VERSION ""

NS_ :

BS_:

BU_: L_3HKBD L_FHPTC L_ATCU L_2HKBD L_PCM L_HKBD L_RHPTC

BO_ 3221225472 VECTOR__INDEPENDENT_SIG_MSG: 0 Vector__XXX
 SG_ L_2HKBD_RrDrModeBiLvlSw : 0|1@1+ (1,0) [0|0] "" Vector__XXX
 SG_ L_2HKBD_RrDrTempDnSw : 0|1@1+ (1,0) [0|0] "" Vector__XXX
 SG_ L_2HKBD_RrDrTempUpSw : 0|1@1+ (1,0) [0|0] "" Vector__XXX
 SG_ L_2HKBD_RrDrBlwDnSw : 0|1@1+ (1,0) [0|0] "" Vector__XXX
 SG_ L_2HKBD_RrDrBlwUpSw : 0|1@1+ (1,0) [0|0] "" Vector__XXX
 SG_ L_2HKBD_RrFlrDuctSnsr : 0|8@1+ (0.02,0) [0|0] "V" Vector__XXX
 SG_ L_2HKBD_RrVntDuctSnsr : 0|8@1+ (0.02,0) [0|0] "V" Vector__XXX
 SG_ L_ATCU_Typ1 : 0|4@1+ (1,0) [0|0] "" Vector__XXX
 SG_ L_ATCU_Opt1 : 0|8@1+ (1,0) [0|0] "" Vector__XXX
 SG_ L_ATCU_Drv_SeatOptSta : 0|3@1+ (1,0) [0|0] "" Vector__XXX
 SG_ L_ATCU_Ast_SeatOptSta : 0|3@1+ (1,0) [0|0] "" Vector__XXX
 SG_ L_ATCU_RL_SeatOptSta : 0|3@1+ (1,0) [0|0] "" Vector__XXX
 SG_ L_ATCU_RR_SeatOptSta : 0|3@1+ (1,0) [0|0] "" Vector__XXX
 SG_ L_ATCU_Typ2 : 0|4@1+ (1,0) [0|0] "" Vector__XXX
 SG_ L_ATCU_Typ3 : 0|8@1+ (1,0) [0|0] "" Vector__XXX
 SG_ L_2HKBD_Rr_EvapVolVal : 0|8@1+ (0.02,0) [0|0] "" Vector__XXX
 SG_ L_2HKBD_Rr_TempActrSt : 0|2@1+ (1,0) [0|0] "" Vector__XXX
 SG_ L_2HKBD_Rr_TempAsstActrFB : 0|10@1+ (1,0) [0|0] "" Vector__XXX
 SG_ L_2HKBD_Rr_TempAsstActrSt : 0|2@1+ (1,0) [0|0] "" Vector__XXX
 SG_ L_2HKBD_Rr_ModeActrFB : 0|10@1+ (1,0) [0|0] "" Vector__XXX
 SG_ L_2HKBD_Rr_ModeActrSt : 0|2@1+ (1,0) [0|0] "" Vector__XXX
 SG_ L_2HKBD_Rr_BLDCError : 0|4@1+ (1,0) [0|0] "" Vector__XXX
 SG_ L_2HKBD_Rr_HVACBLDCRpmFB : 0|16@1+ (5,0) [0|0] "RPM" Vector__XXX
 SG_ L_2HKBD_Rr_TempActrFB : 0|10@1+ (1,0) [0|0] "" Vector__XXX
 SG_ L_ATCU_3rdRrTempCDis : 0|8@1+ (0.5,14) [0|0] "¡É" Vector__XXX
 SG_ L_ATCU_3rdRrModDis : 0|4@1+ (1,0) [0|0] "" Vector__XXX
 SG_ L_ATCU_3rdRrBlwDis : 0|4@1+ (1,0) [0|0] "" Vector__XXX
 SG_ L_ATCU_3rdRrAutoDis : 0|2@1+ (1,0) [0|0] "" Vector__XXX
 SG_ L_ATCU_3rdRrMultiAutoBlwDis : 0|3@1+ (1,0) [0|0] "" Vector__XXX
 SG_ L_ATCU_3rdRrSyncDis : 0|2@1+ (1,0) [0|0] "" Vector__XXX
 SG_ L_ATCU_3rdRrOnInd : 0|2@1+ (1,0) [0|0] "" Vector__XXX
 SG_ L_ATCU_3rdRrLockDis : 0|2@1+ (1,0) [0|0] "" Vector__XXX
 SG_ L_ATCU_3rdRrLcdBckLightSta : 0|1@1+ (1,0) [0|0] "" Vector__XXX
 SG_ L_ATCU_3rdRrGUIBlankDis : 0|1@1+ (1,0) [0|0] "" Vector__XXX
 SG_ L_ATCU_3rdRLStHeatSwHInd : 0|1@1+ (1,0) [0|0] "" Vector__XXX
 SG_ L_ATCU_3rdRLStHeatSwMInd : 0|1@1+ (1,0) [0|0] "" Vector__XXX
 SG_ L_ATCU_3rdRLStHeatSwLInd : 0|1@1+ (1,0) [0|0] "" Vector__XXX
 SG_ L_ATCU_3rdRLStVntSwHInd : 0|1@1+ (1,0) [0|0] "" Vector__XXX
 SG_ L_ATCU_3rdRLStVntSwMInd : 0|1@1+ (1,0) [0|0] "" Vector__XXX
 SG_ L_ATCU_3rdRLStVntSwLInd : 0|1@1+ (1,0) [0|0] "" Vector__XXX
 SG_ L_ATCU_3rdRRStHeatSwHInd : 0|1@1+ (1,0) [0|0] "" Vector__XXX
 SG_ L_ATCU_3rdRRStHeatSwMInd : 0|1@1+ (1,0) [0|0] "" Vector__XXX
 SG_ L_ATCU_3rdRRStHeatSwLInd : 0|1@1+ (1,0) [0|0] "" Vector__XXX
 SG_ L_ATCU_3rdRRStVntSwHInd : 0|1@1+ (1,0) [0|0] "" Vector__XXX
 SG_ L_ATCU_3rdRRStVntSwMInd : 0|1@1+ (1,0) [0|0] "" Vector__XXX
 SG_ L_ATCU_3rdRRStVntSwLInd : 0|1@1+ (1,0) [0|0] "" Vector__XXX
 SG_ L_ATCU_3rdRrMTCOpSta : 0|2@1+ (1,0) [0|0] "" Vector__XXX
 SG_ L_ATCU_3rdRrMtcTempLvl : 0|4@1+ (1,0) [0|0] "" Vector__XXX
 SG_ L_ATCU_3rdAUTOStep : 0|3@1+ (1,0) [0|0] "" Vector__XXX
 SG_ L_ATCU_RrPassMultiAutoBlwDis : 0|3@1+ (1,0) [0|0] "" Vector__XXX
 SG_ L_ATCU_3rdRrTempFDis : 0|8@1+ (1,56) [0|0] "¢µ" Vector__XXX
 SG_ L_2HKBD_SwBtnTyp : 0|20@1+ (1,0) [0|0] "" Vector__XXX
 SG_ L_ATCU_RrHVACTempActrTgt : 0|10@1+ (1,0) [0|0] "AD" Vector__XXX
 SG_ L_ATCU_RrHVACTempAsstActrTgt : 0|10@1+ (1,0) [0|0] "AD" Vector__XXX
 SG_ L_ATCU_RrHVACModeActrTgt : 0|10@1+ (1,0) [0|0] "AD" Vector__XXX
 SG_ L_ATCU_RrHVACBlowerTgtV : 0|8@1+ (0.1,0) [0|0] "V" Vector__XXX
 SG_ L_ATCU_RrHVACBLDCRpmVal : 0|16@1+ (5,0) [0|0] "RPM" Vector__XXX
 SG_ L_ATCU_RrHVACDiagBlwOn : 0|1@1+ (1,0) [0|0] "" Vector__XXX
 SG_ L_ATCU_RrHVACTempActrOpSta : 0|1@1+ (1,0) [0|0] "" Vector__XXX
 SG_ L_ATCU_RrHVACTempAsstActrOpSta : 0|1@1+ (1,0) [0|0] "" Vector__XXX
 SG_ L_ATCU_RrHVACModActrOpSta : 0|1@1+ (1,0) [0|0] "" Vector__XXX
 SG_ L_ATCU_ArClnIntroEvt : 0|1@1+ (1,0) [0|0] "" Vector__XXX
 SG_ L_ATCU_ArClnSmblClr : 0|4@1+ (1,0) [0|0] "" Vector__XXX
 SG_ L_ATCU_DustLevelDis : 0|3@1+ (1,0) [0|0] "" Vector__XXX
 SG_ L_ATCU_DustBarDisOff : 0|1@1+ (1,0) [0|0] "" Vector__XXX
 SG_ L_ATCU_DustSnrStepDis : 0|6@1+ (1,0) [0|0] "" Vector__XXX
 SG_ L_ATCU_FragStrhDis : 0|2@1+ (1,0) [0|0] "" Vector__XXX
 SG_ L_ATCU_FragKindDis : 0|3@1+ (1,0) [0|0] "" Vector__XXX
 SG_ L_ATCU_Frag1Inform : 0|4@1+ (1,0) [0|0] "" Vector__XXX
 SG_ L_ATCU_Frag2Inform : 0|4@1+ (1,0) [0|0] "" Vector__XXX
 SG_ L_ATCU_Frag1RemainDisp : 0|4@1+ (1,0) [0|0] "" Vector__XXX
 SG_ L_ATCU_Frag2RemainDisp : 0|4@1+ (1,0) [0|0] "" Vector__XXX
 SG_ L_ATCU_ArClnSmblTyp : 0|4@1+ (1,0) [0|0] "" Vector__XXX
 SG_ L_ATCU_FrtBlwMaxLvlVaild : 0|4@1+ (1,0) [0|0] "" Vector__XXX
 SG_ L_ATCU_OpSta : 0|3@1+ (1,0) [0|0] "" Vector__XXX
 SG_ L_ATCU_TempDispUnit : 0|2@1+ (1,0) [0|0] "" Vector__XXX
 SG_ L_ATCU_DrvAUTOStep : 0|4@1+ (1,0) [0|0] "" Vector__XXX
 SG_ L_ATCU_DiagCodeDis : 0|10@1+ (1,-1) [0|0] "" Vector__XXX
 SG_ L_2HKBD_Sw_Opt1 : 0|8@1+ (1,0) [0|0] "" Vector__XXX
 SG_ L_2HKBD_Typ2 : 0|8@1+ (1,0) [0|0] "" Vector__XXX
 SG_ L_2HKBD_Typ3 : 0|8@1+ (1,0) [0|0] "" Vector__XXX
 SG_ L_2HKBD_Typ1 : 0|8@1+ (1,0) [0|0] "" Vector__XXX
 SG_ L_ATCU_RrOpSta : 0|3@1+ (1,0) [0|0] "" Vector__XXX
 SG_ L_ATCU_RrDrvTempFDis : 0|8@1+ (1,56) [0|0] "¢µ" Vector__XXX
 SG_ L_ATCU_RrDrvModDis : 0|4@1+ (1,0) [0|0] "" Vector__XXX
 SG_ L_ATCU_RrDrvBlwDis : 0|4@1+ (1,0) [0|0] "" Vector__XXX
 SG_ L_ATCU_RrDrvAutoDis : 0|2@1+ (1,0) [0|0] "" Vector__XXX
 SG_ L_ATCU_RrDrvMultiAutoBlwDis : 0|2@1+ (1,0) [0|0] "" Vector__XXX
 SG_ L_ATCU_RrDrvTempCDis : 0|8@1+ (0.5,14) [0|0] "¡É" Vector__XXX
 SG_ L_ATCU_RrSyncDis : 0|2@1+ (1,0) [0|0] "" Vector__XXX
 SG_ L_ATCU_RrLcdBckLightSta : 0|1@1+ (1,0) [0|0] "" Vector__XXX
 SG_ L_ATCU_RrGUIBlankDis : 0|1@1+ (1,0) [0|0] "" Vector__XXX
 SG_ L_ATCU_RLStHeatSwHInd : 0|1@1+ (1,0) [0|0] "" Vector__XXX
 SG_ L_ATCU_RLStHeatSwMInd : 0|1@1+ (1,0) [0|0] "" Vector__XXX
 SG_ L_ATCU_RLStHeatSwLInd : 0|1@1+ (1,0) [0|0] "" Vector__XXX
 SG_ L_ATCU_RLStVntSwHInd : 0|1@1+ (1,0) [0|0] "" Vector__XXX
 SG_ L_ATCU_RLStVntSwMInd : 0|1@1+ (1,0) [0|0] "" Vector__XXX
 SG_ L_ATCU_RLStVntSwLInd : 0|1@1+ (1,0) [0|0] "" Vector__XXX
 SG_ L_ATCU_RRStHeatSwHInd : 0|1@1+ (1,0) [0|0] "" Vector__XXX
 SG_ L_ATCU_RRStHeatSwMInd : 0|1@1+ (1,0) [0|0] "" Vector__XXX
 SG_ L_ATCU_RRStHeatSwLInd : 0|1@1+ (1,0) [0|0] "" Vector__XXX
 SG_ L_ATCU_RRStVntSwHInd : 0|1@1+ (1,0) [0|0] "" Vector__XXX
 SG_ L_ATCU_RRStVntSwMInd : 0|1@1+ (1,0) [0|0] "" Vector__XXX
 SG_ L_ATCU_RRStVntSwLInd : 0|1@1+ (1,0) [0|0] "" Vector__XXX
 SG_ L_ATCU_RrMTCOpSta : 0|2@1+ (1,0) [0|0] "" Vector__XXX
 SG_ L_ATCU_RrMTCTempLvl : 0|4@1+ (1,0) [0|0] "" Vector__XXX
 SG_ L_ATCU_RrPsModDis : 0|4@1+ (1,0) [0|0] "" Vector__XXX
 SG_ L_ATCU_RrLockDis : 0|2@1+ (1,0) [0|0] "" Vector__XXX
 SG_ L_ATCU_RrDrvAutoStep : 0|4@1+ (1,0) [0|0] "" Vector__XXX
 SG_ L_ATCU_PassAUTOStep : 0|3@1+ (1,0) [0|0] "" Vector__XXX
 SG_ L_ATCU_RrPassTempFDis : 0|8@1+ (1,56) [0|0] "¢µ" Vector__XXX
 SG_ L_ATCU_RrPassBlwDis : 0|4@1+ (1,0) [0|0] "" Vector__XXX
 SG_ L_ATCU_RrPassAUTODis : 0|2@1+ (1,0) [0|0] "" Vector__XXX
 SG_ L_ATCU_RrPassAUTOStep : 0|3@1+ (1,0) [0|0] "" Vector__XXX
 SG_ L_ATCU_CampModeSta : 0|2@1+ (1,0) [0|0] "" Vector__XXX
 SG_ L_ATCU_RrPassTempCDis : 0|8@1+ (0.5,14) [0|0] "¡É" Vector__XXX
 SG_ L_ATCU_UtilModeUsmSta : 0|2@1+ (1,0) [0|0] "" Vector__XXX
 SG_ L_ATCU_OutTempDispC : 0|8@1+ (0.5,-41) [0|0] "¡É" Vector__XXX
 SG_ L_ATCU_DtntOutSta : 0|1@1+ (1,0) [0|0] "" Vector__XXX
 SG_ L_ATCU_AutoBrightSta : 0|8@1+ (1,0) [0|0] "" Vector__XXX
 SG_ L_ATCU_DustSnrVal : 0|10@1+ (1,0) [0|0] "um/m3" Vector__XXX
 SG_ L_ATCU_NotMinModeBrightSta : 0|8@1+ (1,0) [0|0] "" Vector__XXX
 SG_ L_ATCU_OutTempDispF : 0|8@1+ (1,-42) [0|0] "¢µ" Vector__XXX
 SG_ L_ATCU_SW_Ver1 : 0|7@1+ (1,0) [0|0] "" Vector__XXX
 SG_ L_ATCU_SW_Ver3 : 0|7@1+ (1,0) [0|0] "" Vector__XXX
 SG_ L_ATCU_SW_Ver4 : 0|7@1+ (1,0) [0|0] "" Vector__XXX
 SG_ L_ATCU_SW_Ver5 : 0|7@1+ (1,0) [0|0] "" Vector__XXX
 SG_ L_ATCU_SW_Ver2 : 0|7@1+ (1,0) [0|0] "" Vector__XXX
 SG_ L_ATCU_RHPTCOpPrmssnSta : 0|1@1+ (1,0) [0|0] "" Vector__XXX
 SG_ L_ATCU_xEV_BMSRomTyp2 : 0|3@1+ (1,0) [0|0] "" Vector__XXX
 SG_ L_ATCU_RHPTCFlrTrgtDty : 0|8@1+ (0.5,0) [0|0] "%" Vector__XXX
 SG_ L_ATCU_RHPTCDischrgReq : 0|1@1+ (1,0) [0|0] "" Vector__XXX
 SG_ L_ATCU_FltMsgTmOutRHPTC1 : 0|1@1+ (1,0) [0|0] "" Vector__XXX
 SG_ L_ATCU_FltMsgTmOutRHPTC2 : 0|1@1+ (1,0) [0|0] "" Vector__XXX
 SG_ L_ATCU_FltMsgTmOutRHPTC3 : 0|1@1+ (1,0) [0|0] "" Vector__XXX
 SG_ L_ATCU_FltMsgTmOutRHPTC4 : 0|1@1+ (1,0) [0|0] "" Vector__XXX
 SG_ L_ATCU_RrBlwLvl : 0|4@1+ (1,0) [0|0] "" Vector__XXX
 SG_ L_ATCU_RrBlwLvlSigVaildSta : 0|8@1+ (1,0) [0|0] "" Vector__XXX
 SG_ L_ATCU_OutTempSnsrVal2 : 0|8@1+ (0.5,-40) [0|0] "¡É" Vector__XXX
 SG_ L_ATCU_RHPTCRoofTrgtDty : 0|8@1+ (0.5,0) [0|0] "%" Vector__XXX
 SG_ L_ATCU_RrBlwFltSta : 0|1@1+ (1,0) [0|0] "" Vector__XXX
 SG_ RHPTC_FlrFlt : 0|1@1+ (1,0) [0|0] "" Vector__XXX
 SG_ RHPTC_FlrFltLVLow : 0|1@1+ (1,0) [0|0] "" Vector__XXX
 SG_ RHPTC_FlrFailLVSnr : 0|1@1+ (1,0) [0|0] "" Vector__XXX
 SG_ RHPTC_FlrFailCuFLRentSnr : 0|1@1+ (1,0) [0|0] "" Vector__XXX
 SG_ RHPTC_FlrrFailCoreTempSnr : 0|1@1+ (1,0) [0|0] "" Vector__XXX
 SG_ RHPTC_FlrFailPcbTempSnr : 0|1@1+ (1,0) [0|0] "" Vector__XXX
 SG_ RHPTC_FlrFailIGBT : 0|1@1+ (1,0) [0|0] "" Vector__XXX
 SG_ RHPTC_FlrFailOpenLoad : 0|1@1+ (1,0) [0|0] "" Vector__XXX
 SG_ RHPTC_FlrLtdOpCause : 0|8@1+ (1,0) [0|0] "" Vector__XXX
 SG_ RHPTC_FlrFltLVHigh : 0|1@1+ (1,0) [0|0] "" Vector__XXX
 SG_ RHPTC_FlrSwrVer : 0|8@1+ (1,0) [0|255] "" Vector__XXX
 SG_ RHPTC_FlrFltHVLow : 0|1@1+ (1,0) [0|0] "" Vector__XXX
 SG_ RHPTC_FlrFltHVHigh : 0|1@1+ (1,0) [0|0] "" Vector__XXX
 SG_ RHPTC_FlrFltOverCuFLRent : 0|1@1+ (1,0) [0|0] "" Vector__XXX
 SG_ RHPTC_FlrFltThermalShutDn : 0|1@1+ (1,0) [0|0] "" Vector__XXX
 SG_ RHPTC_FlrFltPcbThermalShutDn : 0|1@1+ (1,0) [0|0] "" Vector__XXX
 SG_ RHPTC_FlrFltMsgTmOutATCU : 0|1@1+ (1,0) [0|0] "" Vector__XXX
 SG_ RHPTC_FlrFailHVSnr : 0|1@1+ (1,0) [0|0] "" Vector__XXX
 SG_ RHPTC_FlrRdySta : 0|1@1+ (1,0) [0|0] "" Vector__XXX
 SG_ RHPTC_FlrOpSta : 0|2@1+ (1,0) [0|0] "" Vector__XXX
 SG_ RHPTC_FlrCnsmptPwr_W : 0|16@1+ (1,0) [0|10000] "W" Vector__XXX
 SG_ RHPTC_FlrCtrlTyp : 0|4@1+ (1,0) [0|0] "" Vector__XXX
 SG_ RHPTC_FlrVoltage_V : 0|8@1+ (4,0) [0|1000] "V" Vector__XXX
 SG_ RHPTC_FlrCuFlrent_A : 0|8@1+ (0.2,0) [0|50] "A" Vector__XXX
 SG_ RHPTC_FlrDutyFB_Pec : 0|8@1+ (0.5,0) [0|100] "%" Vector__XXX
 SG_ RHPTC_FlrDutyFB_IGBT : 0|8@1+ (0.5,0) [0|100] "%" Vector__XXX
 SG_ RHPTC_FlrCoreTemp_C : 0|8@1+ (1,-40) [-40|200] "¡É" Vector__XXX
 SG_ RHPTC_RoofFlt : 0|1@1+ (1,0) [0|0] "" Vector__XXX
 SG_ RHPTC_RoofFltLVLow : 0|1@1+ (1,0) [0|0] "" Vector__XXX
 SG_ RHPTC_RoofFailLVSnr : 0|1@1+ (1,0) [0|0] "" Vector__XXX
 SG_ RHPTC_RoofFailCuRoofentSnr : 0|1@1+ (1,0) [0|0] "" Vector__XXX
 SG_ RHPTC_RoofFailCoreTempSnr : 0|1@1+ (1,0) [0|0] "" Vector__XXX
 SG_ RHPTC_RoofFailPcbTempSnr : 0|1@1+ (1,0) [0|0] "" Vector__XXX
 SG_ RHPTC_RoofFailIGBT : 0|1@1+ (1,0) [0|0] "" Vector__XXX
 SG_ RHPTC_RoofFailOpenLoad : 0|1@1+ (1,0) [0|0] "" Vector__XXX
 SG_ RHPTC_RoofLtdOpCause : 0|8@1+ (1,0) [0|0] "" Vector__XXX
 SG_ RHPTC_RoofFltLVHigh : 0|1@1+ (1,0) [0|0] "" Vector__XXX
 SG_ RHPTC_RoofSwVer : 0|8@1+ (1,0) [0|255] "" Vector__XXX
 SG_ RHPTC_RoofFltHVLow : 0|1@1+ (1,0) [0|0] "" Vector__XXX
 SG_ RHPTC_CnsmptPwrTtl_W : 0|16@1+ (1,0) [0|10000] "W" Vector__XXX
 SG_ RHPTC_RoofFltHVHigh : 0|1@1+ (1,0) [0|0] "" Vector__XXX
 SG_ RHPTC_IntlkSta : 0|2@1+ (1,0) [0|0] "" Vector__XXX
 SG_ RHPTC_RoofFltOverCuRoofent : 0|1@1+ (1,0) [0|0] "" Vector__XXX
 SG_ RHPTC_RoofFltThermalShutDn : 0|1@1+ (1,0) [0|0] "" Vector__XXX
 SG_ RHPTC_RoofFltPcbThermalShutDn : 0|1@1+ (1,0) [0|0] "" Vector__XXX
 SG_ RHPTC_RoofFltMsgTmOutATCU : 0|1@1+ (1,0) [0|0] "" Vector__XXX
 SG_ RHPTC_RoofFailHVSnr : 0|1@1+ (1,0) [0|0] "" Vector__XXX
 SG_ RHPTC_RoofRdySta : 0|1@1+ (1,0) [0|0] "" Vector__XXX
 SG_ RHPTC_RoofOpSta : 0|2@1+ (1,0) [0|0] "" Vector__XXX
 SG_ RHPTC_RoofCnsmptPwr_W : 0|16@1+ (1,0) [0|10000] "W" Vector__XXX
 SG_ RHPTC_RoofVoltage_V : 0|8@1+ (4,0) [0|1000] "V" Vector__XXX
 SG_ RHPTC_RoofCtrlTyp : 0|4@1+ (1,0) [0|0] "" Vector__XXX
 SG_ RHPTC_RoofCuRoofent_A : 0|8@1+ (0.2,0) [0|50] "A" Vector__XXX
 SG_ RHPTC_RoofDutyFB_Pec : 0|8@1+ (0.5,0) [0|100] "%" Vector__XXX
 SG_ RHPTC_RoofDutyFB_IGBT : 0|8@1+ (0.5,0) [0|100] "%" Vector__XXX
 SG_ RHPTC_RoofCoreTemp_C : 0|8@1+ (1,-40) [-40|200] "¡É" Vector__XXX
 SG_ LOG_FHPTC_Index : 0|16@1+ (1,0) [0|1000] "" Vector__XXX

BO_ 1333 L_FHPTC_LOG: 8 Vector__XXX
 SG_ FHPTC_LogTime : 32|32@1+ (1,0) [0|0] "" Vector__XXX
 SG_ FHPTC_LogNo : 0|32@1+ (1,0) [0|0] "" Vector__XXX

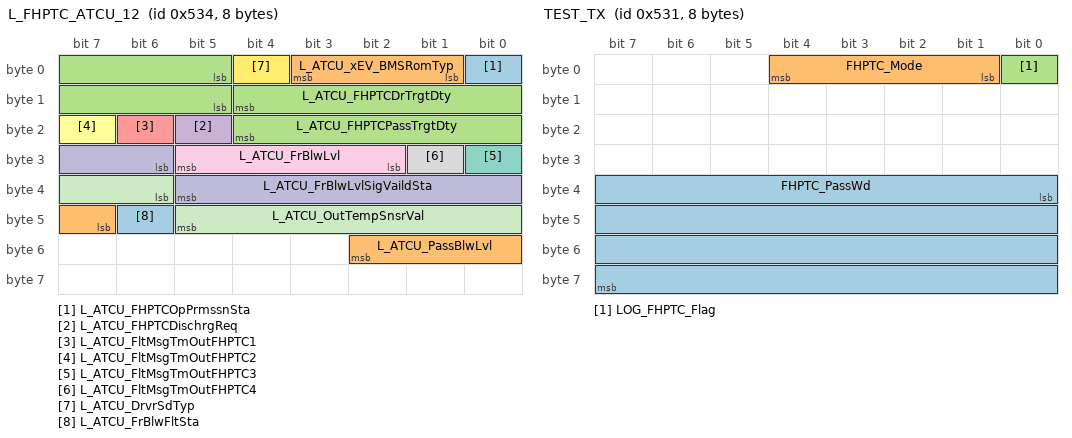
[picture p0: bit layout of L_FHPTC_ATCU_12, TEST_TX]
BO_ 1332 L_FHPTC_ATCU_12: 8 Vector__XXX
 SG_ L_ATCU_FHPTCOpPrmssnSta : 0|1@1+ (1,0) [0|0] "" Vector__XXX
 SG_ L_ATCU_xEV_BMSRomTyp : 1|3@1+ (1,0) [0|0] "" Vector__XXX
 SG_ L_ATCU_FHPTCPassTrgtDty : 13|8@1+ (0.5,0) [0|0] "%" Vector__XXX
 SG_ L_ATCU_FHPTCDischrgReq : 21|1@1+ (1,0) [0|0] "" Vector__XXX
 SG_ L_ATCU_FltMsgTmOutFHPTC1 : 22|1@1+ (1,0) [0|0] "" Vector__XXX
 SG_ L_ATCU_FltMsgTmOutFHPTC2 : 23|1@1+ (1,0) [0|0] "" Vector__XXX
 SG_ L_ATCU_FltMsgTmOutFHPTC3 : 24|1@1+ (1,0) [0|0] "" Vector__XXX
 SG_ L_ATCU_FltMsgTmOutFHPTC4 : 25|1@1+ (1,0) [0|0] "" Vector__XXX
 SG_ L_ATCU_FrBlwLvl : 26|4@1+ (1,0) [0|0] "" Vector__XXX
 SG_ L_ATCU_FrBlwLvlSigVaildSta : 30|8@1+ (1,0) [0|0] "" Vector__XXX
 SG_ L_ATCU_OutTempSnsrVal : 38|8@1+ (0.5,-40) [0|0] "¡É" Vector__XXX
 SG_ L_ATCU_DrvrSdTyp : 4|1@1+ (1,0) [0|0] "" Vector__XXX
 SG_ L_ATCU_FrBlwFltSta : 46|1@1+ (1,0) [0|0] "" Vector__XXX
 SG_ L_ATCU_PassBlwLvl : 47|4@1+ (1,0) [0|0] "" Vector__XXX
 SG_ L_ATCU_FHPTCDrTrgtDty : 5|8@1+ (0.5,0) [0|0] "%" Vector__XXX

BO_ 1329 TEST_TX: 8 Vector__XXX
 SG_ FHPTC_PassWd : 32|32@1+ (1,0) [0|0] "1" Vector__XXX
 SG_ FHPTC_Mode : 1|4@1+ (1,0) [0|15] "" Vector__XXX
 SG_ LOG_FHPTC_Flag : 0|1@1+ (1,0) [0|0] "" Vector__XXX

BO_ 1328 Simulation: 8 Vector__XXX
 SG_ SIM_FHPTC_IntlkSta : 25|1@1+ (1,0) [0|0] "" Vector__XXX
 SG_ SIM_FHPTC_FltMsgTmOutATCU : 24|1@1+ (1,0) [0|0] "" Vector__XXX
 SG_ SIM_FHPTC_PassFltOverCurrent : 10|1@1+ (1,0) [0|0] "" Vector__XXX
 SG_ SIM_FHPTC_PassFailIGBT : 12|1@1+ (1,0) [0|0] "" Vector__XXX
 SG_ SIM_FHPTC_PassFltThermalShutDn : 11|1@1+ (1,0) [0|0] "" Vector__XXX
 SG_ SIM_FHPTC_FltPcbThermalShutDn : 20|1@1+ (1,0) [0|0] "" Vector__XXX
 SG_ SIM_FHPTC_FltLVLow : 16|1@1+ (1,0) [0|0] "" Vector__XXX
 SG_ SIM_FHPTC_FltLVHigh : 17|1@1+ (1,0) [0|0] "" Vector__XXX
 SG_ SIM_FHPTC_FltHVLow : 18|1@1+ (1,0) [0|0] "" Vector__XXX
 SG_ SIM_FHPTC_FltHVHigh : 19|1@1+ (1,0) [0|0] "" Vector__XXX
 SG_ SIM_FHPTC_DrFltOverCurrent : 2|1@1+ (1,0) [0|0] "" Vector__XXX
 SG_ SIM_FHPTC_DrFailIGBT : 4|1@1+ (1,0) [0|0] "" Vector__XXX
 SG_ SIM_FHPTC_DrFltThermalShutDn : 3|1@1+ (1,0) [0|0] "" Vector__XXX
 SG_ SIM_FHPTC_PassFailCurrentSnr : 9|1@1+ (1,0) [0|0] "" Vector__XXX
 SG_ SIM_FHPTC_PassFailCoreTempSnr : 8|1@1+ (1,0) [0|0] "" Vector__XXX
 SG_ SIM_FHPTC_FailPcbTempSnr : 23|1@1+ (1,0) [0|0] "" Vector__XXX
 SG_ SIM_FHPTC_FailLVSnr : 21|1@1+ (1,0) [0|0] "" Vector__XXX
 SG_ SIM_FHPTC_FailHVSnr : 22|1@1+ (1,0) [0|0] "" Vector__XXX
 SG_ SIM_FHPTC_DrFailCurrentSnr : 1|1@1+ (1,0) [0|0] "" Vector__XXX
 SG_ SIM_FHPTC_DrFailCoreTempSnr : 0|1@1+ (1,0) [0|0] "" Vector__XXX

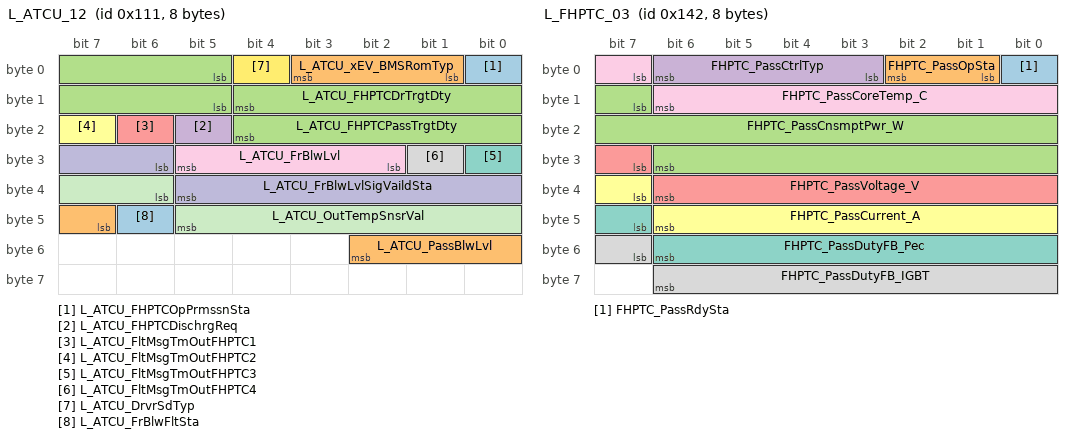
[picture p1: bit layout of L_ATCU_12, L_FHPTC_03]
BO_ 273 L_ATCU_12: 8 L_ATCU
 SG_ L_ATCU_FHPTCOpPrmssnSta : 0|1@1+ (1,0) [0|0] ""  L_FHPTC,L_RHPTC
 SG_ L_ATCU_xEV_BMSRomTyp : 1|3@1+ (1,0) [0|0] ""  L_FHPTC,L_RHPTC
 SG_ L_ATCU_FHPTCPassTrgtDty : 13|8@1+ (0.5,0) [0|0] "%"  L_FHPTC,L_RHPTC
 SG_ L_ATCU_FHPTCDischrgReq : 21|1@1+ (1,0) [0|0] ""  L_FHPTC,L_RHPTC
 SG_ L_ATCU_FltMsgTmOutFHPTC1 : 22|1@1+ (1,0) [0|0] ""  L_FHPTC,L_RHPTC
 SG_ L_ATCU_FltMsgTmOutFHPTC2 : 23|1@1+ (1,0) [0|0] ""  L_FHPTC,L_RHPTC
 SG_ L_ATCU_FltMsgTmOutFHPTC3 : 24|1@1+ (1,0) [0|0] ""  L_FHPTC,L_RHPTC
 SG_ L_ATCU_FltMsgTmOutFHPTC4 : 25|1@1+ (1,0) [0|0] ""  L_FHPTC,L_RHPTC
 SG_ L_ATCU_FrBlwLvl : 26|4@1+ (1,0) [0|0] ""  L_FHPTC,L_RHPTC
 SG_ L_ATCU_FrBlwLvlSigVaildSta : 30|8@1+ (1,0) [0|0] ""  L_FHPTC,L_RHPTC
 SG_ L_ATCU_OutTempSnsrVal : 38|8@1+ (0.5,-40) [0|0] "¡É"  L_FHPTC,L_RHPTC
 SG_ L_ATCU_DrvrSdTyp : 4|1@1+ (1,0) [0|0] ""  L_FHPTC,L_RHPTC
 SG_ L_ATCU_FrBlwFltSta : 46|1@1+ (1,0) [0|0] ""  L_FHPTC,L_RHPTC
 SG_ L_ATCU_PassBlwLvl : 47|4@1+ (1,0) [0|0] ""  L_FHPTC,L_RHPTC
 SG_ L_ATCU_FHPTCDrTrgtDty : 5|8@1+ (0.5,0) [0|0] "%"  L_FHPTC,L_RHPTC

BO_ 322 L_FHPTC_03: 8 L_FHPTC
 SG_ FHPTC_PassRdySta : 0|1@1+ (1,0) [0|0] ""  L_ATCU
 SG_ FHPTC_PassOpSta : 1|2@1+ (1,0) [0|0] ""  L_ATCU
 SG_ FHPTC_PassCnsmptPwr_W : 15|16@1+ (1,0) [0|10000] "W"  L_ATCU
 SG_ FHPTC_PassCtrlTyp : 3|4@1+ (1,0) [0|0] ""  L_ATCU
 SG_ FHPTC_PassVoltage_V : 31|8@1+ (4,0) [0|1000] "V"  L_ATCU
 SG_ FHPTC_PassCurrent_A : 39|8@1+ (0.2,0) [0|50] "A"  L_ATCU
 SG_ FHPTC_PassDutyFB_Pec : 47|8@1+ (0.5,0) [0|100] "%"  L_ATCU
 SG_ FHPTC_PassDutyFB_IGBT : 55|8@1+ (0.5,0) [0|100] "%"  L_ATCU
 SG_ FHPTC_PassCoreTemp_C : 7|8@1+ (1,-40) [-40|200] "¡É"  L_ATCU

BO_ 323 L_FHPTC_04: 8 L_FHPTC
 SG_ FHPTC_PassLogHalt : 56|1@1+ (1,0) [0|0] "" Vector__XXX
 SG_ FHPTC_PassFlt : 0|1@1+ (1,0) [0|0] ""  L_ATCU
 SG_ FHPTC_PassFltLVLow : 1|1@1+ (1,0) [0|0] ""  L_ATCU
 SG_ FHPTC_PassFailLVSnr : 10|1@1+ (1,0) [0|0] ""  L_ATCU
 SG_ FHPTC_PassFailCurrentSnr : 11|1@1+ (1,0) [0|0] ""  L_ATCU
 SG_ FHPTC_PassFailCoreTempSnr : 12|1@1+ (1,0) [0|0] ""  L_ATCU
 SG_ FHPTC_PassFailPcbTempSnr : 13|1@1+ (1,0) [0|0] ""  L_ATCU
 SG_ FHPTC_PassFailIGBT : 14|1@1+ (1,0) [0|0] ""  L_ATCU
 SG_ FHPTC_PassFailOpenLoad : 15|1@1+ (1,0) [0|0] ""  L_ATCU
 SG_ FHPTC_PassLtdOpCause : 16|8@1+ (1,0) [0|0] ""  L_ATCU
 SG_ FHPTC_PassFltLVHigh : 2|1@1+ (1,0) [0|0] ""  L_ATCU
 SG_ FHPTC_PassSwVer : 24|8@1+ (1,0) [0|255] ""  L_ATCU
 SG_ FHPTC_PassFltHVLow : 3|1@1+ (1,0) [0|0] ""  L_ATCU
 SG_ FHPTC_PassFltHVHigh : 4|1@1+ (1,0) [0|0] ""  L_ATCU
 SG_ FHPTC_PassFltOverCurrent : 5|1@1+ (1,0) [0|0] ""  L_ATCU
 SG_ FHPTC_PassFltThermalShutDn : 6|1@1+ (1,0) [0|0] ""  L_ATCU
 SG_ FHPTC_PassFltPcbThermalShutDn : 7|1@1+ (1,0) [0|0] ""  L_ATCU
 SG_ FHPTC_PassFltMsgTmOutATCU : 8|1@1+ (1,0) [0|0] ""  L_ATCU
 SG_ FHPTC_PassFailHVSnr : 9|1@1+ (1,0) [0|0] ""  L_ATCU

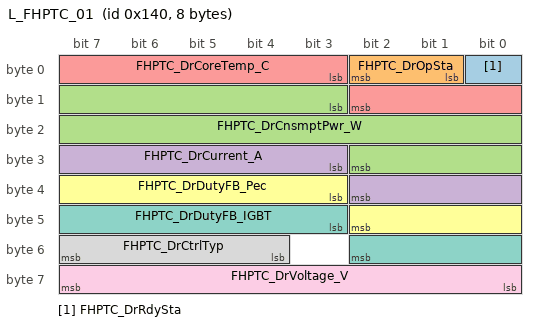
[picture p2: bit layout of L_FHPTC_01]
BO_ 320 L_FHPTC_01: 8 L_FHPTC
 SG_ FHPTC_DrRdySta : 0|1@1+ (1,0) [0|0] ""  L_ATCU
 SG_ FHPTC_DrOpSta : 1|2@1+ (1,0) [0|0] ""  L_ATCU
 SG_ FHPTC_DrCnsmptPwr_W : 11|16@1+ (1,0) [0|10000] "W"  L_ATCU
 SG_ FHPTC_DrCurrent_A : 27|8@1+ (0.2,0) [0|50] "A"  L_ATCU
 SG_ FHPTC_DrCoreTemp_C : 3|8@1+ (1,-40) [-40|200] "¡É"  L_ATCU
 SG_ FHPTC_DrDutyFB_Pec : 35|8@1+ (0.5,0) [0|100] "%"  L_ATCU
 SG_ FHPTC_DrDutyFB_IGBT : 43|8@1+ (0.5,0) [0|100] "%"  L_ATCU
 SG_ FHPTC_DrCtrlTyp : 52|4@1+ (1,0) [0|0] ""  L_ATCU
 SG_ FHPTC_DrVoltage_V : 56|8@1+ (4,0) [0|1000] "V"  L_ATCU

BO_ 321 L_FHPTC_02: 8 L_FHPTC
 SG_ FHPTC_DrLogHalt : 56|1@1+ (1,0) [0|0] "" Vector__XXX
 SG_ FHPTC_DrFlt : 0|1@1+ (1,0) [0|0] ""  L_ATCU
 SG_ FHPTC_DrFltLVLow : 1|1@1+ (1,0) [0|0] ""  L_ATCU
 SG_ FHPTC_DrFailLVSnr : 10|1@1+ (1,0) [0|0] ""  L_ATCU
 SG_ FHPTC_DrFailCurrentSnr : 11|1@1+ (1,0) [0|0] ""  L_ATCU
 SG_ FHPTC_DrFailCoreTempSnr : 12|1@1+ (1,0) [0|0] ""  L_ATCU
 SG_ FHPTC_DrFailPcbTempSnr : 13|1@1+ (1,0) [0|0] ""  L_ATCU
 SG_ FHPTC_DrFailIGBT : 14|1@1+ (1,0) [0|0] ""  L_ATCU
 SG_ FHPTC_DrFailOpenLoad : 15|1@1+ (1,0) [0|0] ""  L_ATCU
 SG_ FHPTC_DrLtdOpCause : 16|8@1+ (1,0) [0|0] ""  L_ATCU
 SG_ FHPTC_DrFltLVHigh : 2|1@1+ (1,0) [0|0] ""  L_ATCU
 SG_ FHPTC_DrSwVer : 24|8@1+ (1,0) [0|0] ""  L_ATCU
 SG_ FHPTC_DrFltHVLow : 3|1@1+ (1,0) [0|0] ""  L_ATCU
 SG_ FHPTC_CnsmptPwrTtl_W : 32|16@1+ (1,0) [0|10000] "W"  L_ATCU
 SG_ FHPTC_DrFltHVHigh : 4|1@1+ (1,0) [0|0] ""  L_ATCU
 SG_ FHPTC_IntlkSta : 48|2@1+ (1,0) [0|0] ""  L_ATCU
 SG_ FHPTC_DrFltOverCurrent : 5|1@1+ (1,0) [0|0] ""  L_ATCU
 SG_ FHPTC_DrFltThermalShutDn : 6|1@1+ (1,0) [0|0] ""  L_ATCU
 SG_ FHPTC_DrFltPcbThermalShutDn : 7|1@1+ (1,0) [0|0] ""  L_ATCU
 SG_ FHPTC_DrFltMsgTmOutATCU : 8|1@1+ (1,0) [0|0] ""  L_ATCU
 SG_ FHPTC_DrFailHVSnr : 9|1@1+ (1,0) [0|0] ""  L_ATCU

CM_ SG_ 3221225472 L_2HKBD_RrDrModeBiLvlSw "2HKBD_RearDriverModeBiLevelSwitch";
CM_ SG_ 3221225472 L_2HKBD_RrDrTempDnSw "2HKBD_RearDriverTempDownSwitch";
CM_ SG_ 3221225472 L_2HKBD_RrDrTempUpSw "2HKBD_RearDriverTempUpSwitch";
CM_ SG_ 3221225472 L_2HKBD_RrDrBlwDnSw "2HKBD_RearDriverBlowerDownSwitch";
CM_ SG_ 3221225472 L_2HKBD_RrDrBlwUpSw "2HKBD_RearDriverBlowerUpSwitch";
CM_ SG_ 3221225472 L_2HKBD_RrFlrDuctSnsr "2HKBD_RearFloorDuctSensor";
CM_ SG_ 3221225472 L_2HKBD_RrVntDuctSnsr "2HKBD_RearVentDuctSensor";
CM_ SG_ 3221225472 L_ATCU_Typ1 "ATCU_Type1";
CM_ SG_ 3221225472 L_ATCU_Opt1 "ATCU_Option1";
CM_ SG_ 3221225472 L_ATCU_Drv_SeatOptSta "ATCU_Drvier_SeatOptionStaus";
CM_ SG_ 3221225472 L_ATCU_Ast_SeatOptSta "ATCU_Ast_SeatOptionStatus";
CM_ SG_ 3221225472 L_ATCU_RL_SeatOptSta "ATCU_RearLeft_SeatOptionStatus";
CM_ SG_ 3221225472 L_ATCU_RR_SeatOptSta "ATCU_RearRight_SeatOperationStatus";
CM_ SG_ 3221225472 L_ATCU_Typ2 "ATCU_Type2";
CM_ SG_ 3221225472 L_ATCU_Typ3 "ATCU_Type3";
CM_ SG_ 3221225472 L_2HKBD_Rr_EvapVolVal "2HKBD_Rear_EvaporatorVoltageValue";
CM_ SG_ 3221225472 L_2HKBD_Rr_TempActrSt "2HKBD_Rear_TemperatureActuatorStatus";
CM_ SG_ 3221225472 L_2HKBD_Rr_TempAsstActrFB "2HKBD_Rear_TemperatureAssistActuatorFeedback";
CM_ SG_ 3221225472 L_2HKBD_Rr_TempAsstActrSt "2HKBD_Rear_TemperatureAssistActuatorStatus";
CM_ SG_ 3221225472 L_2HKBD_Rr_ModeActrFB "2HKBD_Rear_ModeActuatorFeedback";
CM_ SG_ 3221225472 L_2HKBD_Rr_ModeActrSt "2HKBD_Rear_ModeActuatorStatus";
CM_ SG_ 3221225472 L_2HKBD_Rr_BLDCError "2HKBD_Rear_BLDCError";
CM_ SG_ 3221225472 L_2HKBD_Rr_HVACBLDCRpmFB "2HKBD_Rear_HVACBLDCRpmFeedBack";
CM_ SG_ 3221225472 L_2HKBD_Rr_TempActrFB "2HKBD_Rear_TemperatureActuatorFeedback";
CM_ SG_ 3221225472 L_ATCU_3rdRrTempCDis "ATCU_3rdRearTemperature¡ÉDisplay";
CM_ SG_ 3221225472 L_ATCU_3rdRrModDis "ATCU_3rdRearModeDisplay";
CM_ SG_ 3221225472 L_ATCU_3rdRrBlwDis "ATCU_3rdRearBlowerDisplay";
CM_ SG_ 3221225472 L_ATCU_3rdRrAutoDis "ATCU_3rdRearAutoDisplay";
CM_ SG_ 3221225472 L_ATCU_3rdRrMultiAutoBlwDis "ATCU_3rdRearMultiAutoBlowerDisplay";
CM_ SG_ 3221225472 L_ATCU_3rdRrSyncDis "ATCU_3rdRearSyncDisplay";
CM_ SG_ 3221225472 L_ATCU_3rdRrOnInd "ATCU_3rdRearONIndicator";
CM_ SG_ 3221225472 L_ATCU_3rdRrLockDis "ATCU_3rdRearLockDisplay";
CM_ SG_ 3221225472 L_ATCU_3rdRrLcdBckLightSta "ATCU_3rdRearLCDBackLightStatus";
CM_ SG_ 3221225472 L_ATCU_3rdRrGUIBlankDis "ATCU_3rdRearGUIBlankDisplay";
CM_ SG_ 3221225472 L_ATCU_3rdRLStHeatSwHInd "ATCU_3rdRearLeftSeatHeatSwitchHighIndicator";
CM_ SG_ 3221225472 L_ATCU_3rdRLStHeatSwMInd "ATCU_3rdRearLeftSeatHeatSwitchMiddleIndicator";
CM_ SG_ 3221225472 L_ATCU_3rdRLStHeatSwLInd "ATCU_3rdRearLeftSeatHeatSwitchLowIndicator";
CM_ SG_ 3221225472 L_ATCU_3rdRLStVntSwHInd "ATCU_3rdRearLeftSeatVentilationSwitchHighIndicator";
CM_ SG_ 3221225472 L_ATCU_3rdRLStVntSwMInd "ATCU_3rdRearLeftSeatVentilationSwitchMiddleIndicator";
CM_ SG_ 3221225472 L_ATCU_3rdRLStVntSwLInd "ATCU_3rdRearLeftSeatVentilationSwitchLowIndicator";
CM_ SG_ 3221225472 L_ATCU_3rdRRStHeatSwHInd "ATCU_3rdRearRightSeatHeatSwitchHighIndicator";
CM_ SG_ 3221225472 L_ATCU_3rdRRStHeatSwMInd "ATCU_3rdRearRightSeatHeatSwitchMiddleIndicator";
CM_ SG_ 3221225472 L_ATCU_3rdRRStHeatSwLInd "ATCU_3rdRearRightSeatHeatSwitchLowIndicator";
CM_ SG_ 3221225472 L_ATCU_3rdRRStVntSwHInd "ATCU_3rdRearRightSeatVentilationSwitchHighIndicator";
CM_ SG_ 3221225472 L_ATCU_3rdRRStVntSwMInd "ATCU_3rdRearRightSeatVentilationSwitchMiddleIndicator";
CM_ SG_ 3221225472 L_ATCU_3rdRRStVntSwLInd "ATCU_3rdRearRightSeatVentilationSwitchLowIndicator";
CM_ SG_ 3221225472 L_ATCU_3rdRrMTCOpSta "ATCU_3rdRearMTCOperationStatus";
CM_ SG_ 3221225472 L_ATCU_3rdRrMtcTempLvl "ATCU_3rdRearMTCTemperatureLevel";
CM_ SG_ 3221225472 L_ATCU_3rdAUTOStep "ATCU_3rdAUTOStep";
CM_ SG_ 3221225472 L_ATCU_RrPassMultiAutoBlwDis "ATCU_RrPassengerMultiAutoBlowerDisplay";
CM_ SG_ 3221225472 L_ATCU_3rdRrTempFDis "ATCU_3rdRearTemperature¢µDisplay";
CM_ SG_ 3221225472 L_2HKBD_SwBtnTyp "2HKBD-SwitchButtonType";
CM_ SG_ 3221225472 L_ATCU_RrHVACTempActrTgt "ATCU_RearHVACTemperatureActuatorTarget";
CM_ SG_ 3221225472 L_ATCU_RrHVACTempAsstActrTgt "ATCU_RearHVCACTempAsstanceActuatorTarget";
CM_ SG_ 3221225472 L_ATCU_RrHVACModeActrTgt "ATCU_RearHVACModeActuatorTarget";
CM_ SG_ 3221225472 L_ATCU_RrHVACBlowerTgtV "ATCU_RearHVACBlowerTargetVoltage";
CM_ SG_ 3221225472 L_ATCU_RrHVACBLDCRpmVal "ATCU_RearHVAC BLDC Motor RPM Value";
CM_ SG_ 3221225472 L_ATCU_RrHVACDiagBlwOn "ATCU_RearHVACDiagnosticBlowerOn";
CM_ SG_ 3221225472 L_ATCU_RrHVACTempActrOpSta "ATCU_RrHVACTempActuatorOperationStatus";
CM_ SG_ 3221225472 L_ATCU_RrHVACTempAsstActrOpSta "ATCU_RrHVACTempAsstanceActuatorOperationStatus";
CM_ SG_ 3221225472 L_ATCU_RrHVACModActrOpSta "ATCU_RrHVACModeActuatorOperationStatus";
CM_ SG_ 3221225472 L_ATCU_ArClnIntroEvt "ATCU_AirCleaningIntroEvent";
CM_ SG_ 3221225472 L_ATCU_ArClnSmblClr "ATCU_AirCleaningSymbolColor";
CM_ SG_ 3221225472 L_ATCU_DustLevelDis "ATCU_DustLevelDisplay";
CM_ SG_ 3221225472 L_ATCU_DustBarDisOff "ATCU_DustBarDisplayOff";
CM_ SG_ 3221225472 L_ATCU_DustSnrStepDis "ATCU_DustSensorStepDisplay";
CM_ SG_ 3221225472 L_ATCU_FragStrhDis "ATCU_FragStrengthDisplay";
CM_ SG_ 3221225472 L_ATCU_FragKindDis "ATCU_FragKindDisplay";
CM_ SG_ 3221225472 L_ATCU_Frag1Inform "ATCU_Frag1Information";
CM_ SG_ 3221225472 L_ATCU_Frag2Inform "ATCU_Frag2Information";
CM_ SG_ 3221225472 L_ATCU_Frag1RemainDisp "ATCU_Frag1RemainDisplay";
CM_ SG_ 3221225472 L_ATCU_Frag2RemainDisp "ATCU_Frag2RemainDisplay";
CM_ SG_ 3221225472 L_ATCU_ArClnSmblTyp "ATCU_AircCleaningSymbolType";
CM_ SG_ 3221225472 L_ATCU_FrtBlwMaxLvlVaild "ATCU_FrontBlowerMaxLevelVaild";
CM_ SG_ 3221225472 L_ATCU_OpSta "ATCU_OperationStatus";
CM_ SG_ 3221225472 L_ATCU_TempDispUnit "ATCU_TemperatureDisplayUnit";
CM_ SG_ 3221225472 L_ATCU_DrvAUTOStep "ATCU_DriverAutoStep";
CM_ SG_ 3221225472 L_ATCU_DiagCodeDis "ATCU_DiagCodeDisplay";
CM_ SG_ 3221225472 L_2HKBD_Sw_Opt1 "2HKBD_Switch_Option1";
CM_ SG_ 3221225472 L_2HKBD_Typ2 "2HKBD_Type2";
CM_ SG_ 3221225472 L_2HKBD_Typ3 "2HKBD_Type3";
CM_ SG_ 3221225472 L_2HKBD_Typ1 "2HKBD_Type1";
CM_ SG_ 3221225472 L_ATCU_RrOpSta "ATCU_RearOperationStatus";
CM_ SG_ 3221225472 L_ATCU_RrDrvTempFDis "ATCU_RearDriverTemperature¢µDisplay";
CM_ SG_ 3221225472 L_ATCU_RrDrvModDis "ATCU_RearDriverModeDisplay";
CM_ SG_ 3221225472 L_ATCU_RrDrvBlwDis "ATCU_RearDriverBlowerDisplay";
CM_ SG_ 3221225472 L_ATCU_RrDrvAutoDis "ATCU_RearDriverAutoDisplay";
CM_ SG_ 3221225472 L_ATCU_RrDrvMultiAutoBlwDis "ATCU_RearDriverMultiAutoBlowerDisplay";
CM_ SG_ 3221225472 L_ATCU_RrDrvTempCDis "ATCU_RearDriverTemperature¡ÉDisplay";
CM_ SG_ 3221225472 L_ATCU_RrSyncDis "ATCU_RearSyncDisplay";
CM_ SG_ 3221225472 L_ATCU_RrLcdBckLightSta "ATCU_RearLCDBackLightStatus";
CM_ SG_ 3221225472 L_ATCU_RrGUIBlankDis "ATCU_RearGUIBlankDisplay";
CM_ SG_ 3221225472 L_ATCU_RLStHeatSwHInd "ATCU_RearLeftSeatHeatSwitchHighIndicator";
CM_ SG_ 3221225472 L_ATCU_RLStHeatSwMInd "ATCU_RearLeftSeatHeatSwitchMiddleIndicator";
CM_ SG_ 3221225472 L_ATCU_RLStHeatSwLInd "ATCU_RearLeftSeatHeatSwitchLowIndicator";
CM_ SG_ 3221225472 L_ATCU_RLStVntSwHInd "ATCU_RearLeftSeatVentilationSwitchHighIndicator";
CM_ SG_ 3221225472 L_ATCU_RLStVntSwMInd "ATCU_RearLeftSeatVentilationSwitchMiddleIndicator";
CM_ SG_ 3221225472 L_ATCU_RLStVntSwLInd "ATCU_RearLeftSeatVentilationSwitchLowIndicator";
CM_ SG_ 3221225472 L_ATCU_RRStHeatSwHInd "ATCU_RearRightSeatHeatSwitchHighIndicator";
CM_ SG_ 3221225472 L_ATCU_RRStHeatSwMInd "ATCU_RearRightSeatHeatSwitchMiddleIndicator";
CM_ SG_ 3221225472 L_ATCU_RRStHeatSwLInd "ATCU_RearRightSeatHeatSwitchLowIndicator";
CM_ SG_ 3221225472 L_ATCU_RRStVntSwHInd "ATCU_RearRightSeatVentilationSwitchHighIndicator";
CM_ SG_ 3221225472 L_ATCU_RRStVntSwMInd "ATCU_RearRightSeatVentilationSwitchMiddleIndicator";
CM_ SG_ 3221225472 L_ATCU_RRStVntSwLInd "ATCU_RearRightSeatVentilationSwitchLowIndicator";
CM_ SG_ 3221225472 L_ATCU_RrMTCOpSta "ATCU_RearMTCOperationStatus";
CM_ SG_ 3221225472 L_ATCU_RrMTCTempLvl "ATCU_RearMTCTempLevel";
CM_ SG_ 3221225472 L_ATCU_RrPsModDis "ATCU_RearPassengerModeDisplay";
CM_ SG_ 3221225472 L_ATCU_RrLockDis "ATCU_RearLockDisplay";
CM_ SG_ 3221225472 L_ATCU_RrDrvAutoStep "ATCU_RearDriverAutoStep";
CM_ SG_ 3221225472 L_ATCU_PassAUTOStep "ATCU_PassAUTOStep";
CM_ SG_ 3221225472 L_ATCU_RrPassTempFDis "ATCU_RrPassTempFDisplay";
CM_ SG_ 3221225472 L_ATCU_RrPassBlwDis "ATCU_RrPassBlwDis";
CM_ SG_ 3221225472 L_ATCU_RrPassAUTODis "ATCU_RrPassAUTODis";
CM_ SG_ 3221225472 L_ATCU_RrPassAUTOStep "ATCU_RrPassAUTOStep";
CM_ SG_ 3221225472 L_ATCU_CampModeSta "ATCU_CampModeStatus";
CM_ SG_ 3221225472 L_ATCU_RrPassTempCDis "ATCU_RrPassTempCDisplay";
CM_ SG_ 3221225472 L_ATCU_UtilModeUsmSta "ATCU_UtilityModeUSMStatus";
CM_ SG_ 3221225472 L_ATCU_OutTempDispC "ATCU_OutTemperatureDisplay(¡É)";
CM_ SG_ 3221225472 L_ATCU_DtntOutSta "ATCU_DetentOutStatus";
CM_ SG_ 3221225472 L_ATCU_AutoBrightSta "ATCU_AutoBrightStatus";
CM_ SG_ 3221225472 L_ATCU_DustSnrVal "ATCU_DustSensorValue";
CM_ SG_ 3221225472 L_ATCU_NotMinModeBrightSta "ATCU_NotMinimumModeBrightStatus";
CM_ SG_ 3221225472 L_ATCU_OutTempDispF "ATCU_OutTemperatureDisplay(¢µ)";
CM_ SG_ 3221225472 L_ATCU_SW_Ver1 "ATCU_SoftWare_Version1";
CM_ SG_ 3221225472 L_ATCU_SW_Ver3 "ATCU_SoftWare_Version3";
CM_ SG_ 3221225472 L_ATCU_SW_Ver4 "ATCU_SoftWare_Version4";
CM_ SG_ 3221225472 L_ATCU_SW_Ver5 "ATCU_SoftWare_Version5";
CM_ SG_ 3221225472 L_ATCU_SW_Ver2 "ATCU_SoftWare_Version2";
CM_ SG_ 3221225472 L_ATCU_RHPTCOpPrmssnSta "ATCU_RHPTCOperationPermissionStatus";
CM_ SG_ 3221225472 L_ATCU_xEV_BMSRomTyp2 "ATCU_xEV_BMSRomType2";
CM_ SG_ 3221225472 L_ATCU_RHPTCFlrTrgtDty "ATCU_RHPTCFloorTargetDuty";
CM_ SG_ 3221225472 L_ATCU_RHPTCDischrgReq "ATCU_RHPTCDischrgeRequest";
CM_ SG_ 3221225472 L_ATCU_FltMsgTmOutRHPTC1 "ATCU_FltMsgTmOutRHPTC1";
CM_ SG_ 3221225472 L_ATCU_FltMsgTmOutRHPTC2 "ATCU_FltMsgTmOutRHPTC2";
CM_ SG_ 3221225472 L_ATCU_FltMsgTmOutRHPTC3 "ATCU_FltMsgTmOutRHPTC3";
CM_ SG_ 3221225472 L_ATCU_FltMsgTmOutRHPTC4 "ATCU_FltMsgTmOutRHPTC4";
CM_ SG_ 3221225472 L_ATCU_RrBlwLvl "ATCU_RrBlowerLevel";
CM_ SG_ 3221225472 L_ATCU_RrBlwLvlSigVaildSta "ATCU_RrBlowrLevelSignalVaildStatus";
CM_ SG_ 3221225472 L_ATCU_OutTempSnsrVal2 "ATCU_OutsideTemperatureSensorValue2";
CM_ SG_ 3221225472 L_ATCU_RHPTCRoofTrgtDty "ATCU_RHPTCRoofTargetDuty";
CM_ SG_ 3221225472 L_ATCU_RrBlwFltSta "ATCU_BlowerFaultStatus";
CM_ SG_ 3221225472 RHPTC_FlrFlt "RHPTC_FloorFault";
CM_ SG_ 3221225472 RHPTC_FlrFltLVLow "RHPTC_FloorFaultLVLow";
CM_ SG_ 3221225472 RHPTC_FlrFailLVSnr "RHPTC_FloorFailLowVoltageSensor";
CM_ SG_ 3221225472 RHPTC_FlrFailCuFLRentSnr "RHPTC_FloorFailCuFloorentSensor";
CM_ SG_ 3221225472 RHPTC_FlrrFailCoreTempSnr "RHPTC_FloorFailCoreTempSensor";
CM_ SG_ 3221225472 RHPTC_FlrFailPcbTempSnr "RHPTC_FloorFailPcbTempSensor";
CM_ SG_ 3221225472 RHPTC_FlrFailIGBT "RHPTC_FloorFailIGBT";
CM_ SG_ 3221225472 RHPTC_FlrFailOpenLoad "RHPTC_FloorFailOpenLoad";
CM_ SG_ 3221225472 RHPTC_FlrLtdOpCause "RHPTC_FloorLtdOperationCauseFlag";
CM_ SG_ 3221225472 RHPTC_FlrFltLVHigh "RHPTC_FloorFaultLVHigh";
CM_ SG_ 3221225472 RHPTC_FlrSwrVer "RHPTC_FloorSoftwareVer";
CM_ SG_ 3221225472 RHPTC_FlrFltHVLow "RHPTC_FloorFaultHVLow";
CM_ SG_ 3221225472 RHPTC_FlrFltHVHigh "RHPTC_FloorFaultHVHigh";
CM_ SG_ 3221225472 RHPTC_FlrFltOverCuFLRent "RHPTC_FloorFaultOverCuFloorent";
CM_ SG_ 3221225472 RHPTC_FlrFltThermalShutDn "RHPTC_FloorFltThermalShutDn";
CM_ SG_ 3221225472 RHPTC_FlrFltPcbThermalShutDn "RHPTC_FloorFltPcbThermalShutDn";
CM_ SG_ 3221225472 RHPTC_FlrFltMsgTmOutATCU "RHPTC_FloorFltMsgTmOutATCU";
CM_ SG_ 3221225472 RHPTC_FlrFailHVSnr "RHPTC_FloorFailHighVoltageSensor";
CM_ SG_ 3221225472 RHPTC_FlrRdySta "RHPTC_FloorReadyStatus";
CM_ SG_ 3221225472 RHPTC_FlrOpSta "RHPTC_FloorOperationStatus";
CM_ SG_ 3221225472 RHPTC_FlrCnsmptPwr_W "RHPTC_FloorConsumptionPower_W";
CM_ SG_ 3221225472 RHPTC_FlrCtrlTyp "RHPTC_FloorControlType";
CM_ SG_ 3221225472 RHPTC_FlrVoltage_V "RHPTC_FloorVoltage_V";
CM_ SG_ 3221225472 RHPTC_FlrCuFlrent_A "RHPTC_FloorCuFloorent_A";
CM_ SG_ 3221225472 RHPTC_FlrDutyFB_Pec "RHPTC_FloorDutyFeedBack_Percentile";
CM_ SG_ 3221225472 RHPTC_FlrDutyFB_IGBT "RHPTC_FloorDutyFeedBack_IGBT";
CM_ SG_ 3221225472 RHPTC_FlrCoreTemp_C "RHPTC_FloorCoreTemp_C";
CM_ SG_ 3221225472 RHPTC_RoofFlt "RHPTC_RoofFault";
CM_ SG_ 3221225472 RHPTC_RoofFltLVLow "RHPTC_RoofFaultLVLow";
CM_ SG_ 3221225472 RHPTC_RoofFailLVSnr "RHPTC_RoofFailLowVoltageSensor";
CM_ SG_ 3221225472 RHPTC_RoofFailCuRoofentSnr "RHPTC_RoofFailCuRoofentSensor";
CM_ SG_ 3221225472 RHPTC_RoofFailCoreTempSnr "RHPTC_RoofFailCoreTempSensor";
CM_ SG_ 3221225472 RHPTC_RoofFailPcbTempSnr "RHPTC_RoofFailPcbTempSensor";
CM_ SG_ 3221225472 RHPTC_RoofFailIGBT "RHPTC_RoofFailIGBT";
CM_ SG_ 3221225472 RHPTC_RoofFailOpenLoad "RHPTC_RoofFailOpenLoad";
CM_ SG_ 3221225472 RHPTC_RoofLtdOpCause "RHPTC_RoofLtdOperationCauseFlag";
CM_ SG_ 3221225472 RHPTC_RoofFltLVHigh "RHPTC_RoofFaultLVHigh";
CM_ SG_ 3221225472 RHPTC_RoofSwVer "RHPTC_RoofSoftwareVer";
CM_ SG_ 3221225472 RHPTC_RoofFltHVLow "RHPTC_RoofFaultHVLow";
CM_ SG_ 3221225472 RHPTC_CnsmptPwrTtl_W "RHPTC_ConsumptionPowerTotal_W";
CM_ SG_ 3221225472 RHPTC_RoofFltHVHigh "RHPTC_RoofFaultHVHigh";
CM_ SG_ 3221225472 RHPTC_IntlkSta "RHPTC_InterlockStatus";
CM_ SG_ 3221225472 RHPTC_RoofFltOverCuRoofent "RHPTC_RoofFaultOverCuRoofent";
CM_ SG_ 3221225472 RHPTC_RoofFltThermalShutDn "RHPTC_RoofFltThermalShutDn";
CM_ SG_ 3221225472 RHPTC_RoofFltPcbThermalShutDn "RHPTC_RoofFltPcbThermalShutDn";
CM_ SG_ 3221225472 RHPTC_RoofFltMsgTmOutATCU "RHPTC_RoofFltMsgTmOutATCU";
CM_ SG_ 3221225472 RHPTC_RoofFailHVSnr "RHPTC_RoofFailHighVoltageSensor";
CM_ SG_ 3221225472 RHPTC_RoofRdySta "RHPTC_RoofReadyStatus";
CM_ SG_ 3221225472 RHPTC_RoofOpSta "RHPTC_RoofOperationStatus";
CM_ SG_ 3221225472 RHPTC_RoofCnsmptPwr_W "RHPTC_RoofConsumptionPower_W";
CM_ SG_ 3221225472 RHPTC_RoofVoltage_V "RHPTC_RoofVoltage_V";
CM_ SG_ 3221225472 RHPTC_RoofCtrlTyp "RHPTC_RoofControlType";
CM_ SG_ 3221225472 RHPTC_RoofCuRoofent_A "RHPTC_RoofCuRoofent_A";
CM_ SG_ 3221225472 RHPTC_RoofDutyFB_Pec "RHPTC_RoofDutyFeedBack_Percentile";
CM_ SG_ 3221225472 RHPTC_RoofDutyFB_IGBT "RHPTC_RoofDutyFeedBack_IGBT";
CM_ SG_ 3221225472 RHPTC_RoofCoreTemp_C "RHPTC_RoofCoreTemp_C";
CM_ BO_ 1332 "[P] Periodic";
CM_ SG_ 1332 L_ATCU_FHPTCOpPrmssnSta "ATCU_FHPTCOperationPermissionStatus";
CM_ SG_ 1332 L_ATCU_xEV_BMSRomTyp "ATCU_xEV_BMSRomType";
CM_ SG_ 1332 L_ATCU_FHPTCPassTrgtDty "ATCU_FHPTCPassengerTargetDuty";
CM_ SG_ 1332 L_ATCU_FHPTCDischrgReq "ATCU_FHPTCDischrgeRequest";
CM_ SG_ 1332 L_ATCU_FltMsgTmOutFHPTC1 "ATCU_FltMsgTmOutFHPTC1";
CM_ SG_ 1332 L_ATCU_FltMsgTmOutFHPTC2 "ATCU_FltMsgTmOutFHPTC2";
CM_ SG_ 1332 L_ATCU_FltMsgTmOutFHPTC3 "ATCU_FltMsgTmOutFHPTC3";
CM_ SG_ 1332 L_ATCU_FltMsgTmOutFHPTC4 "ATCU_FltMsgTmOutFHPTC4";
CM_ SG_ 1332 L_ATCU_FrBlwLvl "ATCU_FrBlowerLevel";
CM_ SG_ 1332 L_ATCU_FrBlwLvlSigVaildSta "ATCU_FrBlowrLevelSignalVaildStatus";
CM_ SG_ 1332 L_ATCU_OutTempSnsrVal "ATCU_OutsideTemperatureSensorValue";
CM_ SG_ 1332 L_ATCU_DrvrSdTyp "ATCU_DriverSideType";
CM_ SG_ 1332 L_ATCU_FrBlwFltSta "ATCU_FrontBlowerFaultStatus";
CM_ SG_ 1332 L_ATCU_PassBlwLvl "ATCU_PasssengerBlowerLevel";
CM_ SG_ 1332 L_ATCU_FHPTCDrTrgtDty "ATCU_FHPTCDriverTargetDuty";
CM_ BO_ 273 "[P] Periodic";
CM_ SG_ 273 L_ATCU_FHPTCOpPrmssnSta "ATCU_FHPTCOperationPermissionStatus";
CM_ SG_ 273 L_ATCU_xEV_BMSRomTyp "ATCU_xEV_BMSRomType";
CM_ SG_ 273 L_ATCU_FHPTCPassTrgtDty "ATCU_FHPTCPassengerTargetDuty";
CM_ SG_ 273 L_ATCU_FHPTCDischrgReq "ATCU_FHPTCDischrgeRequest";
CM_ SG_ 273 L_ATCU_FltMsgTmOutFHPTC1 "ATCU_FltMsgTmOutFHPTC1";
CM_ SG_ 273 L_ATCU_FltMsgTmOutFHPTC2 "ATCU_FltMsgTmOutFHPTC2";
CM_ SG_ 273 L_ATCU_FltMsgTmOutFHPTC3 "ATCU_FltMsgTmOutFHPTC3";
CM_ SG_ 273 L_ATCU_FltMsgTmOutFHPTC4 "ATCU_FltMsgTmOutFHPTC4";
CM_ SG_ 273 L_ATCU_FrBlwLvl "ATCU_FrBlowerLevel";
CM_ SG_ 273 L_ATCU_FrBlwLvlSigVaildSta "ATCU_FrBlowrLevelSignalVaildStatus";
CM_ SG_ 273 L_ATCU_OutTempSnsrVal "ATCU_OutsideTemperatureSensorValue";
CM_ SG_ 273 L_ATCU_DrvrSdTyp "ATCU_DriverSideType";
CM_ SG_ 273 L_ATCU_FrBlwFltSta "ATCU_FrontBlowerFaultStatus";
CM_ SG_ 273 L_ATCU_PassBlwLvl "ATCU_PasssengerBlowerLevel";
CM_ SG_ 273 L_ATCU_FHPTCDrTrgtDty "ATCU_FHPTCDriverTargetDuty";
CM_ BO_ 322 "[P] Periodic";
CM_ SG_ 322 FHPTC_PassRdySta "FHPTC_PassReadyStatus";
CM_ SG_ 322 FHPTC_PassOpSta "FHPTC_PassOperationStatus";
CM_ SG_ 322 FHPTC_PassCnsmptPwr_W "FHPTC_PassConsumptionPower_W";
CM_ SG_ 322 FHPTC_PassCtrlTyp "FHPTC_PassControlType";
CM_ SG_ 322 FHPTC_PassVoltage_V "FHPTC_PassVoltage_V";
CM_ SG_ 322 FHPTC_PassCurrent_A "FHPTC_PassCurrent_A";
CM_ SG_ 322 FHPTC_PassDutyFB_Pec "FHPTC_PassDutyFB_Percentile";
CM_ SG_ 322 FHPTC_PassDutyFB_IGBT "FHPTC_PassDutyFeedBack_IGBT";
CM_ SG_ 322 FHPTC_PassCoreTemp_C "FHPTC_PassCoreTemp_C";
CM_ BO_ 323 "[P] Periodic";
CM_ SG_ 323 FHPTC_PassFlt "FHPTC_PassFault";
CM_ SG_ 323 FHPTC_PassFltLVLow "FHPTC_PassFaultLVLow";
CM_ SG_ 323 FHPTC_PassFailLVSnr "FHPTC_PassFailLVSensor";
CM_ SG_ 323 FHPTC_PassFailCurrentSnr "FHPTC_PassFailCurrentSensor";
CM_ SG_ 323 FHPTC_PassFailCoreTempSnr "FHPTC_PassFailCoreTempSensor";
CM_ SG_ 323 FHPTC_PassFailPcbTempSnr "FHPTC_PassFailPcbTempSensor";
CM_ SG_ 323 FHPTC_PassFailIGBT "FHPTC_PassFailIGBT";
CM_ SG_ 323 FHPTC_PassFailOpenLoad "FHPTC_PassFailOpenLoad";
CM_ SG_ 323 FHPTC_PassLtdOpCause "FHPTC_PassLtdOperationCause";
CM_ SG_ 323 FHPTC_PassFltLVHigh "FHPTC_PassFaultLVHigh";
CM_ SG_ 323 FHPTC_PassSwVer "FHPTC_PassSoftwareVer";
CM_ SG_ 323 FHPTC_PassFltHVLow "FHPTC_PassFaultHVLow";
CM_ SG_ 323 FHPTC_PassFltHVHigh "FHPTC_PassFaultHVHigh";
CM_ SG_ 323 FHPTC_PassFltOverCurrent "FHPTC_PassFaultOverCurrent";
CM_ SG_ 323 FHPTC_PassFltThermalShutDn "FHPTC_PassFaultThermalShutDown";
CM_ SG_ 323 FHPTC_PassFltPcbThermalShutDn "FHPTC_PassFaultPcbThermalShutDown";
CM_ SG_ 323 FHPTC_PassFltMsgTmOutATCU "FHPTC_PassFaultMessageTimeOutATCU";
CM_ SG_ 323 FHPTC_PassFailHVSnr "FHPTC_PassFailHVSensor";
CM_ BO_ 320 "[P] Periodic";
CM_ SG_ 320 FHPTC_DrRdySta "FHPTC_DrReadyStatus";
CM_ SG_ 320 FHPTC_DrOpSta "FHPTC_DrOperationStatus";
CM_ SG_ 320 FHPTC_DrCnsmptPwr_W "FHPTC_DrConsumptionPower_W";
CM_ SG_ 320 FHPTC_DrCurrent_A "FHPTC_DrCurrent_A";
CM_ SG_ 320 FHPTC_DrCoreTemp_C "FHPTC_DrCoreTemp_C";
CM_ SG_ 320 FHPTC_DrDutyFB_Pec "FHPTC_DrDutyFeedBack_Percentile";
CM_ SG_ 320 FHPTC_DrDutyFB_IGBT "FHPTC_DrDutyFeedBack_IGBT";
CM_ SG_ 320 FHPTC_DrCtrlTyp "FHPTC_DrControlType";
CM_ SG_ 320 FHPTC_DrVoltage_V "FHPTC_DrVoltage_V";
CM_ BO_ 321 "[P] Periodic";
CM_ SG_ 321 FHPTC_DrFlt "FHPTC_DrFault";
CM_ SG_ 321 FHPTC_DrFltLVLow "FHPTC_DrFaultLVLow";
CM_ SG_ 321 FHPTC_DrFailLVSnr "FHPTC_DrFailLowVoltageSensor";
CM_ SG_ 321 FHPTC_DrFailCurrentSnr "FHPTC_DrFailCurrentSensor";
CM_ SG_ 321 FHPTC_DrFailCoreTempSnr "FHPTC_DrFailCoreTempSensor";
CM_ SG_ 321 FHPTC_DrFailPcbTempSnr "FHPTC_DrFailPcbTempSensor";
CM_ SG_ 321 FHPTC_DrFailIGBT "FHPTC_DrFailIGBT";
CM_ SG_ 321 FHPTC_DrFailOpenLoad "FHPTC_DrFailOpenLoad";
CM_ SG_ 321 FHPTC_DrLtdOpCause "FHPTC_DrLtdOperationCauseFlag";
CM_ SG_ 321 FHPTC_DrFltLVHigh "FHPTC_DrFaultLVHigh";
CM_ SG_ 321 FHPTC_DrSwVer "FHPTC_DrSoftwareVer";
CM_ SG_ 321 FHPTC_DrFltHVLow "FHPTC_DrFaultHVLow";
CM_ SG_ 321 FHPTC_CnsmptPwrTtl_W "FHPTC_ConsumptionPowerTotal_W";
CM_ SG_ 321 FHPTC_DrFltHVHigh "FHPTC_DrFaultHVHigh";
CM_ SG_ 321 FHPTC_IntlkSta "FHPTC_InterlockStatus";
CM_ SG_ 321 FHPTC_DrFltOverCurrent "FHPTC_DrFaultOverCurrent";
CM_ SG_ 321 FHPTC_DrFltThermalShutDn "FHPTC_DrFaultThermalShutDown";
CM_ SG_ 321 FHPTC_DrFltPcbThermalShutDn "FHPTC_DrFaultPcbThermalShutDown";
CM_ SG_ 321 FHPTC_DrFltMsgTmOutATCU "FHPTC_DrFaultMassgeTimemOutATCU";
CM_ SG_ 321 FHPTC_DrFailHVSnr "FHPTC_DrFailHighVoltageSensor";
BA_DEF_ BO_  "UsrMsgIDSforwardDeviation" INT 0 100;
BA_DEF_ BO_  "UsrMsgIDSbackwardDeviation" INT 50 1000;
BA_DEF_ BO_  "GenMsgCycleTime" INT 0 2000;
BA_DEF_ BO_  "GenMsgStartDelayTime" INT 0 2000;
BA_DEF_ BO_  "GenMsgSendType" ENUM  "Cyclic","NoMsgSendType";
BA_DEF_ BO_  "GenMsgCycleTimeFast" INT 0 500;
BA_DEF_ BO_  "GenMsgDelayTime" INT 0 20;
BA_DEF_ BO_  "GenMsgILSupport" ENUM  "No","Yes";
BA_DEF_ BO_  "GenMsgNrOfRepetition" INT 0 3;
BA_DEF_ BO_  "VFrameFormat" ENUM  "StandardCAN","ExtendedCAN","reserved","reserved","reserved","reserved","reserved","reserved","reserved","reserved","reserved","reserved","reserved","reserved","StandardCAN_FD","ExtendedCAN_FD";
BA_DEF_ SG_  "UserSigValidity" ENUM  "B+","ACC","IG","IG1","IG2","IG3","IG1 or IG2","IG1 or IG3","Undef";
BA_DEF_ SG_  "UsrSigPurpose" ENUM  "Undef","FN","DIAG","DIAG(Req)","DIAG(Res)","DIAG(Phy)","DEV","CCP(Req)","CCP(Res)","NM","TP";
BA_DEF_ SG_  "GenSigStartValue" INT 0 1215752192;
BA_DEF_ SG_  "NetworkRequestHoldingTime" INT 0 65535;
BA_DEF_ SG_  "Description" STRING ;
BA_DEF_ SG_  "Version" STRING ;
BA_DEF_ SG_  "GenSigEnvVarType" ENUM  "Int","Float","Undef";
BA_DEF_ SG_  "GenSigSendType" ENUM  "Cyclic","OnWrite","OnWriteWithRepetition","OnChange","OnChangeWithRepetition","IfActive","IfActiveWithRepetition","NoSigSendType","OnChangeAndIfActive","OnChangeAndIfActiveWithRepetition";
BA_DEF_ SG_  "GwSigLatencyTime" INT 0 65536;
BA_DEF_ SG_  "GwSigMissingSourceType" ENUM  "Undef","OldValue","DefaultValue","InitialValue";
BA_DEF_ SG_  "NWM-WakeupAllowed" ENUM  "<n.a.>";
BA_DEF_ SG_  "RoutingFactor" INT 1 1215752192;
BA_DEF_REL_ BU_SG_REL_  "GenSigTimeoutTime" INT 0 7000;
BA_DEF_DEF_  "UsrMsgIDSforwardDeviation" 10;
BA_DEF_DEF_  "UsrMsgIDSbackwardDeviation" 100;
BA_DEF_DEF_  "GenMsgCycleTime" 200;
BA_DEF_DEF_  "GenMsgStartDelayTime" 0;
BA_DEF_DEF_  "GenMsgSendType" "NoMsgSendType";
BA_DEF_DEF_  "GenMsgCycleTimeFast" 40;
BA_DEF_DEF_  "GenMsgDelayTime" 20;
BA_DEF_DEF_  "GenMsgILSupport" "Yes";
BA_DEF_DEF_  "GenMsgNrOfRepetition" 3;
BA_DEF_DEF_  "VFrameFormat" "StandardCAN";
BA_DEF_DEF_  "UserSigValidity" "IG";
BA_DEF_DEF_  "UsrSigPurpose" "FN";
BA_DEF_DEF_  "GenSigStartValue" 0;
BA_DEF_DEF_  "NetworkRequestHoldingTime" 0;
BA_DEF_DEF_  "Description" "";
BA_DEF_DEF_  "Version" "";
BA_DEF_DEF_  "GenSigEnvVarType" "Undef";
BA_DEF_DEF_  "GenSigSendType" "NoSigSendType";
BA_DEF_DEF_  "GwSigLatencyTime" 40;
BA_DEF_DEF_  "GwSigMissingSourceType" "Undef";
BA_DEF_DEF_  "NWM-WakeupAllowed" "<n.a.>";
BA_DEF_DEF_  "RoutingFactor" 1;
BA_DEF_DEF_REL_ "GenSigTimeoutTime" 500;
BA_ "GenMsgCycleTime" BO_ 1332 20;
BA_ "GenMsgSendType" BO_ 1332 0;
BA_ "GenMsgCycleTimeFast" BO_ 1332 0;
BA_ "GenMsgDelayTime" BO_ 1332 0;
BA_ "GenMsgNrOfRepetition" BO_ 1332 0;
BA_ "GenMsgSendType" BO_ 273 0;
BA_ "GenMsgCycleTime" BO_ 273 20;
BA_ "GenMsgCycleTimeFast" BO_ 273 0;
BA_ "GenMsgNrOfRepetition" BO_ 273 0;
BA_ "GenMsgDelayTime" BO_ 273 0;
BA_ "GenMsgSendType" BO_ 322 0;
BA_ "GenMsgCycleTime" BO_ 322 20;
BA_ "GenMsgCycleTimeFast" BO_ 322 0;
BA_ "GenMsgNrOfRepetition" BO_ 322 0;
BA_ "GenMsgDelayTime" BO_ 322 0;
BA_ "GenMsgSendType" BO_ 323 0;
BA_ "GenMsgCycleTime" BO_ 323 20;
BA_ "GenMsgCycleTimeFast" BO_ 323 0;
BA_ "GenMsgNrOfRepetition" BO_ 323 0;
BA_ "GenMsgDelayTime" BO_ 323 0;
BA_ "GenMsgSendType" BO_ 320 0;
BA_ "GenMsgCycleTime" BO_ 320 20;
BA_ "GenMsgCycleTimeFast" BO_ 320 0;
BA_ "GenMsgNrOfRepetition" BO_ 320 0;
BA_ "GenMsgDelayTime" BO_ 320 0;
BA_ "GenMsgSendType" BO_ 321 0;
BA_ "GenMsgCycleTime" BO_ 321 20;
BA_ "GenMsgCycleTimeFast" BO_ 321 0;
BA_ "GenMsgNrOfRepetition" BO_ 321 0;
BA_ "GenMsgDelayTime" BO_ 321 0;
BA_ "GenSigSendType" SG_ 3221225472 L_2HKBD_RrDrModeBiLvlSw 4;
BA_ "UserSigValidity" SG_ 3221225472 L_2HKBD_RrDrModeBiLvlSw 7;
BA_ "Version" SG_ 3221225472 L_2HKBD_RrDrModeBiLvlSw "23.09.01";
BA_ "GenSigSendType" SG_ 3221225472 L_2HKBD_RrDrTempDnSw 4;
BA_ "UserSigValidity" SG_ 3221225472 L_2HKBD_RrDrTempDnSw 7;
BA_ "Version" SG_ 3221225472 L_2HKBD_RrDrTempDnSw "23.09.01";
BA_ "GenSigSendType" SG_ 3221225472 L_2HKBD_RrDrTempUpSw 4;
BA_ "UserSigValidity" SG_ 3221225472 L_2HKBD_RrDrTempUpSw 7;
BA_ "Version" SG_ 3221225472 L_2HKBD_RrDrTempUpSw "23.09.01";
BA_ "GenSigSendType" SG_ 3221225472 L_2HKBD_RrDrBlwDnSw 4;
BA_ "UserSigValidity" SG_ 3221225472 L_2HKBD_RrDrBlwDnSw 7;
BA_ "Version" SG_ 3221225472 L_2HKBD_RrDrBlwDnSw "23.09.01";
BA_ "GenSigSendType" SG_ 3221225472 L_2HKBD_RrDrBlwUpSw 4;
BA_ "UserSigValidity" SG_ 3221225472 L_2HKBD_RrDrBlwUpSw 7;
BA_ "Version" SG_ 3221225472 L_2HKBD_RrDrBlwUpSw "23.09.01";
BA_ "UserSigValidity" SG_ 3221225472 L_2HKBD_RrFlrDuctSnsr 7;
BA_ "Version" SG_ 3221225472 L_2HKBD_RrFlrDuctSnsr "23.09.05";
BA_ "UserSigValidity" SG_ 3221225472 L_2HKBD_RrVntDuctSnsr 7;
BA_ "Version" SG_ 3221225472 L_2HKBD_RrVntDuctSnsr "23.09.05";
BA_ "Description" SG_ 3221225472 L_ATCU_Typ1 "This signal includes regional information.";
BA_ "GenSigSendType" SG_ 3221225472 L_ATCU_Typ1 4;
BA_ "UserSigValidity" SG_ 3221225472 L_ATCU_Typ1 7;
BA_ "Version" SG_ 3221225472 L_ATCU_Typ1 "23.08.13";
BA_ "Description" SG_ 3221225472 L_ATCU_Opt1 "Bit 0~2 (SeatHeatCoolOpt):0-Init/1- Heater only 2step/2 - Heater only 3step/3 - Vent only 2step /4 - Vent only 3step/ 5-Heater and Vent 2step/6-Heater and Vent 3step/7-Invalid

Bit 3~4 (StWhlHeatOpt):0-Not Applied/1-Applied/2~3 - Invaild

Bit 5~6 (FrWndS";
BA_ "GenSigSendType" SG_ 3221225472 L_ATCU_Opt1 4;
BA_ "UserSigValidity" SG_ 3221225472 L_ATCU_Opt1 7;
BA_ "Version" SG_ 3221225472 L_ATCU_Opt1 "23.08.13";
BA_ "Description" SG_ 3221225472 L_ATCU_Drv_SeatOptSta "Heater/ventilation option specification applied to Driver seat (LH side for LHD / RH side for RHD)";
BA_ "GenSigSendType" SG_ 3221225472 L_ATCU_Drv_SeatOptSta 4;
BA_ "UserSigValidity" SG_ 3221225472 L_ATCU_Drv_SeatOptSta 7;
BA_ "Version" SG_ 3221225472 L_ATCU_Drv_SeatOptSta "23.08.13";
BA_ "Description" SG_ 3221225472 L_ATCU_Ast_SeatOptSta "Heater/ventilation option specification applied to Driver seat (LH side for LHD / RH side for RHD)";
BA_ "GenSigSendType" SG_ 3221225472 L_ATCU_Ast_SeatOptSta 4;
BA_ "UserSigValidity" SG_ 3221225472 L_ATCU_Ast_SeatOptSta 7;
BA_ "Version" SG_ 3221225472 L_ATCU_Ast_SeatOptSta "23.08.13";
BA_ "Description" SG_ 3221225472 L_ATCU_RL_SeatOptSta "Heater/ventilation option specification applied to Driver seat (LH side for LHD / RH side for RHD)";
BA_ "GenSigSendType" SG_ 3221225472 L_ATCU_RL_SeatOptSta 4;
BA_ "UserSigValidity" SG_ 3221225472 L_ATCU_RL_SeatOptSta 7;
BA_ "Version" SG_ 3221225472 L_ATCU_RL_SeatOptSta "23.08.13";
BA_ "Description" SG_ 3221225472 L_ATCU_RR_SeatOptSta "Heater/ventilation option specification applied to Driver seat (LH side for LHD / RH side for RHD)";
BA_ "GenSigSendType" SG_ 3221225472 L_ATCU_RR_SeatOptSta 4;
BA_ "UserSigValidity" SG_ 3221225472 L_ATCU_RR_SeatOptSta 7;
BA_ "Version" SG_ 3221225472 L_ATCU_RR_SeatOptSta "23.08.13";
BA_ "Description" SG_ 3221225472 L_ATCU_Typ2 "This signal indicates option of HTR Control.



Bit0 (Blower Type):0 - Single/1 - Dual

Bit1 (Temp Type):0 - Single/1 - Dual

Bit2 (AUTO Type):0 - Single/1 - Dual

Bit3 (Mode Type):0 - Single/1 - Dual";
BA_ "GenSigSendType" SG_ 3221225472 L_ATCU_Typ2 4;
BA_ "UserSigValidity" SG_ 3221225472 L_ATCU_Typ2 7;
BA_ "Version" SG_ 3221225472 L_ATCU_Typ2 "23.08.13";
BA_ "Description" SG_ 3221225472 L_ATCU_Typ3 "This signal indicates Temp range option of HTR Control.



Bit0~1 (Temp Display Range):0 - OLD Temp Set Range/1- New Temp Set Range/2 - None Heater Temp Set Range/3 - Invaild

Bit2 (Driver Type): 0- LHD / 1 - RHD

Bit3~7 : Reserved";
BA_ "GenSigSendType" SG_ 3221225472 L_ATCU_Typ3 4;
BA_ "UserSigValidity" SG_ 3221225472 L_ATCU_Typ3 7;
BA_ "Version" SG_ 3221225472 L_ATCU_Typ3 "23.08.13";
BA_ "UserSigValidity" SG_ 3221225472 L_2HKBD_Rr_EvapVolVal 7;
BA_ "Version" SG_ 3221225472 L_2HKBD_Rr_EvapVolVal "23.09.05";
BA_ "UserSigValidity" SG_ 3221225472 L_2HKBD_Rr_TempActrSt 7;
BA_ "Version" SG_ 3221225472 L_2HKBD_Rr_TempActrSt "23.09.01";
BA_ "UserSigValidity" SG_ 3221225472 L_2HKBD_Rr_TempAsstActrFB 7;
BA_ "Version" SG_ 3221225472 L_2HKBD_Rr_TempAsstActrFB "23.09.01";
BA_ "UserSigValidity" SG_ 3221225472 L_2HKBD_Rr_TempAsstActrSt 7;
BA_ "Version" SG_ 3221225472 L_2HKBD_Rr_TempAsstActrSt "23.09.01";
BA_ "UserSigValidity" SG_ 3221225472 L_2HKBD_Rr_ModeActrFB 7;
BA_ "Version" SG_ 3221225472 L_2HKBD_Rr_ModeActrFB "23.09.01";
BA_ "UserSigValidity" SG_ 3221225472 L_2HKBD_Rr_ModeActrSt 7;
BA_ "Version" SG_ 3221225472 L_2HKBD_Rr_ModeActrSt "23.09.01";
BA_ "UserSigValidity" SG_ 3221225472 L_2HKBD_Rr_BLDCError 7;
BA_ "Version" SG_ 3221225472 L_2HKBD_Rr_BLDCError "23.09.01";
BA_ "Description" SG_ 3221225472 L_2HKBD_Rr_HVACBLDCRpmFB "00H~3E8H:RPM = Factor * Hex + Offset/3E9H ~ FFFFH:RESERVED";
BA_ "UserSigValidity" SG_ 3221225472 L_2HKBD_Rr_HVACBLDCRpmFB 7;
BA_ "Version" SG_ 3221225472 L_2HKBD_Rr_HVACBLDCRpmFB "23.09.05";
BA_ "UserSigValidity" SG_ 3221225472 L_2HKBD_Rr_TempActrFB 7;
BA_ "Version" SG_ 3221225472 L_2HKBD_Rr_TempActrFB "23.09.01";
BA_ "Description" SG_ 3221225472 L_ATCU_3rdRrTempCDis "This signal indicates Outside temperature (¡É).

(Use for display only)";
BA_ "GenSigSendType" SG_ 3221225472 L_ATCU_3rdRrTempCDis 4;
BA_ "UserSigValidity" SG_ 3221225472 L_ATCU_3rdRrTempCDis 7;
BA_ "Version" SG_ 3221225472 L_ATCU_3rdRrTempCDis "23.08.13";
BA_ "GenSigSendType" SG_ 3221225472 L_ATCU_3rdRrModDis 4;
BA_ "UserSigValidity" SG_ 3221225472 L_ATCU_3rdRrModDis 7;
BA_ "Version" SG_ 3221225472 L_ATCU_3rdRrModDis "23.08.13";
BA_ "GenSigSendType" SG_ 3221225472 L_ATCU_3rdRrBlwDis 4;
BA_ "UserSigValidity" SG_ 3221225472 L_ATCU_3rdRrBlwDis 7;
BA_ "Version" SG_ 3221225472 L_ATCU_3rdRrBlwDis "23.08.13";
BA_ "GenSigSendType" SG_ 3221225472 L_ATCU_3rdRrAutoDis 4;
BA_ "UserSigValidity" SG_ 3221225472 L_ATCU_3rdRrAutoDis 7;
BA_ "Version" SG_ 3221225472 L_ATCU_3rdRrAutoDis "23.08.13";
BA_ "GenSigSendType" SG_ 3221225472 L_ATCU_3rdRrMultiAutoBlwDis 4;
BA_ "UserSigValidity" SG_ 3221225472 L_ATCU_3rdRrMultiAutoBlwDis 7;
BA_ "Version" SG_ 3221225472 L_ATCU_3rdRrMultiAutoBlwDis "23.08.13";
BA_ "GenSigSendType" SG_ 3221225472 L_ATCU_3rdRrSyncDis 4;
BA_ "UserSigValidity" SG_ 3221225472 L_ATCU_3rdRrSyncDis 7;
BA_ "Version" SG_ 3221225472 L_ATCU_3rdRrSyncDis "23.08.13";
BA_ "GenSigSendType" SG_ 3221225472 L_ATCU_3rdRrOnInd 4;
BA_ "UserSigValidity" SG_ 3221225472 L_ATCU_3rdRrOnInd 7;
BA_ "Version" SG_ 3221225472 L_ATCU_3rdRrOnInd "23.08.13";
BA_ "GenSigSendType" SG_ 3221225472 L_ATCU_3rdRrLockDis 4;
BA_ "UserSigValidity" SG_ 3221225472 L_ATCU_3rdRrLockDis 7;
BA_ "Version" SG_ 3221225472 L_ATCU_3rdRrLockDis "23.08.13";
BA_ "GenSigSendType" SG_ 3221225472 L_ATCU_3rdRrLcdBckLightSta 4;
BA_ "UserSigValidity" SG_ 3221225472 L_ATCU_3rdRrLcdBckLightSta 7;
BA_ "Version" SG_ 3221225472 L_ATCU_3rdRrLcdBckLightSta "23.08.13";
BA_ "GenSigSendType" SG_ 3221225472 L_ATCU_3rdRrGUIBlankDis 4;
BA_ "UserSigValidity" SG_ 3221225472 L_ATCU_3rdRrGUIBlankDis 7;
BA_ "Version" SG_ 3221225472 L_ATCU_3rdRrGUIBlankDis "23.08.13";
BA_ "GenSigSendType" SG_ 3221225472 L_ATCU_3rdRLStHeatSwHInd 4;
BA_ "UserSigValidity" SG_ 3221225472 L_ATCU_3rdRLStHeatSwHInd 7;
BA_ "Version" SG_ 3221225472 L_ATCU_3rdRLStHeatSwHInd "23.08.13";
BA_ "GenSigSendType" SG_ 3221225472 L_ATCU_3rdRLStHeatSwMInd 4;
BA_ "UserSigValidity" SG_ 3221225472 L_ATCU_3rdRLStHeatSwMInd 7;
BA_ "Version" SG_ 3221225472 L_ATCU_3rdRLStHeatSwMInd "23.08.13";
BA_ "GenSigSendType" SG_ 3221225472 L_ATCU_3rdRLStHeatSwLInd 4;
BA_ "UserSigValidity" SG_ 3221225472 L_ATCU_3rdRLStHeatSwLInd 7;
BA_ "Version" SG_ 3221225472 L_ATCU_3rdRLStHeatSwLInd "23.08.13";
BA_ "GenSigSendType" SG_ 3221225472 L_ATCU_3rdRLStVntSwHInd 4;
BA_ "UserSigValidity" SG_ 3221225472 L_ATCU_3rdRLStVntSwHInd 7;
BA_ "Version" SG_ 3221225472 L_ATCU_3rdRLStVntSwHInd "23.08.13";
BA_ "GenSigSendType" SG_ 3221225472 L_ATCU_3rdRLStVntSwMInd 4;
BA_ "UserSigValidity" SG_ 3221225472 L_ATCU_3rdRLStVntSwMInd 7;
BA_ "Version" SG_ 3221225472 L_ATCU_3rdRLStVntSwMInd "23.08.13";
BA_ "GenSigSendType" SG_ 3221225472 L_ATCU_3rdRLStVntSwLInd 4;
BA_ "UserSigValidity" SG_ 3221225472 L_ATCU_3rdRLStVntSwLInd 7;
BA_ "Version" SG_ 3221225472 L_ATCU_3rdRLStVntSwLInd "23.08.13";
BA_ "GenSigSendType" SG_ 3221225472 L_ATCU_3rdRRStHeatSwHInd 4;
BA_ "UserSigValidity" SG_ 3221225472 L_ATCU_3rdRRStHeatSwHInd 7;
BA_ "Version" SG_ 3221225472 L_ATCU_3rdRRStHeatSwHInd "23.08.13";
BA_ "GenSigSendType" SG_ 3221225472 L_ATCU_3rdRRStHeatSwMInd 4;
BA_ "UserSigValidity" SG_ 3221225472 L_ATCU_3rdRRStHeatSwMInd 7;
BA_ "Version" SG_ 3221225472 L_ATCU_3rdRRStHeatSwMInd "23.08.13";
BA_ "GenSigSendType" SG_ 3221225472 L_ATCU_3rdRRStHeatSwLInd 4;
BA_ "UserSigValidity" SG_ 3221225472 L_ATCU_3rdRRStHeatSwLInd 7;
BA_ "Version" SG_ 3221225472 L_ATCU_3rdRRStHeatSwLInd "23.08.13";
BA_ "GenSigSendType" SG_ 3221225472 L_ATCU_3rdRRStVntSwHInd 4;
BA_ "UserSigValidity" SG_ 3221225472 L_ATCU_3rdRRStVntSwHInd 7;
BA_ "Version" SG_ 3221225472 L_ATCU_3rdRRStVntSwHInd "23.08.13";
BA_ "GenSigSendType" SG_ 3221225472 L_ATCU_3rdRRStVntSwMInd 4;
BA_ "UserSigValidity" SG_ 3221225472 L_ATCU_3rdRRStVntSwMInd 7;
BA_ "Version" SG_ 3221225472 L_ATCU_3rdRRStVntSwMInd "23.08.13";
BA_ "GenSigSendType" SG_ 3221225472 L_ATCU_3rdRRStVntSwLInd 4;
BA_ "UserSigValidity" SG_ 3221225472 L_ATCU_3rdRRStVntSwLInd 7;
BA_ "Version" SG_ 3221225472 L_ATCU_3rdRRStVntSwLInd "23.08.13";
BA_ "GenSigSendType" SG_ 3221225472 L_ATCU_3rdRrMTCOpSta 4;
BA_ "UserSigValidity" SG_ 3221225472 L_ATCU_3rdRrMTCOpSta 7;
BA_ "Version" SG_ 3221225472 L_ATCU_3rdRrMTCOpSta "23.08.13";
BA_ "GenSigSendType" SG_ 3221225472 L_ATCU_3rdRrMtcTempLvl 4;
BA_ "UserSigValidity" SG_ 3221225472 L_ATCU_3rdRrMtcTempLvl 7;
BA_ "Version" SG_ 3221225472 L_ATCU_3rdRrMtcTempLvl "23.08.13";
BA_ "GenSigSendType" SG_ 3221225472 L_ATCU_3rdAUTOStep 4;
BA_ "UserSigValidity" SG_ 3221225472 L_ATCU_3rdAUTOStep 7;
BA_ "Version" SG_ 3221225472 L_ATCU_3rdAUTOStep "23.08.13";
BA_ "GenSigSendType" SG_ 3221225472 L_ATCU_RrPassMultiAutoBlwDis 4;
BA_ "UserSigValidity" SG_ 3221225472 L_ATCU_RrPassMultiAutoBlwDis 7;
BA_ "Version" SG_ 3221225472 L_ATCU_RrPassMultiAutoBlwDis "23.08.13";
BA_ "Description" SG_ 3221225472 L_ATCU_3rdRrTempFDis "This signal indicates Outside Temperature (¢µ)

(Use for display only)";
BA_ "GenSigSendType" SG_ 3221225472 L_ATCU_3rdRrTempFDis 4;
BA_ "UserSigValidity" SG_ 3221225472 L_ATCU_3rdRrTempFDis 7;
BA_ "Version" SG_ 3221225472 L_ATCU_3rdRrTempFDis "23.08.13";
BA_ "Description" SG_ 3221225472 L_2HKBD_SwBtnTyp "Each bit for button type is defined as

0-None/1-Hardkey/2-Touch(Used Beep)/3-Touch(Not Used Beep)

Bit 0~1 : 2nd Temp Button / Bit 2~3 : 2nd Blower Button / Bit 4~5 : 2nd Mode Button / Bit 6~7 : 2nd Auto Button / Bit 8~9 : 2nd A/C Button / Bit 10~11 : 2";
BA_ "GenSigSendType" SG_ 3221225472 L_2HKBD_SwBtnTyp 4;
BA_ "UserSigValidity" SG_ 3221225472 L_2HKBD_SwBtnTyp 7;
BA_ "Version" SG_ 3221225472 L_2HKBD_SwBtnTyp "23.09.01";
BA_ "UserSigValidity" SG_ 3221225472 L_ATCU_RrHVACTempActrTgt 7;
BA_ "Version" SG_ 3221225472 L_ATCU_RrHVACTempActrTgt "23.08.13";
BA_ "UserSigValidity" SG_ 3221225472 L_ATCU_RrHVACTempAsstActrTgt 7;
BA_ "Version" SG_ 3221225472 L_ATCU_RrHVACTempAsstActrTgt "23.08.13";
BA_ "UserSigValidity" SG_ 3221225472 L_ATCU_RrHVACModeActrTgt 7;
BA_ "Version" SG_ 3221225472 L_ATCU_RrHVACModeActrTgt "23.08.13";
BA_ "UserSigValidity" SG_ 3221225472 L_ATCU_RrHVACBlowerTgtV 7;
BA_ "Version" SG_ 3221225472 L_ATCU_RrHVACBlowerTgtV "23.08.13";
BA_ "Description" SG_ 3221225472 L_ATCU_RrHVACBLDCRpmVal "00H~3E8H:RPM = Factor * Hex + Offset/3E9H ~ FFFFH:RESERVED";
BA_ "UserSigValidity" SG_ 3221225472 L_ATCU_RrHVACBLDCRpmVal 7;
BA_ "Version" SG_ 3221225472 L_ATCU_RrHVACBLDCRpmVal "23.08.13";
BA_ "UserSigValidity" SG_ 3221225472 L_ATCU_RrHVACDiagBlwOn 7;
BA_ "Version" SG_ 3221225472 L_ATCU_RrHVACDiagBlwOn "23.08.13";
BA_ "UserSigValidity" SG_ 3221225472 L_ATCU_RrHVACTempActrOpSta 7;
BA_ "Version" SG_ 3221225472 L_ATCU_RrHVACTempActrOpSta "23.08.13";
BA_ "UserSigValidity" SG_ 3221225472 L_ATCU_RrHVACTempAsstActrOpSta 7;
BA_ "Version" SG_ 3221225472 L_ATCU_RrHVACTempAsstActrOpSta "23.08.13";
BA_ "UserSigValidity" SG_ 3221225472 L_ATCU_RrHVACModActrOpSta 7;
BA_ "Version" SG_ 3221225472 L_ATCU_RrHVACModActrOpSta "23.08.13";
BA_ "GenSigSendType" SG_ 3221225472 L_ATCU_ArClnIntroEvt 4;
BA_ "UserSigValidity" SG_ 3221225472 L_ATCU_ArClnIntroEvt 7;
BA_ "Version" SG_ 3221225472 L_ATCU_ArClnIntroEvt "23.08.13";
BA_ "Description" SG_ 3221225472 L_ATCU_ArClnSmblClr "This signal indicates the information about Color of AirCleaning Symbol displaying in the AVN";
BA_ "GenSigSendType" SG_ 3221225472 L_ATCU_ArClnSmblClr 4;
BA_ "UserSigValidity" SG_ 3221225472 L_ATCU_ArClnSmblClr 7;
BA_ "Version" SG_ 3221225472 L_ATCU_ArClnSmblClr "23.08.13";
BA_ "GenSigSendType" SG_ 3221225472 L_ATCU_DustLevelDis 4;
BA_ "UserSigValidity" SG_ 3221225472 L_ATCU_DustLevelDis 7;
BA_ "Version" SG_ 3221225472 L_ATCU_DustLevelDis "23.08.13";
BA_ "GenSigSendType" SG_ 3221225472 L_ATCU_DustBarDisOff 4;
BA_ "UserSigValidity" SG_ 3221225472 L_ATCU_DustBarDisOff 7;
BA_ "Version" SG_ 3221225472 L_ATCU_DustBarDisOff "23.08.13";
BA_ "GenSigSendType" SG_ 3221225472 L_ATCU_DustSnrStepDis 4;
BA_ "UserSigValidity" SG_ 3221225472 L_ATCU_DustSnrStepDis 7;
BA_ "Version" SG_ 3221225472 L_ATCU_DustSnrStepDis "23.08.13";
BA_ "GenSigSendType" SG_ 3221225472 L_ATCU_FragStrhDis 4;
BA_ "UserSigValidity" SG_ 3221225472 L_ATCU_FragStrhDis 7;
BA_ "Version" SG_ 3221225472 L_ATCU_FragStrhDis "23.08.13";
BA_ "Description" SG_ 3221225472 L_ATCU_FragKindDis "This singal indicates display value of Fragnance kind";
BA_ "GenSigSendType" SG_ 3221225472 L_ATCU_FragKindDis 4;
BA_ "UserSigValidity" SG_ 3221225472 L_ATCU_FragKindDis 7;
BA_ "Version" SG_ 3221225472 L_ATCU_FragKindDis "23.08.13";
BA_ "Description" SG_ 3221225472 L_ATCU_Frag1Inform "This signal indicates Information of Fragrance 1";
BA_ "GenSigSendType" SG_ 3221225472 L_ATCU_Frag1Inform 4;
BA_ "UserSigValidity" SG_ 3221225472 L_ATCU_Frag1Inform 7;
BA_ "Version" SG_ 3221225472 L_ATCU_Frag1Inform "23.08.13";
BA_ "Description" SG_ 3221225472 L_ATCU_Frag2Inform "This signal indicates Information of Fragrance 2";
BA_ "GenSigSendType" SG_ 3221225472 L_ATCU_Frag2Inform 4;
BA_ "UserSigValidity" SG_ 3221225472 L_ATCU_Frag2Inform 7;
BA_ "Version" SG_ 3221225472 L_ATCU_Frag2Inform "23.08.13";
BA_ "Description" SG_ 3221225472 L_ATCU_Frag1RemainDisp "This signal indicates Remain Display of Ragrnace No.1";
BA_ "GenSigSendType" SG_ 3221225472 L_ATCU_Frag1RemainDisp 4;
BA_ "UserSigValidity" SG_ 3221225472 L_ATCU_Frag1RemainDisp 7;
BA_ "Version" SG_ 3221225472 L_ATCU_Frag1RemainDisp "23.08.13";
BA_ "Description" SG_ 3221225472 L_ATCU_Frag2RemainDisp "This signal indicates Remain Display of Ragrnace No.2";
BA_ "GenSigSendType" SG_ 3221225472 L_ATCU_Frag2RemainDisp 4;
BA_ "UserSigValidity" SG_ 3221225472 L_ATCU_Frag2RemainDisp 7;
BA_ "Version" SG_ 3221225472 L_ATCU_Frag2RemainDisp "23.08.13";
BA_ "Description" SG_ 3221225472 L_ATCU_ArClnSmblTyp "This signal indicate the feature of Air Cleaning Symbol displaying in the AVN";
BA_ "GenSigSendType" SG_ 3221225472 L_ATCU_ArClnSmblTyp 4;
BA_ "UserSigValidity" SG_ 3221225472 L_ATCU_ArClnSmblTyp 7;
BA_ "Version" SG_ 3221225472 L_ATCU_ArClnSmblTyp "23.08.13";
BA_ "Description" SG_ 3221225472 L_ATCU_FrtBlwMaxLvlVaild "This signal indicates the maximum step of Front Blower according to multi auto steps.";
BA_ "GenSigSendType" SG_ 3221225472 L_ATCU_FrtBlwMaxLvlVaild 4;
BA_ "UserSigValidity" SG_ 3221225472 L_ATCU_FrtBlwMaxLvlVaild 7;
BA_ "Version" SG_ 3221225472 L_ATCU_FrtBlwMaxLvlVaild "23.08.13";
BA_ "GenSigSendType" SG_ 3221225472 L_ATCU_OpSta 4;
BA_ "UserSigValidity" SG_ 3221225472 L_ATCU_OpSta 7;
BA_ "Version" SG_ 3221225472 L_ATCU_OpSta "23.08.13";
BA_ "GenSigSendType" SG_ 3221225472 L_ATCU_TempDispUnit 4;
BA_ "UserSigValidity" SG_ 3221225472 L_ATCU_TempDispUnit 7;
BA_ "Version" SG_ 3221225472 L_ATCU_TempDispUnit "23.08.13";
BA_ "GenSigSendType" SG_ 3221225472 L_ATCU_DrvAUTOStep 4;
BA_ "UserSigValidity" SG_ 3221225472 L_ATCU_DrvAUTOStep 7;
BA_ "Version" SG_ 3221225472 L_ATCU_DrvAUTOStep "23.08.13";
BA_ "Description" SG_ 3221225472 L_ATCU_DiagCodeDis "0x1~0x3FE:PHY=(HEX*1.0-1.0)";
BA_ "GenSigSendType" SG_ 3221225472 L_ATCU_DiagCodeDis 4;
BA_ "UserSigValidity" SG_ 3221225472 L_ATCU_DiagCodeDis 7;
BA_ "Version" SG_ 3221225472 L_ATCU_DiagCodeDis "23.08.13";
BA_ "Description" SG_ 3221225472 L_2HKBD_Sw_Opt1 "Bit0 (CoolSeat):0 - Non CoolSeat/1 ? CoolSeat

Bit1:(HeatSeat):0 - Non HeatSeat/1 ? HeatSeat

Bit2:(Seat):0 - 5 Seat/1 - 7 Seat

Bit3~4:(Type):0 - None/1 - ATC/2 - MTC 

Bit5:RESERVED

Bit6:RESERVED

Bit7:RESERVED";
BA_ "GenSigSendType" SG_ 3221225472 L_2HKBD_Sw_Opt1 4;
BA_ "UserSigValidity" SG_ 3221225472 L_2HKBD_Sw_Opt1 7;
BA_ "Version" SG_ 3221225472 L_2HKBD_Sw_Opt1 "23.09.01";
BA_ "Description" SG_ 3221225472 L_2HKBD_Typ2 "Bit 0~1 (2nd Rear Auto Step):0 ? None/1 ? Single(On/Off)/2 ? 2 Step Type (High/Low/Off)/3 ? 3 Step Type(High/Medium/Low/Off)

Bit 2~3 (2nd Rear Mode Control):0 ? None/1 ? Single/2 - Dual/3 ? (RESERVED) 

Bit 4 (2nd Rear SYNC):0 ? None/1 ? SYNC

Bit 5~6 (";
BA_ "GenSigSendType" SG_ 3221225472 L_2HKBD_Typ2 4;
BA_ "UserSigValidity" SG_ 3221225472 L_2HKBD_Typ2 7;
BA_ "Version" SG_ 3221225472 L_2HKBD_Typ2 "23.09.01";
BA_ "Description" SG_ 3221225472 L_2HKBD_Typ3 "Bit 0~1 (2nd Rear Ps Auto Step):0 ? None/1 ? Single(On/Off)/2 ? 2 Step Type (High/Low/Off)/3 ? 3 Step Type(High/Medium/Low/Off)

Bit 2~3 (2nd Rear Ps Mode Control):0 ? None/1 ? Single/2 - Dual/3 ? (RESERVED) 

Bit 4~5 (2nd Rear Ps Multi Auto Text):0 - Mu";
BA_ "GenSigSendType" SG_ 3221225472 L_2HKBD_Typ3 4;
BA_ "UserSigValidity" SG_ 3221225472 L_2HKBD_Typ3 7;
BA_ "Version" SG_ 3221225472 L_2HKBD_Typ3 "23.09.01";
BA_ "Description" SG_ 3221225472 L_2HKBD_Typ1 "Bit 0~1(2nd Rear Control Type):0 ? None/1 ? MTC/2 ? ATC (Single)

Bit 2~3 (2nd Rear Blower Control):0 ? None/1 ? Single/2 - Dual/3 ? (RESERVED)

Bit 4~5 (2nd Rear Temp Control):0 ? None/1 ? Single/2 - Dual/3 ? (RESERVED) 

Bit 6~7 (2nd Rear Auto Control)";
BA_ "GenSigSendType" SG_ 3221225472 L_2HKBD_Typ1 4;
BA_ "UserSigValidity" SG_ 3221225472 L_2HKBD_Typ1 7;
BA_ "Version" SG_ 3221225472 L_2HKBD_Typ1 "23.09.01";
BA_ "GenSigSendType" SG_ 3221225472 L_ATCU_RrOpSta 4;
BA_ "UserSigValidity" SG_ 3221225472 L_ATCU_RrOpSta 7;
BA_ "Version" SG_ 3221225472 L_ATCU_RrOpSta "23.08.13";
BA_ "Description" SG_ 3221225472 L_ATCU_RrDrvTempFDis "This signal indicates Outside Temperature (¢µ)

(Use for display only)";
BA_ "GenSigSendType" SG_ 3221225472 L_ATCU_RrDrvTempFDis 4;
BA_ "UserSigValidity" SG_ 3221225472 L_ATCU_RrDrvTempFDis 7;
BA_ "Version" SG_ 3221225472 L_ATCU_RrDrvTempFDis "23.08.13";
BA_ "GenSigSendType" SG_ 3221225472 L_ATCU_RrDrvModDis 4;
BA_ "UserSigValidity" SG_ 3221225472 L_ATCU_RrDrvModDis 7;
BA_ "Version" SG_ 3221225472 L_ATCU_RrDrvModDis "23.08.13";
BA_ "GenSigSendType" SG_ 3221225472 L_ATCU_RrDrvBlwDis 4;
BA_ "UserSigValidity" SG_ 3221225472 L_ATCU_RrDrvBlwDis 7;
BA_ "Version" SG_ 3221225472 L_ATCU_RrDrvBlwDis "23.08.13";
BA_ "GenSigSendType" SG_ 3221225472 L_ATCU_RrDrvAutoDis 4;
BA_ "UserSigValidity" SG_ 3221225472 L_ATCU_RrDrvAutoDis 7;
BA_ "Version" SG_ 3221225472 L_ATCU_RrDrvAutoDis "23.08.13";
BA_ "GenSigSendType" SG_ 3221225472 L_ATCU_RrDrvMultiAutoBlwDis 4;
BA_ "UserSigValidity" SG_ 3221225472 L_ATCU_RrDrvMultiAutoBlwDis 7;
BA_ "Version" SG_ 3221225472 L_ATCU_RrDrvMultiAutoBlwDis "23.08.13";
BA_ "Description" SG_ 3221225472 L_ATCU_RrDrvTempCDis "This signal indicates Outside temperature (¡É).

(Use for display only)";
BA_ "GenSigSendType" SG_ 3221225472 L_ATCU_RrDrvTempCDis 4;
BA_ "UserSigValidity" SG_ 3221225472 L_ATCU_RrDrvTempCDis 7;
BA_ "Version" SG_ 3221225472 L_ATCU_RrDrvTempCDis "23.08.13";
BA_ "GenSigSendType" SG_ 3221225472 L_ATCU_RrSyncDis 4;
BA_ "UserSigValidity" SG_ 3221225472 L_ATCU_RrSyncDis 7;
BA_ "Version" SG_ 3221225472 L_ATCU_RrSyncDis "23.08.13";
BA_ "GenSigSendType" SG_ 3221225472 L_ATCU_RrLcdBckLightSta 4;
BA_ "UserSigValidity" SG_ 3221225472 L_ATCU_RrLcdBckLightSta 7;
BA_ "Version" SG_ 3221225472 L_ATCU_RrLcdBckLightSta "23.08.13";
BA_ "GenSigSendType" SG_ 3221225472 L_ATCU_RrGUIBlankDis 4;
BA_ "UserSigValidity" SG_ 3221225472 L_ATCU_RrGUIBlankDis 7;
BA_ "Version" SG_ 3221225472 L_ATCU_RrGUIBlankDis "23.08.13";
BA_ "GenSigSendType" SG_ 3221225472 L_ATCU_RLStHeatSwHInd 4;
BA_ "UserSigValidity" SG_ 3221225472 L_ATCU_RLStHeatSwHInd 7;
BA_ "Version" SG_ 3221225472 L_ATCU_RLStHeatSwHInd "23.08.13";
BA_ "GenSigSendType" SG_ 3221225472 L_ATCU_RLStHeatSwMInd 4;
BA_ "UserSigValidity" SG_ 3221225472 L_ATCU_RLStHeatSwMInd 7;
BA_ "Version" SG_ 3221225472 L_ATCU_RLStHeatSwMInd "23.08.13";
BA_ "GenSigSendType" SG_ 3221225472 L_ATCU_RLStHeatSwLInd 4;
BA_ "UserSigValidity" SG_ 3221225472 L_ATCU_RLStHeatSwLInd 7;
BA_ "Version" SG_ 3221225472 L_ATCU_RLStHeatSwLInd "23.08.13";
BA_ "GenSigSendType" SG_ 3221225472 L_ATCU_RLStVntSwHInd 4;
BA_ "UserSigValidity" SG_ 3221225472 L_ATCU_RLStVntSwHInd 7;
BA_ "Version" SG_ 3221225472 L_ATCU_RLStVntSwHInd "23.08.13";
BA_ "GenSigSendType" SG_ 3221225472 L_ATCU_RLStVntSwMInd 4;
BA_ "UserSigValidity" SG_ 3221225472 L_ATCU_RLStVntSwMInd 7;
BA_ "Version" SG_ 3221225472 L_ATCU_RLStVntSwMInd "23.08.13";
BA_ "GenSigSendType" SG_ 3221225472 L_ATCU_RLStVntSwLInd 4;
BA_ "UserSigValidity" SG_ 3221225472 L_ATCU_RLStVntSwLInd 7;
BA_ "Version" SG_ 3221225472 L_ATCU_RLStVntSwLInd "23.08.13";
BA_ "GenSigSendType" SG_ 3221225472 L_ATCU_RRStHeatSwHInd 4;
BA_ "UserSigValidity" SG_ 3221225472 L_ATCU_RRStHeatSwHInd 7;
BA_ "Version" SG_ 3221225472 L_ATCU_RRStHeatSwHInd "23.08.13";
BA_ "GenSigSendType" SG_ 3221225472 L_ATCU_RRStHeatSwMInd 4;
BA_ "UserSigValidity" SG_ 3221225472 L_ATCU_RRStHeatSwMInd 7;
BA_ "Version" SG_ 3221225472 L_ATCU_RRStHeatSwMInd "23.08.13";
BA_ "GenSigSendType" SG_ 3221225472 L_ATCU_RRStHeatSwLInd 4;
BA_ "UserSigValidity" SG_ 3221225472 L_ATCU_RRStHeatSwLInd 7;
BA_ "Version" SG_ 3221225472 L_ATCU_RRStHeatSwLInd "23.08.13";
BA_ "GenSigSendType" SG_ 3221225472 L_ATCU_RRStVntSwHInd 4;
BA_ "UserSigValidity" SG_ 3221225472 L_ATCU_RRStVntSwHInd 7;
BA_ "Version" SG_ 3221225472 L_ATCU_RRStVntSwHInd "23.08.13";
BA_ "GenSigSendType" SG_ 3221225472 L_ATCU_RRStVntSwMInd 4;
BA_ "UserSigValidity" SG_ 3221225472 L_ATCU_RRStVntSwMInd 7;
BA_ "Version" SG_ 3221225472 L_ATCU_RRStVntSwMInd "23.08.13";
BA_ "GenSigSendType" SG_ 3221225472 L_ATCU_RRStVntSwLInd 4;
BA_ "UserSigValidity" SG_ 3221225472 L_ATCU_RRStVntSwLInd 7;
BA_ "Version" SG_ 3221225472 L_ATCU_RRStVntSwLInd "23.08.13";
BA_ "GenSigSendType" SG_ 3221225472 L_ATCU_RrMTCOpSta 4;
BA_ "UserSigValidity" SG_ 3221225472 L_ATCU_RrMTCOpSta 7;
BA_ "Version" SG_ 3221225472 L_ATCU_RrMTCOpSta "23.08.13";
BA_ "GenSigSendType" SG_ 3221225472 L_ATCU_RrMTCTempLvl 4;
BA_ "UserSigValidity" SG_ 3221225472 L_ATCU_RrMTCTempLvl 7;
BA_ "Version" SG_ 3221225472 L_ATCU_RrMTCTempLvl "23.08.13";
BA_ "GenSigSendType" SG_ 3221225472 L_ATCU_RrPsModDis 4;
BA_ "UserSigValidity" SG_ 3221225472 L_ATCU_RrPsModDis 7;
BA_ "Version" SG_ 3221225472 L_ATCU_RrPsModDis "23.08.13";
BA_ "GenSigSendType" SG_ 3221225472 L_ATCU_RrLockDis 4;
BA_ "UserSigValidity" SG_ 3221225472 L_ATCU_RrLockDis 7;
BA_ "Version" SG_ 3221225472 L_ATCU_RrLockDis "23.08.13";
BA_ "GenSigSendType" SG_ 3221225472 L_ATCU_RrDrvAutoStep 4;
BA_ "UserSigValidity" SG_ 3221225472 L_ATCU_RrDrvAutoStep 7;
BA_ "Version" SG_ 3221225472 L_ATCU_RrDrvAutoStep "23.08.13";
BA_ "GenSigSendType" SG_ 3221225472 L_ATCU_PassAUTOStep 4;
BA_ "UserSigValidity" SG_ 3221225472 L_ATCU_PassAUTOStep 7;
BA_ "Version" SG_ 3221225472 L_ATCU_PassAUTOStep "23.08.13";
BA_ "GenSigSendType" SG_ 3221225472 L_ATCU_RrPassTempFDis 4;
BA_ "UserSigValidity" SG_ 3221225472 L_ATCU_RrPassTempFDis 7;
BA_ "Version" SG_ 3221225472 L_ATCU_RrPassTempFDis "23.08.13";
BA_ "GenSigSendType" SG_ 3221225472 L_ATCU_RrPassBlwDis 4;
BA_ "UserSigValidity" SG_ 3221225472 L_ATCU_RrPassBlwDis 7;
BA_ "Version" SG_ 3221225472 L_ATCU_RrPassBlwDis "23.08.13";
BA_ "GenSigSendType" SG_ 3221225472 L_ATCU_RrPassAUTODis 4;
BA_ "UserSigValidity" SG_ 3221225472 L_ATCU_RrPassAUTODis 7;
BA_ "Version" SG_ 3221225472 L_ATCU_RrPassAUTODis "23.08.13";
BA_ "GenSigSendType" SG_ 3221225472 L_ATCU_RrPassAUTOStep 4;
BA_ "UserSigValidity" SG_ 3221225472 L_ATCU_RrPassAUTOStep 7;
BA_ "Version" SG_ 3221225472 L_ATCU_RrPassAUTOStep "23.08.13";
BA_ "Description" SG_ 3221225472 L_ATCU_CampModeSta "Define the status of Camp Mode in EV";
BA_ "GenSigSendType" SG_ 3221225472 L_ATCU_CampModeSta 4;
BA_ "UserSigValidity" SG_ 3221225472 L_ATCU_CampModeSta 7;
BA_ "Version" SG_ 3221225472 L_ATCU_CampModeSta "23.08.13";
BA_ "GenSigSendType" SG_ 3221225472 L_ATCU_RrPassTempCDis 4;
BA_ "UserSigValidity" SG_ 3221225472 L_ATCU_RrPassTempCDis 7;
BA_ "Version" SG_ 3221225472 L_ATCU_RrPassTempCDis "23.08.13";
BA_ "Description" SG_ 3221225472 L_ATCU_UtilModeUsmSta "Timeout : Utility Mode OFF(Rest Mode OFF)";
BA_ "GenSigSendType" SG_ 3221225472 L_ATCU_UtilModeUsmSta 4;
BA_ "UserSigValidity" SG_ 3221225472 L_ATCU_UtilModeUsmSta 7;
BA_ "Version" SG_ 3221225472 L_ATCU_UtilModeUsmSta "23.08.13";
BA_ "Description" SG_ 3221225472 L_ATCU_OutTempDispC "This signal indicates Outside temperature (¡É).

(Use for display only)";
BA_ "UserSigValidity" SG_ 3221225472 L_ATCU_OutTempDispC 7;
BA_ "Version" SG_ 3221225472 L_ATCU_OutTempDispC "23.08.13";
BA_ "UserSigValidity" SG_ 3221225472 L_ATCU_DtntOutSta 7;
BA_ "Version" SG_ 3221225472 L_ATCU_DtntOutSta "23.08.13";
BA_ "UserSigValidity" SG_ 3221225472 L_ATCU_AutoBrightSta 7;
BA_ "Version" SG_ 3221225472 L_ATCU_AutoBrightSta "23.08.13";
BA_ "UserSigValidity" SG_ 3221225472 L_ATCU_DustSnrVal 7;
BA_ "Version" SG_ 3221225472 L_ATCU_DustSnrVal "23.08.13";
BA_ "Description" SG_ 3221225472 L_ATCU_NotMinModeBrightSta "This signal indicates the bright level of original state. Original state means the previous state of Camp Mode.";
BA_ "UserSigValidity" SG_ 3221225472 L_ATCU_NotMinModeBrightSta 7;
BA_ "Version" SG_ 3221225472 L_ATCU_NotMinModeBrightSta "23.08.13";
BA_ "Description" SG_ 3221225472 L_ATCU_OutTempDispF "This signal indicates Outside Temperature (¢µ)

(Use for display only)";
BA_ "UserSigValidity" SG_ 3221225472 L_ATCU_OutTempDispF 7;
BA_ "Version" SG_ 3221225472 L_ATCU_OutTempDispF "23.08.13";
BA_ "GenSigSendType" SG_ 3221225472 L_ATCU_SW_Ver1 4;
BA_ "UserSigValidity" SG_ 3221225472 L_ATCU_SW_Ver1 7;
BA_ "Version" SG_ 3221225472 L_ATCU_SW_Ver1 "23.08.13";
BA_ "GenSigSendType" SG_ 3221225472 L_ATCU_SW_Ver3 4;
BA_ "UserSigValidity" SG_ 3221225472 L_ATCU_SW_Ver3 7;
BA_ "Version" SG_ 3221225472 L_ATCU_SW_Ver3 "23.08.13";
BA_ "GenSigSendType" SG_ 3221225472 L_ATCU_SW_Ver4 4;
BA_ "UserSigValidity" SG_ 3221225472 L_ATCU_SW_Ver4 7;
BA_ "Version" SG_ 3221225472 L_ATCU_SW_Ver4 "23.08.13";
BA_ "GenSigSendType" SG_ 3221225472 L_ATCU_SW_Ver5 4;
BA_ "UserSigValidity" SG_ 3221225472 L_ATCU_SW_Ver5 7;
BA_ "Version" SG_ 3221225472 L_ATCU_SW_Ver5 "23.08.13";
BA_ "GenSigSendType" SG_ 3221225472 L_ATCU_SW_Ver2 4;
BA_ "UserSigValidity" SG_ 3221225472 L_ATCU_SW_Ver2 7;
BA_ "Version" SG_ 3221225472 L_ATCU_SW_Ver2 "23.08.13";
BA_ "UserSigValidity" SG_ 3221225472 L_ATCU_RHPTCOpPrmssnSta 7;
BA_ "Version" SG_ 3221225472 L_ATCU_RHPTCOpPrmssnSta "23.08.13";
BA_ "Description" SG_ 3221225472 L_ATCU_xEV_BMSRomTyp2 "BMS rom type variation of Battery Pack Specification";
BA_ "UserSigValidity" SG_ 3221225472 L_ATCU_xEV_BMSRomTyp2 7;
BA_ "Version" SG_ 3221225472 L_ATCU_xEV_BMSRomTyp2 "23.08.13";
BA_ "UserSigValidity" SG_ 3221225472 L_ATCU_RHPTCFlrTrgtDty 7;
BA_ "Version" SG_ 3221225472 L_ATCU_RHPTCFlrTrgtDty "23.08.13";
BA_ "UserSigValidity" SG_ 3221225472 L_ATCU_RHPTCDischrgReq 7;
BA_ "Version" SG_ 3221225472 L_ATCU_RHPTCDischrgReq "23.08.13";
BA_ "Description" SG_ 3221225472 L_ATCU_FltMsgTmOutRHPTC1 "Message Timeout of RHPTC_01";
BA_ "UserSigValidity" SG_ 3221225472 L_ATCU_FltMsgTmOutRHPTC1 7;
BA_ "Version" SG_ 3221225472 L_ATCU_FltMsgTmOutRHPTC1 "23.08.13";
BA_ "Description" SG_ 3221225472 L_ATCU_FltMsgTmOutRHPTC2 "Message Timeout of RHPTC_02";
BA_ "UserSigValidity" SG_ 3221225472 L_ATCU_FltMsgTmOutRHPTC2 7;
BA_ "Version" SG_ 3221225472 L_ATCU_FltMsgTmOutRHPTC2 "23.08.13";
BA_ "Description" SG_ 3221225472 L_ATCU_FltMsgTmOutRHPTC3 "Message Timeout of RHPTC_03";
BA_ "UserSigValidity" SG_ 3221225472 L_ATCU_FltMsgTmOutRHPTC3 7;
BA_ "Version" SG_ 3221225472 L_ATCU_FltMsgTmOutRHPTC3 "23.08.13";
BA_ "Description" SG_ 3221225472 L_ATCU_FltMsgTmOutRHPTC4 "Message Timeout of RHPTC_04";
BA_ "UserSigValidity" SG_ 3221225472 L_ATCU_FltMsgTmOutRHPTC4 7;
BA_ "Version" SG_ 3221225472 L_ATCU_FltMsgTmOutRHPTC4 "23.08.13";
BA_ "Description" SG_ 3221225472 L_ATCU_RrBlwLvl "This signal indicates step of Rear blower operation";
BA_ "UserSigValidity" SG_ 3221225472 L_ATCU_RrBlwLvl 7;
BA_ "Version" SG_ 3221225472 L_ATCU_RrBlwLvl "23.08.13";
BA_ "Description" SG_ 3221225472 L_ATCU_RrBlwLvlSigVaildSta "This signal sindicates the validation of 'blower level signal'

Initial value is 0x0(Invalid, do not send information of blower level)";
BA_ "UserSigValidity" SG_ 3221225472 L_ATCU_RrBlwLvlSigVaildSta 7;
BA_ "Version" SG_ 3221225472 L_ATCU_RrBlwLvlSigVaildSta "23.08.13";
BA_ "Description" SG_ 3221225472 L_ATCU_OutTempSnsrVal2 "Actual temperature of Ambient Sensor via an A/D converter; converted into degrees

centigrade (¡É).

This is raw data of ambient sensor; just transferred from Ambient Sensor Voltage.";
BA_ "UserSigValidity" SG_ 3221225472 L_ATCU_OutTempSnsrVal2 7;
BA_ "Version" SG_ 3221225472 L_ATCU_OutTempSnsrVal2 "23.08.13";
BA_ "UserSigValidity" SG_ 3221225472 L_ATCU_RHPTCRoofTrgtDty 7;
BA_ "Version" SG_ 3221225472 L_ATCU_RHPTCRoofTrgtDty "23.08.13";
BA_ "UserSigValidity" SG_ 3221225472 L_ATCU_RrBlwFltSta 7;
BA_ "Version" SG_ 3221225472 L_ATCU_RrBlwFltSta "23.08.13";
BA_ "UserSigValidity" SG_ 3221225472 RHPTC_FlrFlt 7;
BA_ "Version" SG_ 3221225472 RHPTC_FlrFlt "23.08.08";
BA_ "UserSigValidity" SG_ 3221225472 RHPTC_FlrFltLVLow 7;
BA_ "Version" SG_ 3221225472 RHPTC_FlrFltLVLow "23.08.08";
BA_ "UserSigValidity" SG_ 3221225472 RHPTC_FlrFailLVSnr 7;
BA_ "Version" SG_ 3221225472 RHPTC_FlrFailLVSnr "23.08.08";
BA_ "UserSigValidity" SG_ 3221225472 RHPTC_FlrFailCuFLRentSnr 7;
BA_ "Version" SG_ 3221225472 RHPTC_FlrFailCuFLRentSnr "23.08.08";
BA_ "UserSigValidity" SG_ 3221225472 RHPTC_FlrrFailCoreTempSnr 7;
BA_ "Version" SG_ 3221225472 RHPTC_FlrrFailCoreTempSnr "23.08.08";
BA_ "UserSigValidity" SG_ 3221225472 RHPTC_FlrFailPcbTempSnr 7;
BA_ "Version" SG_ 3221225472 RHPTC_FlrFailPcbTempSnr "23.08.08";
BA_ "UserSigValidity" SG_ 3221225472 RHPTC_FlrFailIGBT 7;
BA_ "Version" SG_ 3221225472 RHPTC_FlrFailIGBT "23.08.08";
BA_ "UserSigValidity" SG_ 3221225472 RHPTC_FlrFailOpenLoad 7;
BA_ "Version" SG_ 3221225472 RHPTC_FlrFailOpenLoad "23.08.08";
BA_ "UserSigValidity" SG_ 3221225472 RHPTC_FlrLtdOpCause 7;
BA_ "Version" SG_ 3221225472 RHPTC_FlrLtdOpCause "23.08.08";
BA_ "UserSigValidity" SG_ 3221225472 RHPTC_FlrFltLVHigh 7;
BA_ "Version" SG_ 3221225472 RHPTC_FlrFltLVHigh "23.08.08";
BA_ "UserSigValidity" SG_ 3221225472 RHPTC_FlrSwrVer 7;
BA_ "Version" SG_ 3221225472 RHPTC_FlrSwrVer "23.08.08";
BA_ "UserSigValidity" SG_ 3221225472 RHPTC_FlrFltHVLow 7;
BA_ "Version" SG_ 3221225472 RHPTC_FlrFltHVLow "23.08.08";
BA_ "UserSigValidity" SG_ 3221225472 RHPTC_FlrFltHVHigh 7;
BA_ "Version" SG_ 3221225472 RHPTC_FlrFltHVHigh "23.08.08";
BA_ "UserSigValidity" SG_ 3221225472 RHPTC_FlrFltOverCuFLRent 7;
BA_ "Version" SG_ 3221225472 RHPTC_FlrFltOverCuFLRent "23.08.08";
BA_ "UserSigValidity" SG_ 3221225472 RHPTC_FlrFltThermalShutDn 7;
BA_ "Version" SG_ 3221225472 RHPTC_FlrFltThermalShutDn "23.08.08";
BA_ "UserSigValidity" SG_ 3221225472 RHPTC_FlrFltPcbThermalShutDn 7;
BA_ "Version" SG_ 3221225472 RHPTC_FlrFltPcbThermalShutDn "23.08.08";
BA_ "UserSigValidity" SG_ 3221225472 RHPTC_FlrFltMsgTmOutATCU 7;
BA_ "Version" SG_ 3221225472 RHPTC_FlrFltMsgTmOutATCU "23.08.08";
BA_ "UserSigValidity" SG_ 3221225472 RHPTC_FlrFailHVSnr 7;
BA_ "Version" SG_ 3221225472 RHPTC_FlrFailHVSnr "23.08.08";
BA_ "UserSigValidity" SG_ 3221225472 RHPTC_FlrRdySta 7;
BA_ "Version" SG_ 3221225472 RHPTC_FlrRdySta "23.08.08";
BA_ "UserSigValidity" SG_ 3221225472 RHPTC_FlrOpSta 7;
BA_ "Version" SG_ 3221225472 RHPTC_FlrOpSta "23.08.08";
BA_ "UserSigValidity" SG_ 3221225472 RHPTC_FlrCnsmptPwr_W 7;
BA_ "Version" SG_ 3221225472 RHPTC_FlrCnsmptPwr_W "23.08.08";
BA_ "UserSigValidity" SG_ 3221225472 RHPTC_FlrCtrlTyp 7;
BA_ "Version" SG_ 3221225472 RHPTC_FlrCtrlTyp "23.08.08";
BA_ "UserSigValidity" SG_ 3221225472 RHPTC_FlrVoltage_V 7;
BA_ "Version" SG_ 3221225472 RHPTC_FlrVoltage_V "23.08.08";
BA_ "UserSigValidity" SG_ 3221225472 RHPTC_FlrCuFlrent_A 7;
BA_ "Version" SG_ 3221225472 RHPTC_FlrCuFlrent_A "23.08.08";
BA_ "Description" SG_ 3221225472 RHPTC_FlrDutyFB_Pec "Duty Conversion to PTC Consumption power value, 40w~6kw -> 10%~95%";
BA_ "UserSigValidity" SG_ 3221225472 RHPTC_FlrDutyFB_Pec 7;
BA_ "Version" SG_ 3221225472 RHPTC_FlrDutyFB_Pec "23.08.08";
BA_ "Description" SG_ 3221225472 RHPTC_FlrDutyFB_IGBT "PWM DUTY of PTC IGBT (0~100%)";
BA_ "UserSigValidity" SG_ 3221225472 RHPTC_FlrDutyFB_IGBT 7;
BA_ "Version" SG_ 3221225472 RHPTC_FlrDutyFB_IGBT "23.08.08";
BA_ "UserSigValidity" SG_ 3221225472 RHPTC_FlrCoreTemp_C 7;
BA_ "Version" SG_ 3221225472 RHPTC_FlrCoreTemp_C "23.08.08";
BA_ "UserSigValidity" SG_ 3221225472 RHPTC_RoofFlt 7;
BA_ "Version" SG_ 3221225472 RHPTC_RoofFlt "23.08.08";
BA_ "UserSigValidity" SG_ 3221225472 RHPTC_RoofFltLVLow 7;
BA_ "Version" SG_ 3221225472 RHPTC_RoofFltLVLow "23.08.08";
BA_ "UserSigValidity" SG_ 3221225472 RHPTC_RoofFailLVSnr 7;
BA_ "Version" SG_ 3221225472 RHPTC_RoofFailLVSnr "23.08.08";
BA_ "UserSigValidity" SG_ 3221225472 RHPTC_RoofFailCuRoofentSnr 7;
BA_ "Version" SG_ 3221225472 RHPTC_RoofFailCuRoofentSnr "23.08.08";
BA_ "UserSigValidity" SG_ 3221225472 RHPTC_RoofFailCoreTempSnr 7;
BA_ "Version" SG_ 3221225472 RHPTC_RoofFailCoreTempSnr "23.08.08";
BA_ "UserSigValidity" SG_ 3221225472 RHPTC_RoofFailPcbTempSnr 7;
BA_ "Version" SG_ 3221225472 RHPTC_RoofFailPcbTempSnr "23.08.08";
BA_ "UserSigValidity" SG_ 3221225472 RHPTC_RoofFailIGBT 7;
BA_ "Version" SG_ 3221225472 RHPTC_RoofFailIGBT "23.08.08";
BA_ "UserSigValidity" SG_ 3221225472 RHPTC_RoofFailOpenLoad 7;
BA_ "Version" SG_ 3221225472 RHPTC_RoofFailOpenLoad "23.08.08";
BA_ "UserSigValidity" SG_ 3221225472 RHPTC_RoofLtdOpCause 7;
BA_ "Version" SG_ 3221225472 RHPTC_RoofLtdOpCause "23.08.08";
BA_ "UserSigValidity" SG_ 3221225472 RHPTC_RoofFltLVHigh 7;
BA_ "Version" SG_ 3221225472 RHPTC_RoofFltLVHigh "23.08.08";
BA_ "UserSigValidity" SG_ 3221225472 RHPTC_RoofSwVer 7;
BA_ "Version" SG_ 3221225472 RHPTC_RoofSwVer "23.08.08";
BA_ "UserSigValidity" SG_ 3221225472 RHPTC_RoofFltHVLow 7;
BA_ "Version" SG_ 3221225472 RHPTC_RoofFltHVLow "23.08.08";
BA_ "Description" SG_ 3221225472 RHPTC_CnsmptPwrTtl_W "Total Power Consumption Value = RHPTC_RoofConsumptionPower_W + RHPTC_flrConsumptionPower_W";
BA_ "UserSigValidity" SG_ 3221225472 RHPTC_CnsmptPwrTtl_W 7;
BA_ "Version" SG_ 3221225472 RHPTC_CnsmptPwrTtl_W "23.08.08";
BA_ "UserSigValidity" SG_ 3221225472 RHPTC_RoofFltHVHigh 7;
BA_ "Version" SG_ 3221225472 RHPTC_RoofFltHVHigh "23.08.08";
BA_ "UserSigValidity" SG_ 3221225472 RHPTC_IntlkSta 7;
BA_ "Version" SG_ 3221225472 RHPTC_IntlkSta "23.08.08";
BA_ "UserSigValidity" SG_ 3221225472 RHPTC_RoofFltOverCuRoofent 7;
BA_ "Version" SG_ 3221225472 RHPTC_RoofFltOverCuRoofent "23.08.08";
BA_ "UserSigValidity" SG_ 3221225472 RHPTC_RoofFltThermalShutDn 7;
BA_ "Version" SG_ 3221225472 RHPTC_RoofFltThermalShutDn "23.08.08";
BA_ "UserSigValidity" SG_ 3221225472 RHPTC_RoofFltPcbThermalShutDn 7;
BA_ "Version" SG_ 3221225472 RHPTC_RoofFltPcbThermalShutDn "23.08.08";
BA_ "UserSigValidity" SG_ 3221225472 RHPTC_RoofFltMsgTmOutATCU 7;
BA_ "Version" SG_ 3221225472 RHPTC_RoofFltMsgTmOutATCU "23.08.08";
BA_ "UserSigValidity" SG_ 3221225472 RHPTC_RoofFailHVSnr 7;
BA_ "Version" SG_ 3221225472 RHPTC_RoofFailHVSnr "23.08.08";
BA_ "UserSigValidity" SG_ 3221225472 RHPTC_RoofRdySta 7;
BA_ "Version" SG_ 3221225472 RHPTC_RoofRdySta "23.08.08";
BA_ "UserSigValidity" SG_ 3221225472 RHPTC_RoofOpSta 7;
BA_ "Version" SG_ 3221225472 RHPTC_RoofOpSta "23.08.08";
BA_ "UserSigValidity" SG_ 3221225472 RHPTC_RoofCnsmptPwr_W 7;
BA_ "Version" SG_ 3221225472 RHPTC_RoofCnsmptPwr_W "23.08.08";
BA_ "UserSigValidity" SG_ 3221225472 RHPTC_RoofVoltage_V 7;
BA_ "Version" SG_ 3221225472 RHPTC_RoofVoltage_V "23.08.08";
BA_ "UserSigValidity" SG_ 3221225472 RHPTC_RoofCtrlTyp 7;
BA_ "Version" SG_ 3221225472 RHPTC_RoofCtrlTyp "23.08.08";
BA_ "UserSigValidity" SG_ 3221225472 RHPTC_RoofCuRoofent_A 7;
BA_ "Version" SG_ 3221225472 RHPTC_RoofCuRoofent_A "23.08.08";
BA_ "Description" SG_ 3221225472 RHPTC_RoofDutyFB_Pec "Duty Conversion to PTC Consumption power value, 40w~6kw -> 10%~95%";
BA_ "UserSigValidity" SG_ 3221225472 RHPTC_RoofDutyFB_Pec 7;
BA_ "Version" SG_ 3221225472 RHPTC_RoofDutyFB_Pec "23.08.08";
BA_ "Description" SG_ 3221225472 RHPTC_RoofDutyFB_IGBT "PWM DUTY of PTC IGBT (0~100%)";
BA_ "UserSigValidity" SG_ 3221225472 RHPTC_RoofDutyFB_IGBT 7;
BA_ "Version" SG_ 3221225472 RHPTC_RoofDutyFB_IGBT "23.08.08";
BA_ "UserSigValidity" SG_ 3221225472 RHPTC_RoofCoreTemp_C 7;
BA_ "Version" SG_ 3221225472 RHPTC_RoofCoreTemp_C "23.08.08";
BA_ "UserSigValidity" SG_ 1332 L_ATCU_FHPTCOpPrmssnSta 7;
BA_ "Version" SG_ 1332 L_ATCU_FHPTCOpPrmssnSta "23.08.13";
BA_ "Description" SG_ 1332 L_ATCU_xEV_BMSRomTyp "BMS Rom type variation of Battery Pack Specification";
BA_ "UserSigValidity" SG_ 1332 L_ATCU_xEV_BMSRomTyp 7;
BA_ "Version" SG_ 1332 L_ATCU_xEV_BMSRomTyp "23.08.13";
BA_ "UserSigValidity" SG_ 1332 L_ATCU_FHPTCPassTrgtDty 7;
BA_ "Version" SG_ 1332 L_ATCU_FHPTCPassTrgtDty "23.08.13";
BA_ "UserSigValidity" SG_ 1332 L_ATCU_FHPTCDischrgReq 7;
BA_ "Version" SG_ 1332 L_ATCU_FHPTCDischrgReq "23.08.13";
BA_ "Description" SG_ 1332 L_ATCU_FltMsgTmOutFHPTC1 "Message Timeout of FHPTC_01";
BA_ "UserSigValidity" SG_ 1332 L_ATCU_FltMsgTmOutFHPTC1 7;
BA_ "Version" SG_ 1332 L_ATCU_FltMsgTmOutFHPTC1 "23.08.13";
BA_ "Description" SG_ 1332 L_ATCU_FltMsgTmOutFHPTC2 "Message Timeout of FHPTC_02";
BA_ "UserSigValidity" SG_ 1332 L_ATCU_FltMsgTmOutFHPTC2 7;
BA_ "Version" SG_ 1332 L_ATCU_FltMsgTmOutFHPTC2 "23.08.13";
BA_ "Description" SG_ 1332 L_ATCU_FltMsgTmOutFHPTC3 "Message Timeout of FHPTC_03";
BA_ "UserSigValidity" SG_ 1332 L_ATCU_FltMsgTmOutFHPTC3 7;
BA_ "Version" SG_ 1332 L_ATCU_FltMsgTmOutFHPTC3 "23.08.13";
BA_ "Description" SG_ 1332 L_ATCU_FltMsgTmOutFHPTC4 "Message Timeout of FHPTC_04";
BA_ "UserSigValidity" SG_ 1332 L_ATCU_FltMsgTmOutFHPTC4 7;
BA_ "Version" SG_ 1332 L_ATCU_FltMsgTmOutFHPTC4 "23.08.13";
BA_ "Description" SG_ 1332 L_ATCU_FrBlwLvl "This signal indicates step of Front blower operation";
BA_ "UserSigValidity" SG_ 1332 L_ATCU_FrBlwLvl 7;
BA_ "Version" SG_ 1332 L_ATCU_FrBlwLvl "23.08.13";
BA_ "Description" SG_ 1332 L_ATCU_FrBlwLvlSigVaildSta "This signal sindicates the validation of 'blower level signal'

Initial value is 0x0(Invalid, do not send information of blower level)";
BA_ "UserSigValidity" SG_ 1332 L_ATCU_FrBlwLvlSigVaildSta 7;
BA_ "Version" SG_ 1332 L_ATCU_FrBlwLvlSigVaildSta "23.08.13";
BA_ "Description" SG_ 1332 L_ATCU_OutTempSnsrVal "Actual temperature of Ambient Sensor via an A/D converter; converted into degrees

centigrade (¡É).

This is raw data of ambient sensor; just transferred from Ambient Sensor Voltage.";
BA_ "UserSigValidity" SG_ 1332 L_ATCU_OutTempSnsrVal 7;
BA_ "Version" SG_ 1332 L_ATCU_OutTempSnsrVal "23.08.13";
BA_ "Description" SG_ 1332 L_ATCU_DrvrSdTyp "This signal indicates information of driver type (LHD/RHD)";
BA_ "UserSigValidity" SG_ 1332 L_ATCU_DrvrSdTyp 7;
BA_ "Version" SG_ 1332 L_ATCU_DrvrSdTyp "23.08.13";
BA_ "UserSigValidity" SG_ 1332 L_ATCU_FrBlwFltSta 7;
BA_ "Version" SG_ 1332 L_ATCU_FrBlwFltSta "23.08.13";
BA_ "UserSigValidity" SG_ 1332 L_ATCU_PassBlwLvl 7;
BA_ "Version" SG_ 1332 L_ATCU_PassBlwLvl "23.08.13";
BA_ "UserSigValidity" SG_ 1332 L_ATCU_FHPTCDrTrgtDty 7;
BA_ "Version" SG_ 1332 L_ATCU_FHPTCDrTrgtDty "23.08.13";
BA_ "GenSigStartValue" SG_ 1329 FHPTC_PassWd 29734815;
BA_ "UserSigValidity" SG_ 273 L_ATCU_FHPTCOpPrmssnSta 7;
BA_ "Version" SG_ 273 L_ATCU_FHPTCOpPrmssnSta "23.08.13";
BA_ "Description" SG_ 273 L_ATCU_xEV_BMSRomTyp "BMS Rom type variation of Battery Pack Specification";
BA_ "UserSigValidity" SG_ 273 L_ATCU_xEV_BMSRomTyp 7;
BA_ "Version" SG_ 273 L_ATCU_xEV_BMSRomTyp "23.08.13";
BA_ "UserSigValidity" SG_ 273 L_ATCU_FHPTCPassTrgtDty 7;
BA_ "Version" SG_ 273 L_ATCU_FHPTCPassTrgtDty "23.08.13";
BA_ "UserSigValidity" SG_ 273 L_ATCU_FHPTCDischrgReq 7;
BA_ "Version" SG_ 273 L_ATCU_FHPTCDischrgReq "23.08.13";
BA_ "Description" SG_ 273 L_ATCU_FltMsgTmOutFHPTC1 "Message Timeout of FHPTC_01";
BA_ "UserSigValidity" SG_ 273 L_ATCU_FltMsgTmOutFHPTC1 7;
BA_ "Version" SG_ 273 L_ATCU_FltMsgTmOutFHPTC1 "23.08.13";
BA_ "Description" SG_ 273 L_ATCU_FltMsgTmOutFHPTC2 "Message Timeout of FHPTC_02";
BA_ "UserSigValidity" SG_ 273 L_ATCU_FltMsgTmOutFHPTC2 7;
BA_ "Version" SG_ 273 L_ATCU_FltMsgTmOutFHPTC2 "23.08.13";
BA_ "Description" SG_ 273 L_ATCU_FltMsgTmOutFHPTC3 "Message Timeout of FHPTC_03";
BA_ "UserSigValidity" SG_ 273 L_ATCU_FltMsgTmOutFHPTC3 7;
BA_ "Version" SG_ 273 L_ATCU_FltMsgTmOutFHPTC3 "23.08.13";
BA_ "Description" SG_ 273 L_ATCU_FltMsgTmOutFHPTC4 "Message Timeout of FHPTC_04";
BA_ "UserSigValidity" SG_ 273 L_ATCU_FltMsgTmOutFHPTC4 7;
BA_ "Version" SG_ 273 L_ATCU_FltMsgTmOutFHPTC4 "23.08.13";
BA_ "Description" SG_ 273 L_ATCU_FrBlwLvl "This signal indicates step of Front blower operation";
BA_ "UserSigValidity" SG_ 273 L_ATCU_FrBlwLvl 7;
BA_ "Version" SG_ 273 L_ATCU_FrBlwLvl "23.08.13";
BA_ "Description" SG_ 273 L_ATCU_FrBlwLvlSigVaildSta "This signal sindicates the validation of 'blower level signal'

Initial value is 0x0(Invalid, do not send information of blower level)";
BA_ "UserSigValidity" SG_ 273 L_ATCU_FrBlwLvlSigVaildSta 7;
BA_ "Version" SG_ 273 L_ATCU_FrBlwLvlSigVaildSta "23.08.13";
BA_ "Description" SG_ 273 L_ATCU_OutTempSnsrVal "Actual temperature of Ambient Sensor via an A/D converter; converted into degrees

centigrade (¡É).

This is raw data of ambient sensor; just transferred from Ambient Sensor Voltage.";
BA_ "UserSigValidity" SG_ 273 L_ATCU_OutTempSnsrVal 7;
BA_ "Version" SG_ 273 L_ATCU_OutTempSnsrVal "23.08.13";
BA_ "Description" SG_ 273 L_ATCU_DrvrSdTyp "This signal indicates information of driver type (LHD/RHD)";
BA_ "UserSigValidity" SG_ 273 L_ATCU_DrvrSdTyp 7;
BA_ "Version" SG_ 273 L_ATCU_DrvrSdTyp "23.08.13";
BA_ "UserSigValidity" SG_ 273 L_ATCU_FrBlwFltSta 7;
BA_ "Version" SG_ 273 L_ATCU_FrBlwFltSta "23.08.13";
BA_ "UserSigValidity" SG_ 273 L_ATCU_PassBlwLvl 7;
BA_ "Version" SG_ 273 L_ATCU_PassBlwLvl "23.08.13";
BA_ "UserSigValidity" SG_ 273 L_ATCU_FHPTCDrTrgtDty 7;
BA_ "Version" SG_ 273 L_ATCU_FHPTCDrTrgtDty "23.08.13";
BA_ "UserSigValidity" SG_ 322 FHPTC_PassRdySta 7;
BA_ "Version" SG_ 322 FHPTC_PassRdySta "23.08.08";
BA_ "UserSigValidity" SG_ 322 FHPTC_PassOpSta 7;
BA_ "Version" SG_ 322 FHPTC_PassOpSta "23.08.08";
BA_ "UserSigValidity" SG_ 322 FHPTC_PassCnsmptPwr_W 7;
BA_ "Version" SG_ 322 FHPTC_PassCnsmptPwr_W "23.08.08";
BA_ "UserSigValidity" SG_ 322 FHPTC_PassCtrlTyp 7;
BA_ "Version" SG_ 322 FHPTC_PassCtrlTyp "23.08.08";
BA_ "UserSigValidity" SG_ 322 FHPTC_PassVoltage_V 7;
BA_ "Version" SG_ 322 FHPTC_PassVoltage_V "23.08.08";
BA_ "UserSigValidity" SG_ 322 FHPTC_PassCurrent_A 7;
BA_ "Version" SG_ 322 FHPTC_PassCurrent_A "23.08.08";
BA_ "Description" SG_ 322 FHPTC_PassDutyFB_Pec "Duty Conversion to PTC Consumption power value, 40w~6kw -> 10%~95%";
BA_ "UserSigValidity" SG_ 322 FHPTC_PassDutyFB_Pec 7;
BA_ "Version" SG_ 322 FHPTC_PassDutyFB_Pec "23.08.08";
BA_ "Description" SG_ 322 FHPTC_PassDutyFB_IGBT "PWM DUTY of PTC IGBT (0~100%)";
BA_ "UserSigValidity" SG_ 322 FHPTC_PassDutyFB_IGBT 7;
BA_ "Version" SG_ 322 FHPTC_PassDutyFB_IGBT "23.08.08";
BA_ "UserSigValidity" SG_ 322 FHPTC_PassCoreTemp_C 7;
BA_ "Version" SG_ 322 FHPTC_PassCoreTemp_C "23.08.08";
BA_ "UserSigValidity" SG_ 323 FHPTC_PassFlt 7;
BA_ "Version" SG_ 323 FHPTC_PassFlt "23.08.08";
BA_ "UserSigValidity" SG_ 323 FHPTC_PassFltLVLow 7;
BA_ "Version" SG_ 323 FHPTC_PassFltLVLow "23.08.08";
BA_ "UserSigValidity" SG_ 323 FHPTC_PassFailLVSnr 7;
BA_ "Version" SG_ 323 FHPTC_PassFailLVSnr "23.08.08";
BA_ "UserSigValidity" SG_ 323 FHPTC_PassFailCurrentSnr 7;
BA_ "Version" SG_ 323 FHPTC_PassFailCurrentSnr "23.08.08";
BA_ "UserSigValidity" SG_ 323 FHPTC_PassFailCoreTempSnr 7;
BA_ "Version" SG_ 323 FHPTC_PassFailCoreTempSnr "23.08.08";
BA_ "UserSigValidity" SG_ 323 FHPTC_PassFailPcbTempSnr 7;
BA_ "Version" SG_ 323 FHPTC_PassFailPcbTempSnr "23.08.08";
BA_ "UserSigValidity" SG_ 323 FHPTC_PassFailIGBT 7;
BA_ "Version" SG_ 323 FHPTC_PassFailIGBT "23.08.08";
BA_ "UserSigValidity" SG_ 323 FHPTC_PassFailOpenLoad 7;
BA_ "Version" SG_ 323 FHPTC_PassFailOpenLoad "23.08.08";
BA_ "UserSigValidity" SG_ 323 FHPTC_PassLtdOpCause 7;
BA_ "Version" SG_ 323 FHPTC_PassLtdOpCause "23.08.08";
BA_ "UserSigValidity" SG_ 323 FHPTC_PassFltLVHigh 7;
BA_ "Version" SG_ 323 FHPTC_PassFltLVHigh "23.08.08";
BA_ "UserSigValidity" SG_ 323 FHPTC_PassSwVer 7;
BA_ "Version" SG_ 323 FHPTC_PassSwVer "23.08.08";
BA_ "UserSigValidity" SG_ 323 FHPTC_PassFltHVLow 7;
BA_ "Version" SG_ 323 FHPTC_PassFltHVLow "23.08.08";
BA_ "UserSigValidity" SG_ 323 FHPTC_PassFltHVHigh 7;
BA_ "Version" SG_ 323 FHPTC_PassFltHVHigh "23.08.08";
BA_ "UserSigValidity" SG_ 323 FHPTC_PassFltOverCurrent 7;
BA_ "Version" SG_ 323 FHPTC_PassFltOverCurrent "23.08.08";
BA_ "UserSigValidity" SG_ 323 FHPTC_PassFltThermalShutDn 7;
BA_ "Version" SG_ 323 FHPTC_PassFltThermalShutDn "23.08.08";
BA_ "UserSigValidity" SG_ 323 FHPTC_PassFltPcbThermalShutDn 7;
BA_ "Version" SG_ 323 FHPTC_PassFltPcbThermalShutDn "23.08.08";
BA_ "UserSigValidity" SG_ 323 FHPTC_PassFltMsgTmOutATCU 7;
BA_ "Version" SG_ 323 FHPTC_PassFltMsgTmOutATCU "23.08.08";
BA_ "UserSigValidity" SG_ 323 FHPTC_PassFailHVSnr 7;
BA_ "Version" SG_ 323 FHPTC_PassFailHVSnr "23.08.08";
BA_ "UserSigValidity" SG_ 320 FHPTC_DrRdySta 7;
BA_ "Version" SG_ 320 FHPTC_DrRdySta "23.08.08";
BA_ "UserSigValidity" SG_ 320 FHPTC_DrOpSta 7;
BA_ "Version" SG_ 320 FHPTC_DrOpSta "23.08.08";
BA_ "UserSigValidity" SG_ 320 FHPTC_DrCnsmptPwr_W 7;
BA_ "Version" SG_ 320 FHPTC_DrCnsmptPwr_W "23.08.08";
BA_ "UserSigValidity" SG_ 320 FHPTC_DrCurrent_A 7;
BA_ "Version" SG_ 320 FHPTC_DrCurrent_A "23.08.08";
BA_ "UserSigValidity" SG_ 320 FHPTC_DrCoreTemp_C 7;
BA_ "Version" SG_ 320 FHPTC_DrCoreTemp_C "23.08.08";
BA_ "Description" SG_ 320 FHPTC_DrDutyFB_Pec "Duty Conversion to PTC Consumption power value, 40w~6kw -> 10%~95%";
BA_ "UserSigValidity" SG_ 320 FHPTC_DrDutyFB_Pec 7;
BA_ "Version" SG_ 320 FHPTC_DrDutyFB_Pec "23.08.08";
BA_ "Description" SG_ 320 FHPTC_DrDutyFB_IGBT "PWM DUTY of PTC IGBT (0~100%)";
BA_ "UserSigValidity" SG_ 320 FHPTC_DrDutyFB_IGBT 7;
BA_ "Version" SG_ 320 FHPTC_DrDutyFB_IGBT "23.08.08";
BA_ "UserSigValidity" SG_ 320 FHPTC_DrCtrlTyp 7;
BA_ "Version" SG_ 320 FHPTC_DrCtrlTyp "23.08.08";
BA_ "UserSigValidity" SG_ 320 FHPTC_DrVoltage_V 7;
BA_ "Version" SG_ 320 FHPTC_DrVoltage_V "23.08.08";
BA_ "UserSigValidity" SG_ 321 FHPTC_DrFlt 7;
BA_ "Version" SG_ 321 FHPTC_DrFlt "23.08.08";
BA_ "UserSigValidity" SG_ 321 FHPTC_DrFltLVLow 7;
BA_ "Version" SG_ 321 FHPTC_DrFltLVLow "23.08.08";
BA_ "UserSigValidity" SG_ 321 FHPTC_DrFailLVSnr 7;
BA_ "Version" SG_ 321 FHPTC_DrFailLVSnr "23.08.08";
BA_ "UserSigValidity" SG_ 321 FHPTC_DrFailCurrentSnr 7;
BA_ "Version" SG_ 321 FHPTC_DrFailCurrentSnr "23.08.08";
BA_ "UserSigValidity" SG_ 321 FHPTC_DrFailCoreTempSnr 7;
BA_ "Version" SG_ 321 FHPTC_DrFailCoreTempSnr "23.08.08";
BA_ "UserSigValidity" SG_ 321 FHPTC_DrFailPcbTempSnr 7;
BA_ "Version" SG_ 321 FHPTC_DrFailPcbTempSnr "23.08.08";
BA_ "UserSigValidity" SG_ 321 FHPTC_DrFailIGBT 7;
BA_ "Version" SG_ 321 FHPTC_DrFailIGBT "23.08.08";
BA_ "UserSigValidity" SG_ 321 FHPTC_DrFailOpenLoad 7;
BA_ "Version" SG_ 321 FHPTC_DrFailOpenLoad "23.08.08";
BA_ "UserSigValidity" SG_ 321 FHPTC_DrLtdOpCause 7;
BA_ "Version" SG_ 321 FHPTC_DrLtdOpCause "23.08.08";
BA_ "UserSigValidity" SG_ 321 FHPTC_DrFltLVHigh 7;
BA_ "Version" SG_ 321 FHPTC_DrFltLVHigh "23.08.08";
BA_ "UserSigValidity" SG_ 321 FHPTC_DrSwVer 7;
BA_ "Version" SG_ 321 FHPTC_DrSwVer "23.08.08";
BA_ "UserSigValidity" SG_ 321 FHPTC_DrFltHVLow 7;
BA_ "Version" SG_ 321 FHPTC_DrFltHVLow "23.08.08";
BA_ "Description" SG_ 321 FHPTC_CnsmptPwrTtl_W "Total Power Consumption Value = FHPTC_DrConsumptionPower_W + FHPTC_PassConsumptionPower_W";
BA_ "UserSigValidity" SG_ 321 FHPTC_CnsmptPwrTtl_W 7;
BA_ "Version" SG_ 321 FHPTC_CnsmptPwrTtl_W "23.08.08";
BA_ "UserSigValidity" SG_ 321 FHPTC_DrFltHVHigh 7;
BA_ "Version" SG_ 321 FHPTC_DrFltHVHigh "23.08.08";
BA_ "UserSigValidity" SG_ 321 FHPTC_IntlkSta 7;
BA_ "Version" SG_ 321 FHPTC_IntlkSta "23.08.08";
BA_ "UserSigValidity" SG_ 321 FHPTC_DrFltOverCurrent 7;
BA_ "Version" SG_ 321 FHPTC_DrFltOverCurrent "23.08.08";
BA_ "UserSigValidity" SG_ 321 FHPTC_DrFltThermalShutDn 7;
BA_ "Version" SG_ 321 FHPTC_DrFltThermalShutDn "23.08.08";
BA_ "UserSigValidity" SG_ 321 FHPTC_DrFltPcbThermalShutDn 7;
BA_ "Version" SG_ 321 FHPTC_DrFltPcbThermalShutDn "23.08.08";
BA_ "UserSigValidity" SG_ 321 FHPTC_DrFltMsgTmOutATCU 7;
BA_ "Version" SG_ 321 FHPTC_DrFltMsgTmOutATCU "23.08.08";
BA_ "UserSigValidity" SG_ 321 FHPTC_DrFailHVSnr 7;
BA_ "Version" SG_ 321 FHPTC_DrFailHVSnr "23.08.08";
VAL_ 3221225472 L_2HKBD_RrDrModeBiLvlSw 0 "Off" 1 "On" ;
VAL_ 3221225472 L_2HKBD_RrDrTempDnSw 0 "Off" 1 "On" ;
VAL_ 3221225472 L_2HKBD_RrDrTempUpSw 0 "Off" 1 "On" ;
VAL_ 3221225472 L_2HKBD_RrDrBlwDnSw 0 "Off" 1 "On" ;
VAL_ 3221225472 L_2HKBD_RrDrBlwUpSw 0 "Off" 1 "On" ;
VAL_ 3221225472 L_2HKBD_RrFlrDuctSnsr 0 "0x0x0~0xFA:0~5V" 250 "0x0x0~0xFA:0~5V" 255 "Error Indicator" ;
VAL_ 3221225472 L_2HKBD_RrVntDuctSnsr 0 "0x0x0~0xFA:0~5V" 250 "0x0x0~0xFA:0~5V" 255 "Error Indicator" ;
VAL_ 3221225472 L_ATCU_Typ1 0 "Defualt" 1 "Domestic" 2 "General or MiddleEast or Australia" 3 "Europe or Russia" 4 "America" 5 "Canada" 6 "China" 7 "India" 8 "Invalid" 9 "Invalid" 10 "Invalid" 11 "Invalid" 12 "Invalid" 13 "Invalid" 14 "Invalid" 15 "Invalid" ;
VAL_ 3221225472 L_ATCU_Drv_SeatOptSta 0 "Init" 1 "Heater only 2step" 2 "Heater only 3step" 3 "Vent only 2step" 4 "Vent only 3step" 5 "Heater and Vent 2step" 6 "Heater and Vent 3step" 7 "Invalid" ;
VAL_ 3221225472 L_ATCU_Ast_SeatOptSta 0 "Init" 1 "Heater only 2step" 2 "Heater only 3step" 3 "Vent only 2step" 4 "Vent only 3step" 5 "Heater and Vent 2step" 6 "Heater and Vent 3step" 7 "Invalid" ;
VAL_ 3221225472 L_ATCU_RL_SeatOptSta 0 "Init" 1 "Heater only 2step" 2 "Heater only 3step" 3 "Vent only 2step" 4 "Vent only 3step" 5 "Heater and Vent 2step" 6 "Heater and Vent 3step" 7 "Invalid" ;
VAL_ 3221225472 L_ATCU_RR_SeatOptSta 0 "Init" 1 "Heater only 2step" 2 "Heater only 3step" 3 "Vent only 2step" 4 "Vent only 3step" 5 "Heater and Vent 2step" 6 "Heater and Vent 3step" 7 "Invalid" ;
VAL_ 3221225472 L_2HKBD_Rr_EvapVolVal 0 "0x0x0~0xFA:0~5V" 250 "0x0x0~0xFA:0~5V" 255 "Error Indicator" ;
VAL_ 3221225472 L_2HKBD_Rr_TempActrSt 0 "Normal" 1 "Open" 2 "Short" 3 "Stuck" ;
VAL_ 3221225472 L_2HKBD_Rr_TempAsstActrFB 1023 "Error Indicator" ;
VAL_ 3221225472 L_2HKBD_Rr_TempAsstActrSt 0 "Normal" 1 "Open" 2 "Short" 3 "Stuck" ;
VAL_ 3221225472 L_2HKBD_Rr_ModeActrFB 1023 "Error Indicator" ;
VAL_ 3221225472 L_2HKBD_Rr_ModeActrSt 0 "Normal" 1 "Open" 2 "Short" 3 "Stuck" ;
VAL_ 3221225472 L_2HKBD_Rr_BLDCError 0 "No error" 1 "Over Current" 2 "Under Voltage" 3 "Over Voltage" 4 "Stall" 5 "Over Temperature" 6 "Controller Shutdown (Internal Error)" 7 "Current Limit" 8 "Limp mode" 9 "LIN Fail" 10 "RESERVED" 11 "RESERVED" 12 "RESERVED" 13 "RESERVED" 14 "RESERVED" 15 "RESERVED" ;
VAL_ 3221225472 L_2HKBD_Rr_TempActrFB 1023 "Error Indicator" ;
VAL_ 3221225472 L_ATCU_3rdRrTempCDis 0 "Blank Display (Default)" 1 "'LO' Display" 2 "15.0¡É~32.0¡É" 3 "15.0¡É~32.0¡É" 4 "15.0¡É~32.0¡É" 5 "15.0¡É~32.0¡É" 6 "15.0¡É~32.0¡É" 7 "15.0¡É~32.0¡É" 8 "15.0¡É~32.0¡É" 9 "15.0¡É~32.0¡É" 10 "15.0¡É~32.0¡É" 11 "15.0¡É~32.0¡É" 12 "15.0¡É~32.0¡É" 13 "15.0¡É~32.0¡É" 14 "15.0¡É~32.0¡É" 15 "15.0¡É~32.0¡É" 16 "15.0¡É~32.0¡É" 17 "15.0¡É~32.0¡É" 18 "15.0¡É~32.0¡É" 19 "15.0¡É~32.0¡É" 20 "15.0¡É~32.0¡É" 21 "15.0¡É~32.0¡É" 22 "15.0¡É~32.0¡É" 23 "15.0¡É~32.0¡É" 24 "15.0¡É~32.0¡É" 25 "15.0¡É~32.0¡É" 26 "15.0¡É~32.0¡É" 27 "15.0¡É~32.0¡É" 28 "15.0¡É~32.0¡É" 29 "15.0¡É~32.0¡É" 30 "15.0¡É~32.0¡É" 31 "15.0¡É~32.0¡É" 32 "15.0¡É~32.0¡É" 33 "15.0¡É~32.0¡É" 34 "15.0¡É~32.0¡É" 35 "15.0¡É~32.0¡É" 36 "15.0¡É~32.0¡É" 37 "0x25~0xFD:RESERVED" 253 "0x25~0xFD:RESERVED" 254 "'HI' Display" 255 "Error Indicator" ;
VAL_ 3221225472 L_ATCU_3rdRrModDis 0 "Off(Blank Display, Vent mode not Display ex) Auto" 1 "VENT" 2 "B_L" 3 "FLOOR" 4 "MIX" 5 "DEF(Including Max DEF)" 6 "AUTO DEFOG" 7 "Def (7 mode only)" 8 "DefVent(7 mode only)" 9 "DefFL(7 mode only)" 10 "VentFL(7 mode only)" 11 "DefVentFL(7 mode only)" 12 "Not used" 13 "Not used" 14 "Not used" 15 "Error Indicator" ;
VAL_ 3221225472 L_ATCU_3rdRrBlwDis 0 "OFF(System Off)" 1 "Blank Display(Blower Level no display, ex)Auto mode)" 2 "1 Level" 3 "2 Level" 4 "3 Level" 5 "4 Level" 6 "5 Level" 7 "6 Level" 8 "7 Level" 9 "8 Level" 10 "Not used" 11 "Not used" 12 "Not used" 13 "Not used" 14 "Not used" 15 "Error Indicator" ;
VAL_ 3221225472 L_ATCU_3rdRrAutoDis 0 "3rdRrAUTO Off" 1 "3rdRrAUTO On" 2 "Not used" 3 "Error Indicator" ;
VAL_ 3221225472 L_ATCU_3rdRrMultiAutoBlwDis 0 "MultiAutoBlr Display Off" 1 "Multi Auto Blower Low" 2 "Multi Auto Blower Mid" 3 "Multi Auto Blower High" 4 "RESERVED" 5 "RESERVED" 6 "RESERVED" 7 "Error Indicator" ;
VAL_ 3221225472 L_ATCU_3rdRrSyncDis 0 "RearAc Off" 1 "RearAc On" 2 "Not Used" 3 "Error Indicator" ;
VAL_ 3221225472 L_ATCU_3rdRrOnInd 0 "Off" 1 "On" 2 "RESERVED" ;
VAL_ 3221225472 L_ATCU_3rdRrLockDis 0 "RearLock Off" 1 "RearLock On" 2 "Not Used" 3 "Error Indicator" ;
VAL_ 3221225472 L_ATCU_3rdRrLcdBckLightSta 0 "OFF" 1 "ON" ;
VAL_ 3221225472 L_ATCU_3rdRrGUIBlankDis 0 "OFF" 1 "ON" ;
VAL_ 3221225472 L_ATCU_3rdRLStHeatSwHInd 0 "OFF" 1 "ON" ;
VAL_ 3221225472 L_ATCU_3rdRLStHeatSwMInd 0 "OFF" 1 "ON" ;
VAL_ 3221225472 L_ATCU_3rdRLStHeatSwLInd 0 "OFF" 1 "ON" ;
VAL_ 3221225472 L_ATCU_3rdRLStVntSwHInd 0 "OFF" 1 "ON" ;
VAL_ 3221225472 L_ATCU_3rdRLStVntSwMInd 0 "OFF" 1 "ON" ;
VAL_ 3221225472 L_ATCU_3rdRLStVntSwLInd 0 "OFF" 1 "ON" ;
VAL_ 3221225472 L_ATCU_3rdRRStHeatSwHInd 0 "OFF" 1 "ON" ;
VAL_ 3221225472 L_ATCU_3rdRRStHeatSwMInd 0 "OFF" 1 "ON" ;
VAL_ 3221225472 L_ATCU_3rdRRStHeatSwLInd 0 "OFF" 1 "ON" ;
VAL_ 3221225472 L_ATCU_3rdRRStVntSwHInd 0 "OFF" 1 "ON" ;
VAL_ 3221225472 L_ATCU_3rdRRStVntSwMInd 0 "OFF" 1 "ON" ;
VAL_ 3221225472 L_ATCU_3rdRRStVntSwLInd 0 "OFF" 1 "ON" ;
VAL_ 3221225472 L_ATCU_3rdRrMTCOpSta 0 "DATC Off (Power Down)" 1 "DATC Normal" 2 "DATC System Off (Blower Off)" 3 "Error Indicator" ;
VAL_ 3221225472 L_ATCU_3rdRrMtcTempLvl 0 "Off" 1 "Level 1" 2 "Level 2" 3 "Level 3" 4 "Level 4" 5 "Level 5" 6 "Level 6" 7 "Level 7" 8 "Level 8" ;
VAL_ 3221225472 L_ATCU_3rdAUTOStep 0 "Default" 1 "OFF" 2 "1st & 2nd & 3rd On (3 Step Type)" 3 "1st & 2nd On (3 Step Type)" 4 "1st On (3 Step Type)" 5 "1st & 2nd On (2 Step Type)" 6 "1st On (2 Step Type)" 7 "Error Indicator" ;
VAL_ 3221225472 L_ATCU_RrPassMultiAutoBlwDis 0 "MultiAutoBlr Display Off" 1 "Multi Auto Blower Low" 2 "Multi Auto Blower Mid" 3 "Multi Auto Blower High" 4 "RESERVED" 5 "RESERVED" 6 "RESERVED" 7 "Error Indicator" ;
VAL_ 3221225472 L_ATCU_3rdRrTempFDis 0 "Blank Display(Default)" 1 "'LO' Display" 2 "58¢µ~92¢µ" 3 "58¢µ~92¢µ" 4 "58¢µ~92¢µ" 5 "58¢µ~92¢µ" 6 "58¢µ~92¢µ" 7 "58¢µ~92¢µ" 8 "58¢µ~92¢µ" 9 "58¢µ~92¢µ" 10 "58¢µ~92¢µ" 11 "58¢µ~92¢µ" 12 "58¢µ~92¢µ" 13 "58¢µ~92¢µ" 14 "58¢µ~92¢µ" 15 "58¢µ~92¢µ" 16 "58¢µ~92¢µ" 17 "58¢µ~92¢µ" 18 "58¢µ~92¢µ" 19 "58¢µ~92¢µ" 20 "58¢µ~92¢µ" 21 "58¢µ~92¢µ" 22 "58¢µ~92¢µ" 23 "58¢µ~92¢µ" 24 "58¢µ~92¢µ" 25 "58¢µ~92¢µ" 26 "58¢µ~92¢µ" 27 "58¢µ~92¢µ" 28 "58¢µ~92¢µ" 29 "58¢µ~92¢µ" 30 "58¢µ~92¢µ" 31 "58¢µ~92¢µ" 32 "58¢µ~92¢µ" 33 "58¢µ~92¢µ" 34 "58¢µ~92¢µ" 35 "58¢µ~92¢µ" 36 "58¢µ~92¢µ" 37 "0x25~0xFD:RESERVED" 253 "0x25~0xFD:RESERVED" 254 "'HI' Display" 255 "Error Indicator" ;
VAL_ 3221225472 L_ATCU_RrHVACTempActrTgt 0 "0x0x0~0x3FF:AD = Factor*Hex + Offset" 1023 "0x0x0~0x3FF:AD = Factor*Hex + Offset" ;
VAL_ 3221225472 L_ATCU_RrHVACTempAsstActrTgt 0 "0x0x0~0x3FF:AD = Factor*Hex + Offset" 1023 "0x0x0~0x3FF:AD = Factor*Hex + Offset" ;
VAL_ 3221225472 L_ATCU_RrHVACModeActrTgt 0 "0x0x0~0x3FF:AD = Factor*Hex + Offset" 1023 "0x0x0~0x3FF:AD = Factor*Hex + Offset" ;
VAL_ 3221225472 L_ATCU_RrHVACBlowerTgtV 0 "0x0x0~0xFF:V = Factor*Hex + Offset" 255 "0x0x0~0xFF:V = Factor*Hex + Offset" ;
VAL_ 3221225472 L_ATCU_RrHVACDiagBlwOn 0 "OFF" 1 "ON" ;
VAL_ 3221225472 L_ATCU_RrHVACTempActrOpSta 0 "Stop" 1 "Operating" ;
VAL_ 3221225472 L_ATCU_RrHVACTempAsstActrOpSta 0 "Stop" 1 "Operating" ;
VAL_ 3221225472 L_ATCU_RrHVACModActrOpSta 0 "Stop" 1 "Operating" ;
VAL_ 3221225472 L_ATCU_ArClnIntroEvt 0 "OFF" 1 "ON" ;
VAL_ 3221225472 L_ATCU_ArClnSmblClr 0 "Default (Initial Value)" 1 "Mono Color" 2 "Blue Color" 3 "Green Color" 4 "Orange Color" 5 "Red Color" 6 "Yellow Color" 7 "RESERVED" 8 "RESERVED" 9 "RESERVED" 10 "RESERVED" 11 "RESERVED" 12 "RESERVED" 13 "RESERVED" 14 "Gray Color (Deactivate)" 15 "Invalid" ;
VAL_ 3221225472 L_ATCU_DustLevelDis 0 "Sensor Fail" 1 "Good" 2 "Normal" 3 "Bad" 4 "Very Bad" 5 "RESERVED" 6 "Loading(Init or StandBy)" 7 "Error Indicator" ;
VAL_ 3221225472 L_ATCU_DustBarDisOff 0 "False(Symbol ON)" 1 "True(Symbol OFF)" ;
VAL_ 3221225472 L_ATCU_DustSnrStepDis 0 "default" 1 "0step" 2 "1step" 3 "2step" 4 "3step" 5 "4step" 6 "5step" 7 "6step" 8 "7step" 9 "8step" 10 "9step" 11 "10step" 12 "11step" 13 "12step" 14 "13step" 15 "14step" 16 "15step" 17 "16step" ;
VAL_ 3221225472 L_ATCU_FragStrhDis 0 "OFF" 1 "1st(Low)" 2 "1st&2nd(Mid)" 3 "1st&2nd&3rd(High)" ;
VAL_ 3221225472 L_ATCU_FragKindDis 0 "Default" 1 "First" 2 "Second" 3 "RESERVED" 4 "RESERVED" 5 "RESERVED" 6 "RESERVED" 7 "Invalid" ;
VAL_ 3221225472 L_ATCU_Frag1Inform 0 "Default" 1 "THE DRIVER'S AWAKENING" 2 "MY FAVORITE PLACE" 3 "THE GREAT OUTDOORS" 4 "RESERVED" 5 "RESERVED" 6 "RESERVED" 7 "RESERVED" 8 "RESERVED" 9 "RESERVED" 10 "RESERVED" 11 "RESERVED" 12 "New Fragrance Mounted" 13 "No Cartridge Mounted" 14 "Unknown Cartridge Monuted" 15 "Error Indicator" ;
VAL_ 3221225472 L_ATCU_Frag2Inform 0 "Default" 1 "THE DRIVER'S AWAKENING" 2 "MY FAVORITE PLACE" 3 "THE GREAT OUTDOORS" 4 "RESERVED" 5 "RESERVED" 6 "RESERVED" 7 "RESERVED" 8 "RESERVED" 9 "RESERVED" 10 "RESERVED" 11 "RESERVED" 12 "New Fragrance Mounted" 13 "No Cartridge Mounted" 14 "Unknown Cartridge Monuted" 15 "Error Indicator" ;
VAL_ 3221225472 L_ATCU_Frag1RemainDisp 0 "Default" 1 "Remains 100% (70~100%)" 2 "Remains 70% (30~70%)" 3 "Remains 30% (0~30%)" 4 "Remains 0%" 5 "RESERVED" 6 "Unknown" 7 "Error Indicator" ;
VAL_ 3221225472 L_ATCU_Frag2RemainDisp 0 "Default" 1 "Remains 100% (70~100%)" 2 "Remains 70% (30~70%)" 3 "Remains 30% (0~30%)" 4 "Remains 0%" 5 "RESERVED" 6 "Unknown" 7 "Error Indicator" ;
VAL_ 3221225472 L_ATCU_ArClnSmblTyp 0 "Default" 1 "BLANK DISPLAY" 2 "Tree Only" 3 "Tree & Fixed Arrow" 4 "Tree & Rotating Arrow" ;
VAL_ 3221225472 L_ATCU_FrtBlwMaxLvlVaild 0 "Invalid (Multi AUTO Not Applied)" 1 "Reversed" 2 "1 Level" 3 "2 Level" 4 "3 Level" 5 "4 Level" 6 "5 Level" 7 "6 Level" 8 "7 Level" 9 "8 Level" 10 "Not used" 11 "Not used" 12 "Not used" 13 "Not used" 14 "Not used" 15 "Error Indicator" ;
VAL_ 3221225472 L_ATCU_OpSta 0 "DATC Off (Power Down)" 1 "DATC Normal" 2 "DATC System Off (Blower Off)" 3 "DATC Self Diagnosis" 4 "Version Display" 5 "Not used" 6 "Not used" 7 "Error Indicator" ;
VAL_ 3221225472 L_ATCU_TempDispUnit 0 "Centigrade(¡É)" 1 "Fahrenheit(¢µ)" 2 "Not used" 3 "Error Indicator" ;
VAL_ 3221225472 L_ATCU_DrvAUTOStep 0 "Default" 1 "OFF" 2 "1st & 2nd & 3rd On (3 Step Type)" 3 "1st & 2nd On (3 Step Type)" 4 "1st On (3 Step Type)" 5 "1st & 2nd On (2 Step Type)" 6 "1st On (2 Step Type)" 7 "RESERVED" 8 "RESERVED" 9 "RESERVED" 10 "RESERVED" 11 "RESERVED" 12 "RESERVED" 13 "RESERVED" 14 "RESERVED" 15 "Error Indicator" ;
VAL_ 3221225472 L_ATCU_DiagCodeDis 0 "Blank Display" 1023 "Error Indicator" ;
VAL_ 3221225472 L_ATCU_RrOpSta 0 "DATC Off (Power Down)" 1 "DATC Normal" 2 "DATC System Off (Blower Off)" 3 "DATC Self Diagnosis" 4 "Not used" 5 "Not used" 6 "Not used" 7 "Error Indicator" ;
VAL_ 3221225472 L_ATCU_RrDrvTempFDis 0 "Blank Display (Default)" 1 "'LO' Display" 2 "58¢µ~92¢µ" 3 "58¢µ~92¢µ" 4 "58¢µ~92¢µ" 5 "58¢µ~92¢µ" 6 "58¢µ~92¢µ" 7 "58¢µ~92¢µ" 8 "58¢µ~92¢µ" 9 "58¢µ~92¢µ" 10 "58¢µ~92¢µ" 11 "58¢µ~92¢µ" 12 "58¢µ~92¢µ" 13 "58¢µ~92¢µ" 14 "58¢µ~92¢µ" 15 "58¢µ~92¢µ" 16 "58¢µ~92¢µ" 17 "58¢µ~92¢µ" 18 "58¢µ~92¢µ" 19 "58¢µ~92¢µ" 20 "58¢µ~92¢µ" 21 "58¢µ~92¢µ" 22 "58¢µ~92¢µ" 23 "58¢µ~92¢µ" 24 "58¢µ~92¢µ" 25 "58¢µ~92¢µ" 26 "58¢µ~92¢µ" 27 "58¢µ~92¢µ" 28 "58¢µ~92¢µ" 29 "58¢µ~92¢µ" 30 "58¢µ~92¢µ" 31 "58¢µ~92¢µ" 32 "58¢µ~92¢µ" 33 "58¢µ~92¢µ" 34 "58¢µ~92¢µ" 35 "58¢µ~92¢µ" 36 "58¢µ~92¢µ" 37 "0x25~0xFD:RESERVED" 253 "0x25~0xFD:RESERVED" 254 "'HI' Display" 255 "Error Indicator" ;
VAL_ 3221225472 L_ATCU_RrDrvModDis 0 "Off(Blank Display, Vent mode not Display ex) Auto" 1 "VENT" 2 "B_L" 3 "FLOOR" 4 "MIX" 5 "DEF(Including Max DEF)" 6 "AUTO DEFOG" 7 "Def (7 mode only)" 8 "DefVent(7 mode only)" 9 "DefFL(7 mode only)" 10 "VentFL(7 mode only)" 11 "DefVentFL(7 mode only)" 12 "Not used" 13 "Not used" 14 "Not used" 15 "Error Indicator" ;
VAL_ 3221225472 L_ATCU_RrDrvBlwDis 0 "OFF(System Off)" 1 "Blank Display(Blower Level no display, ex)Auto mode)" 2 "1 Level" 3 "2 Level" 4 "3 Level" 5 "4 Level" 6 "5 Level" 7 "6 Level" 8 "7 Level" 9 "8 Level" 10 "Not used" 11 "Not used" 12 "Not used" 13 "Not used" 14 "Not used" 15 "Error Indicator" ;
VAL_ 3221225472 L_ATCU_RrDrvAutoDis 0 "RrAUTO Off" 1 "RrAUTO On" 2 "Not used" 3 "Error Indicator" ;
VAL_ 3221225472 L_ATCU_RrDrvMultiAutoBlwDis 0 "MultiAutoBlr Display Off" 1 "Multi Auto Blower Low" 2 "Multi Auto Blower Mid" 3 "Multi Auto Blower High" ;
VAL_ 3221225472 L_ATCU_RrDrvTempCDis 0 "Blank Display (Default)" 1 "'LO' Display" 2 "15.0¡É~32.0¡É" 3 "15.0¡É~32.0¡É" 4 "15.0¡É~32.0¡É" 5 "15.0¡É~32.0¡É" 6 "15.0¡É~32.0¡É" 7 "15.0¡É~32.0¡É" 8 "15.0¡É~32.0¡É" 9 "15.0¡É~32.0¡É" 10 "15.0¡É~32.0¡É" 11 "15.0¡É~32.0¡É" 12 "15.0¡É~32.0¡É" 13 "15.0¡É~32.0¡É" 14 "15.0¡É~32.0¡É" 15 "15.0¡É~32.0¡É" 16 "15.0¡É~32.0¡É" 17 "15.0¡É~32.0¡É" 18 "15.0¡É~32.0¡É" 19 "15.0¡É~32.0¡É" 20 "15.0¡É~32.0¡É" 21 "15.0¡É~32.0¡É" 22 "15.0¡É~32.0¡É" 23 "15.0¡É~32.0¡É" 24 "15.0¡É~32.0¡É" 25 "15.0¡É~32.0¡É" 26 "15.0¡É~32.0¡É" 27 "15.0¡É~32.0¡É" 28 "15.0¡É~32.0¡É" 29 "15.0¡É~32.0¡É" 30 "15.0¡É~32.0¡É" 31 "15.0¡É~32.0¡É" 32 "15.0¡É~32.0¡É" 33 "15.0¡É~32.0¡É" 34 "15.0¡É~32.0¡É" 35 "15.0¡É~32.0¡É" 36 "15.0¡É~32.0¡É" 37 "0x25~0xFD:RESERVED" 253 "0x25~0xFD:RESERVED" 254 "'HI' Display" 255 "Error Indicator" ;
VAL_ 3221225472 L_ATCU_RrSyncDis 0 "RrSYNC Off" 1 "RrSYNC On" 2 "Not used" 3 "Error Indicator" ;
VAL_ 3221225472 L_ATCU_RrLcdBckLightSta 0 "OFF" 1 "ON" ;
VAL_ 3221225472 L_ATCU_RrGUIBlankDis 0 "OFF" 1 "ON" ;
VAL_ 3221225472 L_ATCU_RLStHeatSwHInd 0 "OFF" 1 "ON" ;
VAL_ 3221225472 L_ATCU_RLStHeatSwMInd 0 "OFF" 1 "ON" ;
VAL_ 3221225472 L_ATCU_RLStHeatSwLInd 0 "OFF" 1 "ON" ;
VAL_ 3221225472 L_ATCU_RLStVntSwHInd 0 "OFF" 1 "ON" ;
VAL_ 3221225472 L_ATCU_RLStVntSwMInd 0 "OFF" 1 "ON" ;
VAL_ 3221225472 L_ATCU_RLStVntSwLInd 0 "OFF" 1 "ON" ;
VAL_ 3221225472 L_ATCU_RRStHeatSwHInd 0 "OFF" 1 "ON" ;
VAL_ 3221225472 L_ATCU_RRStHeatSwMInd 0 "OFF" 1 "ON" ;
VAL_ 3221225472 L_ATCU_RRStHeatSwLInd 0 "OFF" 1 "ON" ;
VAL_ 3221225472 L_ATCU_RRStVntSwHInd 0 "OFF" 1 "ON" ;
VAL_ 3221225472 L_ATCU_RRStVntSwMInd 0 "OFF" 1 "ON" ;
VAL_ 3221225472 L_ATCU_RRStVntSwLInd 0 "OFF" 1 "ON" ;
VAL_ 3221225472 L_ATCU_RrMTCOpSta 0 "DATC Off (Power Down)" 1 "DATC Normal" 2 "DATC System Off (Blower Off)" 3 "Error Indicator" ;
VAL_ 3221225472 L_ATCU_RrMTCTempLvl 0 "Off" 1 "Level 1" 2 "Level 2" 3 "Level 3" 4 "Level 4" 5 "Level 5" 6 "Level 6" 7 "Level 7" 8 "Level 8" ;
VAL_ 3221225472 L_ATCU_RrPsModDis 0 "Off(Blank Display, Vent mode not Display ex) Auto" 1 "VENT" 2 "B_L" 3 "FLOOR" 4 "MIX" 5 "DEF(Including Max DEF)" 6 "AUTO DEFOG" 7 "Def (7 mode only)" 8 "DefVent(7 mode only)" 9 "DefFL(7 mode only)" 10 "VentFL(7 mode only)" 11 "DefVentFL(7 mode only)" 12 "Not used" 13 "Not used" 14 "Not used" 15 "Error Indicator" ;
VAL_ 3221225472 L_ATCU_RrLockDis 0 "RearLock Off" 1 "RearLock On" 2 "Not Used" 3 "Error Indicator" ;
VAL_ 3221225472 L_ATCU_RrDrvAutoStep 0 "Default" 1 "OFF" 2 "1st & 2nd & 3rd On (3 Step Type)" 3 "1st & 2nd On (3 Step Type)" 4 "1st On (3 Step Type)" 5 "1st & 2nd On (2 Step Type)" 6 "1st On (2 Step Type)" 7 "RESERVED" 8 "RESERVED" 9 "RESERVED" 10 "RESERVED" 11 "RESERVED" 12 "RESERVED" 13 "RESERVED" 14 "RESERVED" 15 "Error Indicator" ;
VAL_ 3221225472 L_ATCU_PassAUTOStep 0 "Default" 1 "OFF" 2 "1st & 2nd & 3rd On (3 Step Type)" 3 "1st & 2nd On (3 Step Type)" 4 "1st On (3 Step Type)" 5 "1st & 2nd On (2 Step Type)" 6 "1st On (2 Step Type)" 7 "Error Indicator" ;
VAL_ 3221225472 L_ATCU_RrPassTempFDis 0 "Blank Display(Default)" 1 "'LO' Display" 2 "58¢µ~32¢µ" 3 "58¢µ~32¢µ" 4 "58¢µ~32¢µ" 5 "58¢µ~32¢µ" 6 "58¢µ~32¢µ" 7 "58¢µ~32¢µ" 8 "58¢µ~32¢µ" 9 "58¢µ~32¢µ" 10 "58¢µ~32¢µ" 11 "58¢µ~32¢µ" 12 "58¢µ~32¢µ" 13 "58¢µ~32¢µ" 14 "58¢µ~32¢µ" 15 "58¢µ~32¢µ" 16 "58¢µ~32¢µ" 17 "58¢µ~32¢µ" 18 "58¢µ~32¢µ" 19 "58¢µ~32¢µ" 20 "58¢µ~32¢µ" 21 "58¢µ~32¢µ" 22 "58¢µ~32¢µ" 23 "58¢µ~32¢µ" 24 "58¢µ~32¢µ" 25 "58¢µ~32¢µ" 26 "58¢µ~32¢µ" 27 "58¢µ~32¢µ" 28 "58¢µ~32¢µ" 29 "58¢µ~32¢µ" 30 "58¢µ~32¢µ" 31 "58¢µ~32¢µ" 32 "58¢µ~32¢µ" 33 "58¢µ~32¢µ" 34 "58¢µ~32¢µ" 35 "58¢µ~32¢µ" 36 "58¢µ~32¢µ" 37 "0x25~0xFD:RESERVED" 253 "0x25~0xFD:RESERVED" 254 "'HI' Display" 255 "Error Indicator" ;
VAL_ 3221225472 L_ATCU_RrPassBlwDis 0 "OFF(Default)" 1 "Blank Display(Blower level not display, ex)Auto mode)" 2 "1 Step" 3 "2 Step" 4 "3 Step" 5 "4 Step" 6 "5 Step" 7 "6 Step" 8 "7 Step" 9 "8 Step" 10 "BLOWER AUTO" 11 "RESERVED" 12 "RESERVED" 13 "RESERVED" 14 "RESERVED" 15 "Error Indicator" ;
VAL_ 3221225472 L_ATCU_RrPassAUTODis 0 "PsAUTO Off" 1 "PsAUTO On" 2 "Not used" 3 "Error Indicator" ;
VAL_ 3221225472 L_ATCU_RrPassAUTOStep 0 "Default" 1 "OFF" 2 "1st & 2nd & 3rd On (3 Step Type)" 3 "1st & 2nd On (3 Step Type)" 4 "1st On (3 Step Type)" 5 "1st & 2nd On (2 Step Type)" 6 "1st On (2 Step Type)" 7 "Error Indicator" ;
VAL_ 3221225472 L_ATCU_CampModeSta 0 "Default" 1 "Off" 2 "On" 3 "Invalid" ;
VAL_ 3221225472 L_ATCU_RrPassTempCDis 0 "Blank Display(Default)" 1 "'LO' Display" 2 "15.0¡É~32.0¡É" 3 "15.0¡É~32.0¡É" 4 "15.0¡É~32.0¡É" 5 "15.0¡É~32.0¡É" 6 "15.0¡É~32.0¡É" 7 "15.0¡É~32.0¡É" 8 "15.0¡É~32.0¡É" 9 "15.0¡É~32.0¡É" 10 "15.0¡É~32.0¡É" 11 "15.0¡É~32.0¡É" 12 "15.0¡É~32.0¡É" 13 "15.0¡É~32.0¡É" 14 "15.0¡É~32.0¡É" 15 "15.0¡É~32.0¡É" 16 "15.0¡É~32.0¡É" 17 "15.0¡É~32.0¡É" 18 "15.0¡É~32.0¡É" 19 "15.0¡É~32.0¡É" 20 "15.0¡É~32.0¡É" 21 "15.0¡É~32.0¡É" 22 "15.0¡É~32.0¡É" 23 "15.0¡É~32.0¡É" 24 "15.0¡É~32.0¡É" 25 "15.0¡É~32.0¡É" 26 "15.0¡É~32.0¡É" 27 "15.0¡É~32.0¡É" 28 "15.0¡É~32.0¡É" 29 "15.0¡É~32.0¡É" 30 "15.0¡É~32.0¡É" 31 "15.0¡É~32.0¡É" 32 "15.0¡É~32.0¡É" 33 "15.0¡É~32.0¡É" 34 "15.0¡É~32.0¡É" 35 "15.0¡É~32.0¡É" 36 "15.0¡É~32.0¡É" 37 "0x25~0xFD:RESERVED" 253 "0x25~0xFD:RESERVED" 254 "'HI' Display" 255 "Error Indicator" ;
VAL_ 3221225472 L_ATCU_UtilModeUsmSta 0 "Disable" 1 "Rest Mode Off" 2 "Rest Mode On" 3 "Invalid" ;
VAL_ 3221225472 L_ATCU_OutTempDispC 0 "Default" 1 "Not Used" 2 "0x02~0xCA:-40¡É~60¡É" 202 "0x02~0xCA:-40¡É~60¡É" 203 "RESERVED" 204 "RESERVED" 205 "RESERVED" 206 "RESERVED" 207 "RESERVED" 208 "RESERVED" 209 "RESERVED" 210 "RESERVED" 211 "RESERVED" 212 "RESERVED" 213 "RESERVED" 214 "RESERVED" 215 "RESERVED" 216 "RESERVED" 217 "RESERVED" 218 "RESERVED" 219 "RESERVED" 220 "RESERVED" 221 "RESERVED" 222 "RESERVED" 223 "RESERVED" 224 "RESERVED" 225 "RESERVED" 226 "RESERVED" 227 "RESERVED" 228 "RESERVED" 229 "RESERVED" 230 "RESERVED" 231 "RESERVED" 232 "RESERVED" 233 "RESERVED" 234 "RESERVED" 235 "RESERVED" 236 "RESERVED" 237 "RESERVED" 238 "RESERVED" 239 "RESERVED" 240 "RESERVED" 241 "RESERVED" 242 "RESERVED" 243 "RESERVED" 244 "RESERVED" 245 "RESERVED" 246 "RESERVED" 247 "RESERVED" 248 "RESERVED" 249 "RESERVED" 250 "RESERVED" 251 "RESERVED" 252 "RESERVED" 253 "RESERVED" 254 "Sensor Fail (--Display)" 255 "Invalid" ;
VAL_ 3221225472 L_ATCU_DtntOutSta 0 "Detent Off" 1 "Detent On" ;
VAL_ 3221225472 L_ATCU_AutoBrightSta 0 "RESERVED" 1 "0x01~0xC8:Bright State (1~200 Step)" 200 "0x01~0xC8:Bright State (1~200 Step)" 201 "RESERVED" 202 "RESERVED" 203 "RESERVED" 204 "RESERVED" 205 "RESERVED" 206 "RESERVED" 207 "RESERVED" 208 "RESERVED" 209 "RESERVED" 210 "RESERVED" 211 "RESERVED" 212 "RESERVED" 213 "RESERVED" 214 "RESERVED" 215 "RESERVED" 216 "RESERVED" 217 "RESERVED" 218 "RESERVED" 219 "RESERVED" 220 "RESERVED" 221 "RESERVED" 222 "RESERVED" 223 "RESERVED" 224 "RESERVED" 225 "RESERVED" 226 "RESERVED" 227 "RESERVED" 228 "RESERVED" 229 "RESERVED" 230 "RESERVED" 231 "RESERVED" 232 "RESERVED" 233 "RESERVED" 234 "RESERVED" 235 "RESERVED" 236 "RESERVED" 237 "RESERVED" 238 "RESERVED" 239 "RESERVED" 240 "RESERVED" 241 "RESERVED" 242 "RESERVED" 243 "RESERVED" 244 "RESERVED" 245 "RESERVED" 246 "RESERVED" 247 "RESERVED" 248 "RESERVED" 249 "RESERVED" 250 "RESERVED" 251 "RESERVED" 252 "RESERVED" 253 "RESERVED" 254 "RESERVED" 255 "RESERVED" ;
VAL_ 3221225472 L_ATCU_DustSnrVal 1021 "Standby" 1022 "Init" 1023 "RESERVED" ;
VAL_ 3221225472 L_ATCU_NotMinModeBrightSta 0 "RESERVED (Not Used)" 1 "0x01~0xC8:Bright State(1~200 Step)" 200 "0x01~0xC8:Bright State(1~200 Step)" ;
VAL_ 3221225472 L_ATCU_OutTempDispF 0 "Default" 1 "Not Used" 2 "0x02~0xCA:-40¢µ~160¢µ" 202 "0x02~0xCA:-40¢µ~160¢µ" 203 "RESERVED" 204 "RESERVED" 205 "RESERVED" 206 "RESERVED" 207 "RESERVED" 208 "RESERVED" 209 "RESERVED" 210 "RESERVED" 211 "RESERVED" 212 "RESERVED" 213 "RESERVED" 214 "RESERVED" 215 "RESERVED" 216 "RESERVED" 217 "RESERVED" 218 "RESERVED" 219 "RESERVED" 220 "RESERVED" 221 "RESERVED" 222 "RESERVED" 223 "RESERVED" 224 "RESERVED" 225 "RESERVED" 226 "RESERVED" 227 "RESERVED" 228 "RESERVED" 229 "RESERVED" 230 "RESERVED" 231 "RESERVED" 232 "RESERVED" 233 "RESERVED" 234 "RESERVED" 235 "RESERVED" 236 "RESERVED" 237 "RESERVED" 238 "RESERVED" 239 "RESERVED" 240 "RESERVED" 241 "RESERVED" 242 "RESERVED" 243 "RESERVED" 244 "RESERVED" 245 "RESERVED" 246 "RESERVED" 247 "RESERVED" 248 "RESERVED" 249 "RESERVED" 250 "RESERVED" 251 "RESERVED" 252 "RESERVED" 253 "RESERVED" 254 "Sensor Fail (--Display)" 255 "Invalid" ;
VAL_ 3221225472 L_ATCU_SW_Ver1 0 "0x0x00~0x7E:ASCII value" 126 "0x0x00~0x7E:ASCII value" 127 "Invalid" ;
VAL_ 3221225472 L_ATCU_SW_Ver3 0 "0x0x00~0x7E:ASCII value" 126 "0x0x00~0x7E:ASCII value" 127 "Invalid" ;
VAL_ 3221225472 L_ATCU_SW_Ver4 0 "0x0x00~0x7E:ASCII value" 126 "0x0x00~0x7E:ASCII value" 127 "Invalid" ;
VAL_ 3221225472 L_ATCU_SW_Ver5 0 "0x0x00~0x7E:ASCII value" 126 "0x0x00~0x7E:ASCII value" 127 "Invalid" ;
VAL_ 3221225472 L_ATCU_SW_Ver2 0 "0x0x00~0x7E:ASCII value" 126 "0x0x00~0x7E:ASCII value" 127 "Invalid" ;
VAL_ 3221225472 L_ATCU_RHPTCOpPrmssnSta 0 "Operation is not allowed" 1 "Operation is allowed" ;
VAL_ 3221225472 L_ATCU_xEV_BMSRomTyp2 0 "No Definition" 1 "Normal Battery Pack with Heater System" 2 "Normal Battery Pack without Heater System" 3 "Economy Battery Pack with Heater System" 4 "Economy Battery Pack without Heater System" 5 "Extented Battery Pack with Heater System" 6 "Extented Battery Pack without Heater System" ;
VAL_ 3221225472 L_ATCU_RHPTCFlrTrgtDty 0 "0x0x0~0xC8:Duty" 200 "0x0x0~0xC8:Duty" 201 "RESERVED" 202 "RESERVED" 203 "RESERVED" 204 "RESERVED" 205 "RESERVED" 206 "RESERVED" 207 "RESERVED" 208 "RESERVED" 209 "RESERVED" 210 "RESERVED" 211 "RESERVED" 212 "RESERVED" 213 "RESERVED" 214 "RESERVED" 215 "RESERVED" 216 "RESERVED" 217 "RESERVED" 218 "RESERVED" 219 "RESERVED" 220 "RESERVED" 221 "RESERVED" 222 "RESERVED" 223 "RESERVED" 224 "RESERVED" 225 "RESERVED" 226 "RESERVED" 227 "RESERVED" 228 "RESERVED" 229 "RESERVED" 230 "RESERVED" 231 "RESERVED" 232 "RESERVED" 233 "RESERVED" 234 "RESERVED" 235 "RESERVED" 236 "RESERVED" 237 "RESERVED" 238 "RESERVED" 239 "RESERVED" 240 "RESERVED" 241 "RESERVED" 242 "RESERVED" 243 "RESERVED" 244 "RESERVED" 245 "RESERVED" 246 "RESERVED" 247 "RESERVED" 248 "RESERVED" 249 "RESERVED" 250 "RESERVED" 251 "RESERVED" 252 "RESERVED" 253 "RESERVED" 254 "RESERVED" 255 "ERROR" ;
VAL_ 3221225472 L_ATCU_RHPTCDischrgReq 0 "Non-Request" 1 "Request" ;
VAL_ 3221225472 L_ATCU_FltMsgTmOutRHPTC1 0 "Normal" 1 "Message Timeout" ;
VAL_ 3221225472 L_ATCU_FltMsgTmOutRHPTC2 0 "Normal" 1 "Message Timeout" ;
VAL_ 3221225472 L_ATCU_FltMsgTmOutRHPTC3 0 "Normal" 1 "Message Timeout" ;
VAL_ 3221225472 L_ATCU_FltMsgTmOutRHPTC4 0 "Normal" 1 "Message Timeout" ;
VAL_ 3221225472 L_ATCU_RrBlwLvl 0 "OFF" 1 "0 level" 2 "1 level" 3 "2 level" 4 "3 level" 5 "4 level" 6 "5 level" 7 "6 level" 8 "7 evel" 9 "8 level" 10 "RESERVED" 11 "RESERVED" 12 "RESERVED" 13 "RESERVED" 14 "RESERVED" 15 "Error Indicator" ;
VAL_ 3221225472 L_ATCU_RrBlwLvlSigVaildSta 0 "Invaild (Blower Level Info Not supported)" 1 "Vaild (Blower Level Info Supported) (Initial Value:0H)" ;
VAL_ 3221225472 L_ATCU_OutTempSnsrVal2 255 "Error" ;
VAL_ 3221225472 L_ATCU_RHPTCRoofTrgtDty 0 "0x0x0~0xC8:Duty" 200 "0x0x0~0xC8:Duty" 201 "RESERVED" 202 "RESERVED" 203 "RESERVED" 204 "RESERVED" 205 "RESERVED" 206 "RESERVED" 207 "RESERVED" 208 "RESERVED" 209 "RESERVED" 210 "RESERVED" 211 "RESERVED" 212 "RESERVED" 213 "RESERVED" 214 "RESERVED" 215 "RESERVED" 216 "RESERVED" 217 "RESERVED" 218 "RESERVED" 219 "RESERVED" 220 "RESERVED" 221 "RESERVED" 222 "RESERVED" 223 "RESERVED" 224 "RESERVED" 225 "RESERVED" 226 "RESERVED" 227 "RESERVED" 228 "RESERVED" 229 "RESERVED" 230 "RESERVED" 231 "RESERVED" 232 "RESERVED" 233 "RESERVED" 234 "RESERVED" 235 "RESERVED" 236 "RESERVED" 237 "RESERVED" 238 "RESERVED" 239 "RESERVED" 240 "RESERVED" 241 "RESERVED" 242 "RESERVED" 243 "RESERVED" 244 "RESERVED" 245 "RESERVED" 246 "RESERVED" 247 "RESERVED" 248 "RESERVED" 249 "RESERVED" 250 "RESERVED" 251 "RESERVED" 252 "RESERVED" 253 "RESERVED" 254 "RESERVED" 255 "ERROR" ;
VAL_ 3221225472 L_ATCU_RrBlwFltSta 0 "Normal" 1 "Blower Fault" ;
VAL_ 3221225472 RHPTC_FlrFlt 0 "Normal" 1 "Fault" ;
VAL_ 3221225472 RHPTC_FlrFltLVLow 0 "Normal" 1 "Fault" ;
VAL_ 3221225472 RHPTC_FlrFailLVSnr 0 "Normal" 1 "Message Timeout" ;
VAL_ 3221225472 RHPTC_FlrFailCuFLRentSnr 0 "Normal" 1 "Fault(Open or Short)" ;
VAL_ 3221225472 RHPTC_FlrrFailCoreTempSnr 0 "Normal" 1 "Fault(Open or Short)" ;
VAL_ 3221225472 RHPTC_FlrFailPcbTempSnr 0 "Normal" 1 "Fault(Open or Short)" ;
VAL_ 3221225472 RHPTC_FlrFailIGBT 0 "Normal" 1 "Fault(Open or Short)" ;
VAL_ 3221225472 RHPTC_FlrFailOpenLoad 0 "Normal" 1 "Fault(Open or Short)" ;
VAL_ 3221225472 RHPTC_FlrLtdOpCause 0 "Normal" 1 "Fault" ;
VAL_ 3221225472 RHPTC_FlrFltLVHigh 0 "Normal" 1 "Fault" ;
VAL_ 3221225472 RHPTC_FlrSwrVer 0 "Normal" 1 "Fault" ;
VAL_ 3221225472 RHPTC_FlrFltHVLow 0 "Normal" 1 "Fault" ;
VAL_ 3221225472 RHPTC_FlrFltHVHigh 0 "Normal" 1 "Fault" ;
VAL_ 3221225472 RHPTC_FlrFltOverCuFLRent 0 "Normal" 1 "Fault" ;
VAL_ 3221225472 RHPTC_FlrFltThermalShutDn 0 "Normal" 1 "Fault" ;
VAL_ 3221225472 RHPTC_FlrFltPcbThermalShutDn 0 "Normal" 1 "Fault" ;
VAL_ 3221225472 RHPTC_FlrFltMsgTmOutATCU 0 "Normal" 1 "Fault" ;
VAL_ 3221225472 RHPTC_FlrFailHVSnr 0 "Normal" 1 "Fault" ;
VAL_ 3221225472 RHPTC_FlrRdySta 0 "Not Ready(Disable to control)" 1 "Ready (Enable to Control)" ;
VAL_ 3221225472 RHPTC_FlrOpSta 0 "Stop Mode" 1 "Operation Mode" 2 "Failure Mode" 3 "Limited operation Mode" ;
VAL_ 3221225472 RHPTC_FlrCnsmptPwr_W 0 "Single PTC & Single Control" 1 "Dual PTC & Single Control" 2 "Dual PTC & Dual Control" 3 "RESERVED" 4 "RESERVED" 5 "RESERVED" 6 "RESERVED" 7 "RESERVED" ;
VAL_ 3221225472 RHPTC_FlrCtrlTyp 0 "Not Ready(Disable to control)" 1 "Ready (Enable to Control)" ;
VAL_ 3221225472 RHPTC_FlrVoltage_V 0 "Temperature" 1 "Temperature" 2 "Temperature" 3 "Temperature" 4 "Temperature" 5 "Temperature" 6 "Temperature" 7 "Temperature" 8 "Temperature" 9 "Temperature" 10 "Temperature" 11 "Temperature" 12 "Temperature" 13 "Temperature" 14 "Temperature" 15 "Temperature" 241 "RESERVED" 242 "RESERVED" 243 "RESERVED" 244 "RESERVED" 245 "RESERVED" 246 "RESERVED" 247 "RESERVED" 248 "RESERVED" 249 "RESERVED" 250 "RESERVED" 251 "RESERVED" 252 "RESERVED" 253 "The thermister is open" 254 "The thermister is short" 255 "Error" ;
VAL_ 3221225472 RHPTC_FlrCuFlrent_A 255 "ERROR" ;
VAL_ 3221225472 RHPTC_FlrDutyFB_Pec 0 "0x0x0~0xFA:Voltage" 250 "0x0x0~0xFA:Voltage" 251 "RESERVED" 252 "RESERVED" 253 "RESERVED" 254 "RESERVED" 255 "ERROR" ;
VAL_ 3221225472 RHPTC_FlrDutyFB_IGBT 0 "0x0x0~0xFA:Current" 250 "0x0x0~0xFA:Current" 251 "RESERVED" 252 "RESERVED" 253 "RESERVED" 254 "RESERVED" 255 "ERROR" ;
VAL_ 3221225472 RHPTC_FlrCoreTemp_C 0 "Stop Mode" 1 "Operation Mode" 2 "Failure Mode" 3 "Limited operation Mode" ;
VAL_ 3221225472 RHPTC_RoofFlt 0 "Normal" 1 "Fault" ;
VAL_ 3221225472 RHPTC_RoofFltLVLow 0 "Normal" 1 "Fault" ;
VAL_ 3221225472 RHPTC_RoofFailLVSnr 0 "Normal" 1 "Fault(Open or Short)" ;
VAL_ 3221225472 RHPTC_RoofFailCuRoofentSnr 0 "Normal" 1 "Fault(Open or Short)" ;
VAL_ 3221225472 RHPTC_RoofFailCoreTempSnr 0 "Normal" 1 "Fault(Open or Short)" ;
VAL_ 3221225472 RHPTC_RoofFailPcbTempSnr 0 "Normal" 1 "Fault(Open or Short)" ;
VAL_ 3221225472 RHPTC_RoofFailIGBT 0 "Normal" 1 "Fault" ;
VAL_ 3221225472 RHPTC_RoofFailOpenLoad 0 "Normal" 1 "Fault" ;
VAL_ 3221225472 RHPTC_RoofLtdOpCause 0 "Normal Operation" 1 "Ltd Operation by LVLowDr" 2 "Ltd Operation by LVHighDr" 3 "Ltd Operation by HVLowDr" 4 "Ltd Operation by HVHighDr" 5 "Ltd Operation by OverCurrentDr" 8 "Ltd Operation by ThermalShutDnDr" 9 "Ltd Operation by PCBThermalShutDnDr" 10 "0xA~0xFF:RESERVED" 255 "0xA~0xFF:RESERVED" ;
VAL_ 3221225472 RHPTC_RoofFltLVHigh 0 "Normal" 1 "Fault" ;
VAL_ 3221225472 RHPTC_RoofSwVer 0 "0x0x0~0xFF" 255 "0x0x0~0xFF" ;
VAL_ 3221225472 RHPTC_RoofFltHVLow 0 "Normal" 1 "Fault" ;
VAL_ 3221225472 RHPTC_CnsmptPwrTtl_W 0 "0x0x0~0x2710:Power" 10000 "0x0x0~0x2710:Power" 65535 "ERROR" ;
VAL_ 3221225472 RHPTC_RoofFltHVHigh 0 "Normal" 1 "Fault" ;
VAL_ 3221225472 RHPTC_IntlkSta 0 "Disconnect" 1 "Connect" 2 "Not Used" 3 "Error Indicator" ;
VAL_ 3221225472 RHPTC_RoofFltOverCuRoofent 0 "Normal" 1 "Fault" ;
VAL_ 3221225472 RHPTC_RoofFltThermalShutDn 0 "Normal" 1 "Fault" ;
VAL_ 3221225472 RHPTC_RoofFltPcbThermalShutDn 0 "Normal" 1 "Fault" ;
VAL_ 3221225472 RHPTC_RoofFltMsgTmOutATCU 0 "Normal" 1 "Message Timeout" ;
VAL_ 3221225472 RHPTC_RoofFailHVSnr 0 "Normal" 1 "Fault(Open or Short)" ;
VAL_ 3221225472 RHPTC_RoofRdySta 0 "Not Ready(Disable to control)" 1 "Ready (Enable to Control)" ;
VAL_ 3221225472 RHPTC_RoofOpSta 0 "Stop Mode" 1 "Operation Mode" 2 "Failure Mode" 3 "Limited operation Mode" ;
VAL_ 3221225472 RHPTC_RoofCnsmptPwr_W 0 "0x0x0~0x2710:Power" 10000 "0x0x0~0x2710:Power" 65535 "ERROR" ;
VAL_ 3221225472 RHPTC_RoofVoltage_V 0 "0x0x0~0xFA:Voltage" 250 "0x0x0~0xFA:Voltage" 251 "RESERVED" 252 "RESERVED" 253 "RESERVED" 254 "RESERVED" 255 "ERROR" ;
VAL_ 3221225472 RHPTC_RoofCtrlTyp 0 "Single PTC & Single Control" 1 "Dual PTC & Single Control" 2 "Dual PTC & Dual Control" 3 "RESERVED" 4 "RESERVED" 5 "RESERVED" 6 "RESERVED" 7 "RESERVED" ;
VAL_ 3221225472 RHPTC_RoofCuRoofent_A 0 "0x0x0~0xFA:Current" 250 "0x0x0~0xFA:Current" 251 "RESERVED" 252 "RESERVED" 253 "RESERVED" 254 "RESERVED" 255 "ERROR" ;
VAL_ 3221225472 RHPTC_RoofDutyFB_Pec 0 "0x0x0~0xC8:Duty" 200 "0x0x0~0xC8:Duty" 201 "resreved" 202 "resreved" 203 "resreved" 204 "resreved" 205 "resreved" 206 "resreved" 207 "resreved" 208 "resreved" 209 "resreved" 210 "resreved" 211 "resreved" 212 "resreved" 213 "resreved" 214 "resreved" 215 "resreved" 216 "resreved" 217 "resreved" 218 "resreved" 219 "resreved" 220 "resreved" 221 "resreved" 222 "resreved" 223 "resreved" 224 "resreved" 225 "resreved" 226 "resreved" 227 "resreved" 228 "resreved" 229 "resreved" 230 "resreved" 231 "resreved" 232 "resreved" 233 "resreved" 234 "resreved" 235 "resreved" 236 "resreved" 237 "resreved" 238 "resreved" 239 "resreved" 240 "resreved" 241 "resreved" 242 "resreved" 243 "resreved" 244 "resreved" 245 "resreved" 246 "resreved" 247 "resreved" 248 "resreved" 249 "resreved" 250 "resreved" 251 "resreved" 252 "resreved" 253 "resreved" 254 "resreved" 255 "ERROR" ;
VAL_ 3221225472 RHPTC_RoofDutyFB_IGBT 0 "0x0x0~0xC8:Duty" 200 "0x0x0~0xC8:Duty" 201 "RESERVED" 202 "RESERVED" 203 "RESERVED" 204 "RESERVED" 205 "RESERVED" 206 "RESERVED" 207 "RESERVED" 208 "RESERVED" 209 "RESERVED" 210 "RESERVED" 211 "RESERVED" 212 "RESERVED" 213 "RESERVED" 214 "RESERVED" 215 "RESERVED" 216 "RESERVED" 217 "RESERVED" 218 "RESERVED" 219 "RESERVED" 220 "RESERVED" 221 "RESERVED" 222 "RESERVED" 223 "RESERVED" 224 "RESERVED" 225 "RESERVED" 226 "RESERVED" 227 "RESERVED" 228 "RESERVED" 229 "RESERVED" 230 "RESERVED" 231 "RESERVED" 232 "RESERVED" 233 "RESERVED" 234 "RESERVED" 235 "RESERVED" 236 "RESERVED" 237 "RESERVED" 238 "RESERVED" 239 "RESERVED" 240 "RESERVED" 241 "RESERVED" 242 "RESERVED" 243 "RESERVED" 244 "RESERVED" 245 "RESERVED" 246 "RESERVED" 247 "RESERVED" 248 "RESERVED" 249 "RESERVED" 250 "RESERVED" 251 "RESERVED" 252 "RESERVED" 253 "RESERVED" 254 "RESERVED" 255 "ERROR" ;
VAL_ 3221225472 RHPTC_RoofCoreTemp_C 0 "Temperature" 1 "Temperature" 2 "Temperature" 3 "Temperature" 4 "Temperature" 5 "Temperature" 6 "Temperature" 7 "Temperature" 8 "Temperature" 9 "Temperature" 10 "Temperature" 11 "Temperature" 12 "Temperature" 13 "Temperature" 14 "Temperature" 15 "Temperature" 241 "RESERVED" 242 "RESERVED" 243 "RESERVED" 244 "RESERVED" 245 "RESERVED" 246 "RESERVED" 247 "RESERVED" 248 "RESERVED" 249 "RESERVED" 250 "RESERVED" 251 "RESERVED" 252 "RESERVED" 253 "The thermister is open" 254 "The thermister is short" 255 "Error" ;
VAL_ 1332 L_ATCU_FHPTCOpPrmssnSta 0 "Not Permiited" 1 "Permitted" ;
VAL_ 1332 L_ATCU_xEV_BMSRomTyp 0 "No Definition" 1 "Normal Battery Pack with Heater System" 2 "Normal Battery Pack without Heater System" 3 "Economy Battery Pack with Heater System" 4 "Economy Battery Pack without Heater System" 5 "Extented Battery Pack with Heater System" 6 "Extented Battery Pack without Heater System" ;
VAL_ 1332 L_ATCU_FHPTCPassTrgtDty 0 "0x0x0~0xC8:Duty" 200 "0x0x0~0xC8:Duty" 201 "RESERVED" 202 "RESERVED" 203 "RESERVED" 204 "RESERVED" 205 "RESERVED" 206 "RESERVED" 207 "RESERVED" 208 "RESERVED" 209 "RESERVED" 210 "RESERVED" 211 "RESERVED" 212 "RESERVED" 213 "RESERVED" 214 "RESERVED" 215 "RESERVED" 216 "RESERVED" 217 "RESERVED" 218 "RESERVED" 219 "RESERVED" 220 "RESERVED" 221 "RESERVED" 222 "RESERVED" 223 "RESERVED" 224 "RESERVED" 225 "RESERVED" 226 "RESERVED" 227 "RESERVED" 228 "RESERVED" 229 "RESERVED" 230 "RESERVED" 231 "RESERVED" 232 "RESERVED" 233 "RESERVED" 234 "RESERVED" 235 "RESERVED" 236 "RESERVED" 237 "RESERVED" 238 "RESERVED" 239 "RESERVED" 240 "RESERVED" 241 "RESERVED" 242 "RESERVED" 243 "RESERVED" 244 "RESERVED" 245 "RESERVED" 246 "RESERVED" 247 "RESERVED" 248 "RESERVED" 249 "RESERVED" 250 "RESERVED" 251 "RESERVED" 252 "RESERVED" 253 "RESERVED" 254 "RESERVED" 255 "ERROR" ;
VAL_ 1332 L_ATCU_FHPTCDischrgReq 0 "Non-Request" 1 "Request" ;
VAL_ 1332 L_ATCU_FltMsgTmOutFHPTC1 0 "Normal" 1 "Message Timeout" ;
VAL_ 1332 L_ATCU_FltMsgTmOutFHPTC2 0 "Normal" 1 "Message Timeout" ;
VAL_ 1332 L_ATCU_FltMsgTmOutFHPTC3 0 "Normal" 1 "Message Timeout" ;
VAL_ 1332 L_ATCU_FltMsgTmOutFHPTC4 0 "Normal" 1 "Message Timeout" ;
VAL_ 1332 L_ATCU_FrBlwLvl 0 "OFF" 1 "0 level" 2 "1 level" 3 "2 level" 4 "3 level" 5 "4 level" 6 "5 level" 7 "6 level" 8 "7 evel" 9 "8 level" 10 "RESERVED" 11 "RESERVED" 12 "RESERVED" 13 "RESERVED" 14 "RESERVED" 15 "Error Indicator" ;
VAL_ 1332 L_ATCU_FrBlwLvlSigVaildSta 0 "Invaild (Blower Level Info Not supported)" 1 "Vaild (Blower Level Info Supported) (Initial Value:0H)" ;
VAL_ 1332 L_ATCU_OutTempSnsrVal 255 "Error" ;
VAL_ 1332 L_ATCU_DrvrSdTyp 0 "LHD" 1 "RHD" ;
VAL_ 1332 L_ATCU_FrBlwFltSta 0 "Normal" 1 "Blower Fault" ;
VAL_ 1332 L_ATCU_PassBlwLvl 0 "OFF(Default)" 1 "0 Level" 2 "1 Level" 3 "2 Level" 4 "3 Level" 5 "4 Level" 6 "5 Level" 7 "6 Level" 8 "7 Level" 9 "8 Level" 10 "RESERVED" 11 "RESERVED" 12 "RESERVED" 13 "RESERVED" 14 "RESERVED" 15 "Error Indicator" ;
VAL_ 1332 L_ATCU_FHPTCDrTrgtDty 0 "0x0x0~0xC8:Duty" 200 "0x0x0~0xC8:Duty" 201 "RESERVED" 202 "RESERVED" 203 "RESERVED" 204 "RESERVED" 205 "RESERVED" 206 "RESERVED" 207 "RESERVED" 208 "RESERVED" 209 "RESERVED" 210 "RESERVED" 211 "RESERVED" 212 "RESERVED" 213 "RESERVED" 214 "RESERVED" 215 "RESERVED" 216 "RESERVED" 217 "RESERVED" 218 "RESERVED" 219 "RESERVED" 220 "RESERVED" 221 "RESERVED" 222 "RESERVED" 223 "RESERVED" 224 "RESERVED" 225 "RESERVED" 226 "RESERVED" 227 "RESERVED" 228 "RESERVED" 229 "RESERVED" 230 "RESERVED" 231 "RESERVED" 232 "RESERVED" 233 "RESERVED" 234 "RESERVED" 235 "RESERVED" 236 "RESERVED" 237 "RESERVED" 238 "RESERVED" 239 "RESERVED" 240 "RESERVED" 241 "RESERVED" 242 "RESERVED" 243 "RESERVED" 244 "RESERVED" 245 "RESERVED" 246 "RESERVED" 247 "RESERVED" 248 "RESERVED" 249 "RESERVED" 250 "RESERVED" 251 "RESERVED" 252 "RESERVED" 253 "RESERVED" 254 "RESERVED" 255 "ERROR" ;
VAL_ 273 L_ATCU_FHPTCOpPrmssnSta 0 "Not Permiited" 1 "Permitted" ;
VAL_ 273 L_ATCU_xEV_BMSRomTyp 0 "No Definition" 1 "Normal Battery Pack with Heater System" 2 "Normal Battery Pack without Heater System" 3 "Economy Battery Pack with Heater System" 4 "Economy Battery Pack without Heater System" 5 "Extented Battery Pack with Heater System" 6 "Extented Battery Pack without Heater System" ;
VAL_ 273 L_ATCU_FHPTCPassTrgtDty 0 "0x0x0~0xC8:Duty" 200 "0x0x0~0xC8:Duty" 201 "RESERVED" 202 "RESERVED" 203 "RESERVED" 204 "RESERVED" 205 "RESERVED" 206 "RESERVED" 207 "RESERVED" 208 "RESERVED" 209 "RESERVED" 210 "RESERVED" 211 "RESERVED" 212 "RESERVED" 213 "RESERVED" 214 "RESERVED" 215 "RESERVED" 216 "RESERVED" 217 "RESERVED" 218 "RESERVED" 219 "RESERVED" 220 "RESERVED" 221 "RESERVED" 222 "RESERVED" 223 "RESERVED" 224 "RESERVED" 225 "RESERVED" 226 "RESERVED" 227 "RESERVED" 228 "RESERVED" 229 "RESERVED" 230 "RESERVED" 231 "RESERVED" 232 "RESERVED" 233 "RESERVED" 234 "RESERVED" 235 "RESERVED" 236 "RESERVED" 237 "RESERVED" 238 "RESERVED" 239 "RESERVED" 240 "RESERVED" 241 "RESERVED" 242 "RESERVED" 243 "RESERVED" 244 "RESERVED" 245 "RESERVED" 246 "RESERVED" 247 "RESERVED" 248 "RESERVED" 249 "RESERVED" 250 "RESERVED" 251 "RESERVED" 252 "RESERVED" 253 "RESERVED" 254 "RESERVED" 255 "ERROR" ;
VAL_ 273 L_ATCU_FHPTCDischrgReq 0 "Non-Request" 1 "Request" ;
VAL_ 273 L_ATCU_FltMsgTmOutFHPTC1 0 "Normal" 1 "Message Timeout" ;
VAL_ 273 L_ATCU_FltMsgTmOutFHPTC2 0 "Normal" 1 "Message Timeout" ;
VAL_ 273 L_ATCU_FltMsgTmOutFHPTC3 0 "Normal" 1 "Message Timeout" ;
VAL_ 273 L_ATCU_FltMsgTmOutFHPTC4 0 "Normal" 1 "Message Timeout" ;
VAL_ 273 L_ATCU_FrBlwLvl 0 "OFF" 1 "0 level" 2 "1 level" 3 "2 level" 4 "3 level" 5 "4 level" 6 "5 level" 7 "6 level" 8 "7 evel" 9 "8 level" 10 "RESERVED" 11 "RESERVED" 12 "RESERVED" 13 "RESERVED" 14 "RESERVED" 15 "Error Indicator" ;
VAL_ 273 L_ATCU_FrBlwLvlSigVaildSta 0 "Invaild (Blower Level Info Not supported)" 1 "Vaild (Blower Level Info Supported) (Initial Value:0H)" ;
VAL_ 273 L_ATCU_OutTempSnsrVal 255 "Error" ;
VAL_ 273 L_ATCU_DrvrSdTyp 0 "LHD" 1 "RHD" ;
VAL_ 273 L_ATCU_FrBlwFltSta 0 "Normal" 1 "Blower Fault" ;
VAL_ 273 L_ATCU_PassBlwLvl 0 "OFF(Default)" 1 "0 Level" 2 "1 Level" 3 "2 Level" 4 "3 Level" 5 "4 Level" 6 "5 Level" 7 "6 Level" 8 "7 Level" 9 "8 Level" 10 "RESERVED" 11 "RESERVED" 12 "RESERVED" 13 "RESERVED" 14 "RESERVED" 15 "Error Indicator" ;
VAL_ 273 L_ATCU_FHPTCDrTrgtDty 0 "0x0x0~0xC8:Duty" 200 "0x0x0~0xC8:Duty" 201 "RESERVED" 202 "RESERVED" 203 "RESERVED" 204 "RESERVED" 205 "RESERVED" 206 "RESERVED" 207 "RESERVED" 208 "RESERVED" 209 "RESERVED" 210 "RESERVED" 211 "RESERVED" 212 "RESERVED" 213 "RESERVED" 214 "RESERVED" 215 "RESERVED" 216 "RESERVED" 217 "RESERVED" 218 "RESERVED" 219 "RESERVED" 220 "RESERVED" 221 "RESERVED" 222 "RESERVED" 223 "RESERVED" 224 "RESERVED" 225 "RESERVED" 226 "RESERVED" 227 "RESERVED" 228 "RESERVED" 229 "RESERVED" 230 "RESERVED" 231 "RESERVED" 232 "RESERVED" 233 "RESERVED" 234 "RESERVED" 235 "RESERVED" 236 "RESERVED" 237 "RESERVED" 238 "RESERVED" 239 "RESERVED" 240 "RESERVED" 241 "RESERVED" 242 "RESERVED" 243 "RESERVED" 244 "RESERVED" 245 "RESERVED" 246 "RESERVED" 247 "RESERVED" 248 "RESERVED" 249 "RESERVED" 250 "RESERVED" 251 "RESERVED" 252 "RESERVED" 253 "RESERVED" 254 "RESERVED" 255 "ERROR" ;
VAL_ 322 FHPTC_PassRdySta 0 "Not Ready(Disable to control)" 1 "Ready (Enable to Control)" ;
VAL_ 322 FHPTC_PassOpSta 0 "Stop Mode" 1 "Operation Mode" 2 "Failure Mode" 3 "Limited operation Mode" ;
VAL_ 322 FHPTC_PassCnsmptPwr_W 0 "0x0x0~0x2710:Power" 10000 "0x0x0~0x2710:Power" 65535 "ERROR" ;
VAL_ 322 FHPTC_PassCtrlTyp 0 "Single PTC & Single Control" 1 "Dual PTC & Single Control" 2 "Dual PTC & Dual Control" ;
VAL_ 322 FHPTC_PassVoltage_V 0 "0x0x0~0xFA:Voltage" 250 "0x0x0~0xFA:Voltage" 251 "RESERVED0xFF:ERROR" 252 "RESERVED0xFF:ERROR" 253 "RESERVED0xFF:ERROR" 254 "RESERVED0xFF:ERROR" ;
VAL_ 322 FHPTC_PassCurrent_A 0 "0x0x0~0xFA:Current" 250 "0x0x0~0xFA:Current" 251 "RESERVED" 252 "RESERVED" 253 "RESERVED" 254 "RESERVED" 255 "ERROR" ;
VAL_ 322 FHPTC_PassDutyFB_Pec 0 "0x0x0~0xC8:Duty" 200 "0x0x0~0xC8:Duty" 201 "RESERVED" 202 "RESERVED" 203 "RESERVED" 204 "RESERVED" 205 "RESERVED" 206 "RESERVED" 207 "RESERVED" 208 "RESERVED" 209 "RESERVED" 210 "RESERVED" 211 "RESERVED" 212 "RESERVED" 213 "RESERVED" 214 "RESERVED" 215 "RESERVED" 216 "RESERVED" 217 "RESERVED" 218 "RESERVED" 219 "RESERVED" 220 "RESERVED" 221 "RESERVED" 222 "RESERVED" 223 "RESERVED" 224 "RESERVED" 225 "RESERVED" 226 "RESERVED" 227 "RESERVED" 228 "RESERVED" 229 "RESERVED" 230 "RESERVED" 231 "RESERVED" 232 "RESERVED" 233 "RESERVED" 234 "RESERVED" 235 "RESERVED" 236 "RESERVED" 237 "RESERVED" 238 "RESERVED" 239 "RESERVED" 240 "RESERVED" 241 "RESERVED" 242 "RESERVED" 243 "RESERVED" 244 "RESERVED" 245 "RESERVED" 246 "RESERVED" 247 "RESERVED" 248 "RESERVED" 249 "RESERVED" 250 "RESERVED" 251 "RESERVED" 252 "RESERVED" 253 "RESERVED" 254 "RESERVED" 255 "ERROR" ;
VAL_ 322 FHPTC_PassDutyFB_IGBT 0 "0x0x0~0xC8:Duty" 200 "0x0x0~0xC8:Duty" 201 "RESERVED" 202 "RESERVED" 203 "RESERVED" 204 "RESERVED" 205 "RESERVED" 206 "RESERVED" 207 "RESERVED" 208 "RESERVED" 209 "RESERVED" 210 "RESERVED" 211 "RESERVED" 212 "RESERVED" 213 "RESERVED" 214 "RESERVED" 215 "RESERVED" 216 "RESERVED" 217 "RESERVED" 218 "RESERVED" 219 "RESERVED" 220 "RESERVED" 221 "RESERVED" 222 "RESERVED" 223 "RESERVED" 224 "RESERVED" 225 "RESERVED" 226 "RESERVED" 227 "RESERVED" 228 "RESERVED" 229 "RESERVED" 230 "RESERVED" 231 "RESERVED" 232 "RESERVED" 233 "RESERVED" 234 "RESERVED" 235 "RESERVED" 236 "RESERVED" 237 "RESERVED" 238 "RESERVED" 239 "RESERVED" 240 "RESERVED" 241 "RESERVED" 242 "RESERVED" 243 "RESERVED" 244 "RESERVED" 245 "RESERVED" 246 "RESERVED" 247 "RESERVED" 248 "RESERVED" 249 "RESERVED" 250 "RESERVED" 251 "RESERVED" 252 "RESERVED" 253 "RESERVED" 254 "RESERVED" 255 "ERROR" ;
VAL_ 322 FHPTC_PassCoreTemp_C 0 "0x0x0~0xF0:Temperature" 240 "0x0x0~0xF0:Temperature" 241 "RESERVED/0XFD:The thermister is open" 242 "RESERVED/0XFD:The thermister is open" 243 "RESERVED/0XFD:The thermister is open" 244 "RESERVED/0XFD:The thermister is open" 245 "RESERVED/0XFD:The thermister is open" 246 "RESERVED/0XFD:The thermister is open" 247 "RESERVED/0XFD:The thermister is open" 248 "RESERVED/0XFD:The thermister is open" 249 "RESERVED/0XFD:The thermister is open" 250 "RESERVED/0XFD:The thermister is open" 251 "RESERVED/0XFD:The thermister is open" 252 "RESERVED/0XFD:The thermister is open" 254 "The thermister is short" 255 "ERROR" ;
VAL_ 323 FHPTC_PassLogHalt 1 "Fault '0x1'" 0 "Narmal '0x0'" ;
VAL_ 323 FHPTC_PassFlt 0 "Normal" 1 "Fault" ;
VAL_ 323 FHPTC_PassFltLVLow 0 "Normal" 1 "Fault" ;
VAL_ 323 FHPTC_PassFailLVSnr 0 "Normal" 1 "Fault(Open or Short)" ;
VAL_ 323 FHPTC_PassFailCurrentSnr 0 "Normal" 1 "Fault(Open or Short)" ;
VAL_ 323 FHPTC_PassFailCoreTempSnr 0 "Normal" 1 "Fault(Open or Short)" ;
VAL_ 323 FHPTC_PassFailPcbTempSnr 0 "Normal" 1 "Fault(Open or Short)" ;
VAL_ 323 FHPTC_PassFailIGBT 0 "Normal" 1 "Fault" ;
VAL_ 323 FHPTC_PassFailOpenLoad 0 "Normal" 1 "Fault" ;
VAL_ 323 FHPTC_PassLtdOpCause 0 "Normal Operation" 1 "Ltd Operation by LVLowDr" 2 "Ltd Operation by LVHighDr" 3 "Ltd Operation by HVLowDr" 4 "Ltd Operation by HVHighDr" 5 "Ltd Operation by OverCurrentDr" ;
VAL_ 323 FHPTC_PassFltLVHigh 0 "Normal" 1 "Fault" ;
VAL_ 323 FHPTC_PassFltHVLow 0 "Normal" 1 "Fault" ;
VAL_ 323 FHPTC_PassFltHVHigh 0 "Normal" 1 "Fault" ;
VAL_ 323 FHPTC_PassFltOverCurrent 0 "Normal" 1 "Fault" ;
VAL_ 323 FHPTC_PassFltThermalShutDn 0 "Normal" 1 "Fault" ;
VAL_ 323 FHPTC_PassFltPcbThermalShutDn 0 "Normal" 1 "Fault" ;
VAL_ 323 FHPTC_PassFltMsgTmOutATCU 0 "Normal" 1 "Message Timeout" ;
VAL_ 323 FHPTC_PassFailHVSnr 0 "Normal" 1 "Fault(Open or Short)" ;
VAL_ 320 FHPTC_DrRdySta 0 "Not Ready(Disable to control)" 1 "Ready (Enable to Control)" ;
VAL_ 320 FHPTC_DrOpSta 0 "Stop Mode" 1 "Operation Mode" 2 "Failure Mode" 3 "Limited operation Mode" ;
VAL_ 320 FHPTC_DrCnsmptPwr_W 0 "0x0x0~0x2710:Power" 10000 "0x0x0~0x2710:Power" 65535 "ERROR" ;
VAL_ 320 FHPTC_DrCurrent_A 0 "0x0x0~0xFA:Current" 250 "0x0x0~0xFA:Current" 251 "RESERVED" 252 "RESERVED" 253 "RESERVED" 254 "RESERVED" 255 "ERROR" ;
VAL_ 320 FHPTC_DrCoreTemp_C 0 "0x0x00~0xF0:Temperature" 240 "0x0x00~0xF0:Temperature" 241 "RESERVED" 242 "RESERVED" 243 "RESERVED" 244 "RESERVED" 245 "RESERVED" 246 "RESERVED" 247 "RESERVED" 248 "RESERVED" 249 "RESERVED" 250 "RESERVED" 251 "RESERVED" 252 "RESERVED" 253 "The thermister is open." 254 "The thermister is short." 255 "ERROR" ;
VAL_ 320 FHPTC_DrDutyFB_Pec 0 "0x0x0~0xC8:Duty" 200 "0x0x0~0xC8:Duty" 201 "RESERVED" 202 "RESERVED" 203 "RESERVED" 204 "RESERVED" 205 "RESERVED" 206 "RESERVED" 207 "RESERVED" 208 "RESERVED" 209 "RESERVED" 210 "RESERVED" 211 "RESERVED" 212 "RESERVED" 213 "RESERVED" 214 "RESERVED" 215 "RESERVED" 216 "RESERVED" 217 "RESERVED" 218 "RESERVED" 219 "RESERVED" 220 "RESERVED" 221 "RESERVED" 222 "RESERVED" 223 "RESERVED" 224 "RESERVED" 225 "RESERVED" 226 "RESERVED" 227 "RESERVED" 228 "RESERVED" 229 "RESERVED" 230 "RESERVED" 231 "RESERVED" 232 "RESERVED" 233 "RESERVED" 234 "RESERVED" 235 "RESERVED" 236 "RESERVED" 237 "RESERVED" 238 "RESERVED" 239 "RESERVED" 240 "RESERVED" 241 "RESERVED" 242 "RESERVED" 243 "RESERVED" 244 "RESERVED" 245 "RESERVED" 246 "RESERVED" 247 "RESERVED" 248 "RESERVED" 249 "RESERVED" 250 "RESERVED" 251 "RESERVED" 252 "RESERVED" 253 "RESERVED" 254 "RESERVED" 255 "ERROR" ;
VAL_ 320 FHPTC_DrDutyFB_IGBT 0 "0x0x0~0xC8:Duty" 200 "0x0x0~0xC8:Duty" 201 "RESERVED" 202 "RESERVED" 203 "RESERVED" 204 "RESERVED" 205 "RESERVED" 206 "RESERVED" 207 "RESERVED" 208 "RESERVED" 209 "RESERVED" 210 "RESERVED" 211 "RESERVED" 212 "RESERVED" 213 "RESERVED" 214 "RESERVED" 215 "RESERVED" 216 "RESERVED" 217 "RESERVED" 218 "RESERVED" 219 "RESERVED" 220 "RESERVED" 221 "RESERVED" 222 "RESERVED" 223 "RESERVED" 224 "RESERVED" 225 "RESERVED" 226 "RESERVED" 227 "RESERVED" 228 "RESERVED" 229 "RESERVED" 230 "RESERVED" 231 "RESERVED" 232 "RESERVED" 233 "RESERVED" 234 "RESERVED" 235 "RESERVED" 236 "RESERVED" 237 "RESERVED" 238 "RESERVED" 239 "RESERVED" 240 "RESERVED" 241 "RESERVED" 242 "RESERVED" 243 "RESERVED" 244 "RESERVED" 245 "RESERVED" 246 "RESERVED" 247 "RESERVED" 248 "RESERVED" 249 "RESERVED" 250 "RESERVED" 251 "RESERVED" 252 "RESERVED" 253 "RESERVED" 254 "RESERVED" 255 "ERROR" ;
VAL_ 320 FHPTC_DrCtrlTyp 0 "Single PTC & Single Control" 1 "Dual PTC & Single Control" 2 "Dual PTC & Dual Control" ;
VAL_ 320 FHPTC_DrVoltage_V 0 "0x0x0~0xFA:Voltage" 250 "0x0x0~0xFA:Voltage" 251 "RESERVED" 252 "RESERVED" 253 "RESERVED" 254 "RESERVED" 255 "ERROR" ;
VAL_ 321 FHPTC_DrLogHalt 1 "Fault '0x1'" 0 "Narmal '0x0'" ;
VAL_ 321 FHPTC_DrFlt 0 "Normal" 1 "Fault" ;
VAL_ 321 FHPTC_DrFltLVLow 0 "Normal" 1 "Fault" ;
VAL_ 321 FHPTC_DrFailLVSnr 0 "Normal" 1 "Fault(Open or Short)" ;
VAL_ 321 FHPTC_DrFailCurrentSnr 0 "Normal" 1 "Fault(Open or Short)" ;
VAL_ 321 FHPTC_DrFailCoreTempSnr 0 "Normal" 1 "Fault(Open or Short)" ;
VAL_ 321 FHPTC_DrFailPcbTempSnr 0 "Normal" 1 "Fault(Open or Short)" ;
VAL_ 321 FHPTC_DrFailIGBT 0 "Normal" 1 "Fault" ;
VAL_ 321 FHPTC_DrFailOpenLoad 0 "Normal" 1 "Fault" ;
VAL_ 321 FHPTC_DrLtdOpCause 0 "Normal Operation" 1 "Ltd Operation by LVLowDr" 2 "Ltd Operation by LVHighDr" 3 "Ltd Operation by HVLowDr" 4 "Ltd Operation by HVHighDr" 5 "Ltd Operation by OverCurrentDr" 8 "Ltd Operation by ThermalShutDnDr" 9 "Ltd Operation by PCBThermalShutDnDr" 10 "0xA~0xFF:RESERVED" 255 "0xA~0xFF:RESERVED" ;
VAL_ 321 FHPTC_DrFltLVHigh 0 "Normal" 1 "Fault" ;
VAL_ 321 FHPTC_DrFltHVLow 0 "Normal" 1 "Fault" ;
VAL_ 321 FHPTC_CnsmptPwrTtl_W 0 "0x0x0~0x2710:Power" 10000 "0x0x0~0x2710:Power" 65535 "ERROR" ;
VAL_ 321 FHPTC_DrFltHVHigh 0 "Normal" 1 "Fault" ;
VAL_ 321 FHPTC_IntlkSta 0 "Disconnect" 1 "Connect" 2 "Not Used" 3 "Error Indicator" ;
VAL_ 321 FHPTC_DrFltOverCurrent 0 "Normal" 1 "Fault" ;
VAL_ 321 FHPTC_DrFltThermalShutDn 0 "Normal" 1 "Fault" ;
VAL_ 321 FHPTC_DrFltPcbThermalShutDn 0 "Normal" 1 "Fault" ;
VAL_ 321 FHPTC_DrFltMsgTmOutATCU 0 "Normal" 1 "Message Timeout" ;
VAL_ 321 FHPTC_DrFailHVSnr 0 "Normal" 1 "Fault(Open or Short)" ;
